VERSION ""

NS_ :

BS_:

BU_: AVM_SD CGW IVI eHBox

BO_ 32 ACU_A102: 8 CGW
  SG_ AirbagCrashOrder_v3 : 5|6@0+ (1,0) [0|0] "" IVI

BO_ 116 ECM_A110: 8 CGW
  SG_ PowerTrainSetPoint : 11|10@0+ (0.125,0) [0|125] "%" IVI
  SG_ RawSensor : 17|10@0+ (0.125,0) [0|125] "%" IVI
  SG_ StopAutoPhase : 47|3@0+ (1,0) [0|0] "" IVI

BO_ 117 ECM_A112: 8 CGW
  SG_ ECM_EstimatedPWTWheelTorque : 11|15@0+ (2,-20000) [-20000|20000] "Nm" IVI
  SG_ PowerTrainStatus : 25|2@0+ (1,0) [0|0] "" IVI
  SG_ EngineRPM : 39|16@0+ (0.125,0) [0|8191.75] "rpm" IVI
  SG_ MeanEffectiveTorque : 55|12@0+ (0.5,-400) [-400|1647] "Nm" IVI

BO_ 168 STRG_A1: 7 CGW
  SG_ SteeringWheelAngleRaw : 22|15@0+ (0.1,-1080) [-1080|1080] "°" IVI
  SG_ SwaSensorInternalStatus : 39|3@0+ (1,0) [0|0] "" IVI
  SG_ SteeringWheelRotationSpeed : 47|16@0+ (0.1,-3276.7) [-3276.7|3276.7] "°/s" IVI

BO_ 171 VDC_A6: 8 CGW
  SG_ YawRateCorrected : 10|11@0+ (0.1,-100) [-100|100] "°/s" IVI
  SG_ BrakingPressure : 31|8@0+ (0.5,0) [0|126] "bar" IVI
  SG_ SteerRackPinionAngleCorrect : 39|15@0+ (0.1,-1080) [-1080|1080] "°" AVM_SD,IVI
  SG_ YawRateRaw : 55|11@0+ (0.1,-100) [-100|100] "°/s" eHBox

BO_ 180 VDC_A5: 8 CGW
  SG_ LongitudinalAccelCorrected : 23|12@0+ (0.001,-2) [-2|2] "G" IVI
  SG_ LongitudinalAccelRaw : 27|12@0+ (0.001,-2) [-2|2] "G" IVI,eHBox
  SG_ TransversalAccelCorrected : 47|12@0+ (0.001,-2) [-2|2] "G" IVI
  SG_ TransversalAccelRaw : 51|12@0+ (0.001,-2) [-2|2] "G" IVI,eHBox

BO_ 255 VDC_A10: 6 CGW
  SG_ BrakePedalPressedByDriver : 42|2@0+ (1,0) [0|0] "" IVI

BO_ 303 ATCU_A108: 7 CGW
  SG_ GearLeverPosition_v2 : 20|4@0+ (1,0) [0|0] "" AVM_SD,IVI

BO_ 380 STRG_A2: 7 CGW
  SG_ SwaSensorInternalStatus_EPS : 39|3@0+ (1,0) [0|0] "" IVI
  SG_ SteeringWheelRotationSpeed_EPS : 47|16@0+ (0.1,-3276.7) [-3276.7|3276.7] "°/s" IVI

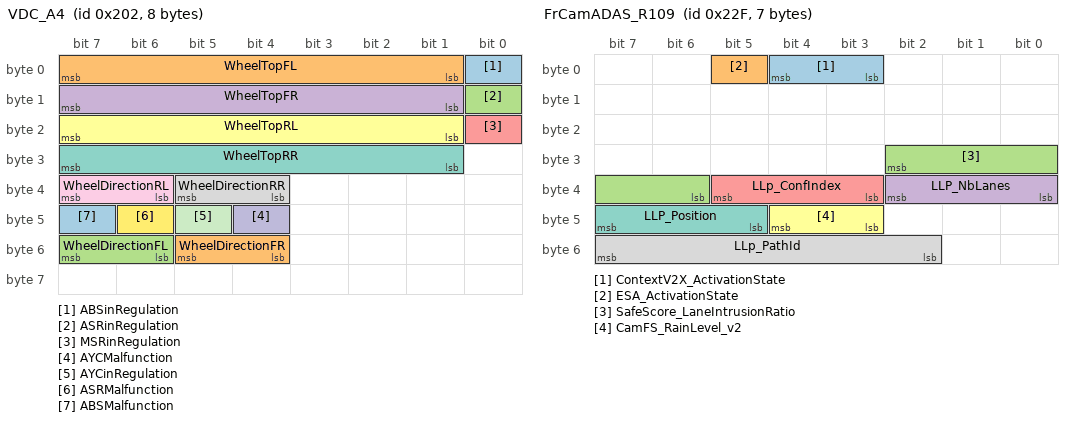
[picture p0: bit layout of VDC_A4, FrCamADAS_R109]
BO_ 514 VDC_A4: 8 CGW
  SG_ ABSinRegulation : 0|1@0+ (1,0) [0|0] "" IVI
  SG_ WheelTopFL : 7|7@0+ (1,0) [0|96] "top" IVI,eHBox
  SG_ ASRinRegulation : 8|1@0+ (1,0) [0|0] "" IVI
  SG_ WheelTopFR : 15|7@0+ (1,0) [0|96] "top" IVI,eHBox
  SG_ MSRinRegulation : 16|1@0+ (1,0) [0|0] "" IVI
  SG_ WheelTopRL : 23|7@0+ (1,0) [0|96] "top" IVI,eHBox
  SG_ WheelTopRR : 31|7@0+ (1,0) [0|96] "top" IVI,eHBox
  SG_ WheelDirectionRR : 37|2@0+ (1,0) [0|0] "" IVI,eHBox
  SG_ WheelDirectionRL : 39|2@0+ (1,0) [0|0] "" IVI,eHBox
  SG_ AYCMalfunction : 44|1@0+ (1,0) [0|0] "" IVI
  SG_ AYCinRegulation : 45|1@0+ (1,0) [0|0] "" IVI
  SG_ ASRMalfunction : 46|1@0+ (1,0) [0|0] "" IVI
  SG_ ABSMalfunction : 47|1@0+ (1,0) [0|0] "" IVI
  SG_ WheelDirectionFR : 53|2@0+ (1,0) [0|0] "" eHBox
  SG_ WheelDirectionFL : 55|2@0+ (1,0) [0|0] "" eHBox

BO_ 534 EPS_A101: 4 CGW
  SG_ EPSWarning : 19|2@0+ (1,0) [0|0] "" IVI

BO_ 545 FWD_A103: 4 CGW
  SG_ ETS_InternalOperationMode : 23|2@0+ (1,0) [0|0] "" IVI

BO_ 549 VDC_A115: 3 CGW
  SG_ StopLampFlashingRequest : 21|1@0+ (1,0) [0|0] "" IVI

BO_ 559 FrCamADAS_R109: 7 CGW
  SG_ ContextV2X_ActivationState : 4|2@0+ (1,0) [0|0] "" IVI
  SG_ ESA_ActivationState : 5|1@0+ (1,0) [0|0] "" IVI
  SG_ SafeScore_LaneIntrusionRatio : 26|5@0+ (0.05,0) [0|1] "-" IVI
  SG_ LLP_NbLanes : 34|3@0+ (1,0) [0|7] "-" IVI
  SG_ LLp_ConfIndex : 37|3@0+ (1,0) [0|7] "-" IVI
  SG_ CamFS_RainLevel_v2 : 44|2@0+ (1,0) [0|0] "" IVI
  SG_ LLP_Position : 47|3@0+ (1,0) [0|7] "-" IVI
  SG_ LLp_PathId : 55|6@0+ (1,0) [0|63] "-" IVI

BO_ 578 FrCamADAS_R113: 2 CGW
  SG_ V2X_EventDetection : 12|5@0+ (1,0) [0|0] "" IVI

BO_ 606 ADASISv2_A101: 8 IVI
  SG_ ADASISv2_ShortRang : 7|64@0+ (1,0) [0|0] "" CGW

BO_ 649 VDC_A3: 8 CGW
  SG_ WheelSpeedRL : 23|16@0+ (0.0416666667,0) [0|2730.583333] "rpm" IVI
  SG_ WheelSpeedRR : 39|16@0+ (0.0416666667,0) [0|2730.583333] "rpm" IVI
  SG_ VehicleSpeedBody : 55|16@0+ (0.01,0) [0|655.34] "km/h" IVI

BO_ 650 VDC_A9: 8 CGW
  SG_ WheelSpeedFR : 7|16@0+ (0.0416666667,0) [0|2730.583333] "rpm" IVI
  SG_ WheelSpeedFL : 23|16@0+ (0.0416666667,0) [0|2730.583333] "rpm" IVI
  SG_ VehicleSpeed : 39|16@0+ (0.01,0) [0|655.34] "km/h" AVM_SD,IVI,eHBox

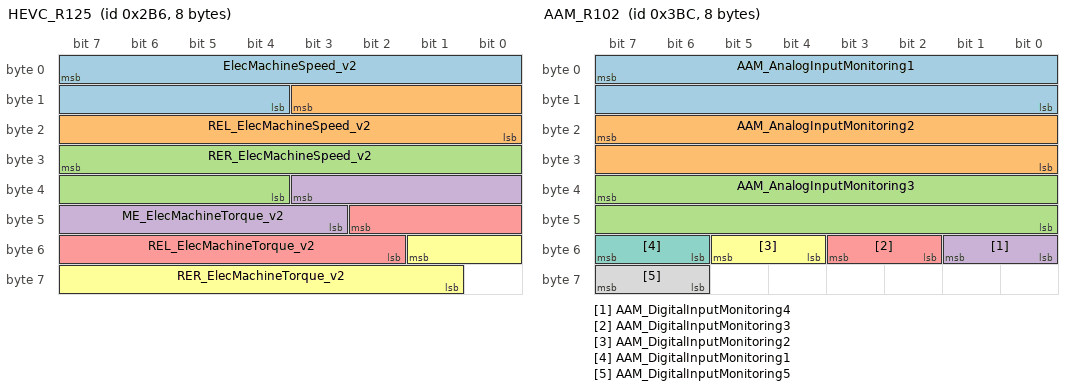
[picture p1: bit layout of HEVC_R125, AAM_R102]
BO_ 694 HEVC_R125: 8 CGW
  SG_ ElecMachineSpeed_v2 : 7|12@0+ (10,-20000) [-20000|20000] "rpm" IVI
  SG_ REL_ElecMachineSpeed_v2 : 11|12@0+ (10,-20000) [-20000|20000] "rpm" IVI
  SG_ RER_ElecMachineSpeed_v2 : 31|12@0+ (10,-20000) [-20000|20000] "rpm" IVI
  SG_ ME_ElecMachineTorque_v2 : 35|9@0+ (2,-300) [-300|500] "Nm" IVI
  SG_ REL_ElecMachineTorque_v2 : 42|9@0+ (2,-300) [-300|500] "Nm" IVI
  SG_ RER_ElecMachineTorque_v2 : 49|9@0+ (2,-300) [-300|500] "Nm" IVI

BO_ 698 ADASISv2_A111: 8 IVI
  SG_ ADASISv2_EHorizon : 7|64@0+ (1,0) [0|0] "" CGW

BO_ 699 VDC_R102: 5 CGW
  SG_ DriverBrakingPressure_MMI : 7|10@0+ (0.03,-3) [-3|27.66] "MPa" IVI
  SG_ LeftDrivenWheelSlip_MMI : 13|5@0+ (5,0) [0|100] "%" IVI
  SG_ RightDrivenWheelSlip_MMI : 23|5@0+ (5,0) [0|100] "%" IVI
  SG_ Rr_LeftDrivenWheelSlip_MMI : 31|5@0+ (5,0) [0|100] "%" IVI
  SG_ Rr_RightDrivenWheelSlip_MMI : 39|5@0+ (5,0) [0|100] "%" IVI

BO_ 703 HEVC_R127: 6 CGW
  SG_ Fr_EstimatedPWTWheelTorque_MMI : 7|15@0+ (2,-20000) [-20000|20000] "Nm" IVI
  SG_ Rr_L_EstimatedPWTWheelTorque_MMI : 23|15@0+ (2,-20000) [-20000|20000] "Nm" IVI
  SG_ Rr_R_EstimatedPWTWheelTorque_MMI : 39|15@0+ (2,-20000) [-20000|20000] "Nm" IVI

BO_ 711 TCU_A105: 8 CGW
  SG_ PnCcertificateDataBlockNumber_v2 : 51|12@0+ (1,0) [0|4095] "" IVI

BO_ 747 EDL_A101: 2 CGW
  SG_ DiffLock_IndicatorSignal : 4|2@0+ (1,0) [0|0] "" IVI

BO_ 791 HVAC_A1: 8 CGW
  SG_ ISS_EcoActivationState : 43|2@0+ (1,0) [0|0] "" IVI
  SG_ AirCondEcoActivationState : 45|2@0+ (1,0) [0|0] "" IVI
  SG_ ClimECOModeStatusDisplay : 52|2@0+ (1,0) [0|0] "" IVI

BO_ 806 USM_R3: 2 CGW
  SG_ FrontHeightBody : 7|8@0+ (1.5,-190.5) [-190.5|190.5] "mm" IVI
  SG_ RearHeightBody : 15|8@0+ (1.5,-190.5) [-190.5|190.5] "mm" IVI

BO_ 823 HVAC_R4: 5 CGW
  SG_ IoniserAutoLaunchState : 7|2@0+ (1,0) [0|0] "" IVI
  SG_ AQMAirFreshenerDisplayRequest : 9|2@0+ (1,0) [0|0] "" IVI
  SG_ ClimForcedRecyDisplay : 17|2@0+ (1,0) [0|0] "" IVI
  SG_ AQMIoniserModeState : 29|3@0+ (1,0) [0|0] "" IVI
  SG_ ClimAutoRecyclingDisplay : 31|2@0+ (1,0) [0|0] "" IVI

BO_ 874 ADASISv2_A107: 8 IVI
  SG_ ADASISv2_LongRang_AD2 : 7|64@0+ (1,0) [0|0] "" CGW

BO_ 877 ADASISv2_A108: 8 IVI
  SG_ ADASISv2_SEGMENT_AD2 : 7|64@0+ (1,0) [0|0] "" CGW

BO_ 880 ADASISv2_A109: 8 IVI
  SG_ ADASISv2_STUB_AD2 : 7|64@0+ (1,0) [0|0] "" CGW

BO_ 893 EPS_A103: 3 CGW
  SG_ LDW_VibrationIntensityState : 2|2@0+ (1,0) [0|0] "" IVI
  SG_ LCA_SteeringStatus2 : 7|2@0+ (1,0) [0|0] "" IVI

BO_ 928 ADASISv2_A102: 8 IVI
  SG_ ADASISv2_LongRang : 7|64@0+ (1,0) [0|0] "" CGW

BO_ 929 ADASISv2_A104: 8 IVI
  SG_ ADASISv2_SEGMENT : 7|64@0+ (1,0) [0|0] "" CGW

BO_ 931 ADASISv2_A105: 8 IVI
  SG_ ADASISv2_STUB : 7|64@0+ (1,0) [0|0] "" CGW

BO_ 934 AVM_A120: 3 CGW
  SG_ APA_StatusDisplay2 : 11|2@0+ (1,0) [0|0] "" IVI

BO_ 938 IVI_N112: 2 IVI
  SG_ SysSelectIntensityReq : 0|5@0+ (5,0) [0|100] "%" CGW
  SG_ SysSelectAmbiLightColorReq : 7|7@0+ (1,0) [0|0] "" CGW

BO_ 944 BCM_A117: 3 CGW
  SG_ HeavyRain_Status : 19|1@0+ (1,0) [0|0] "" IVI

BO_ 955 ECM_R102: 8 CGW
  SG_ RST_Boost_Duration_MMI : 7|7@0+ (1,0) [0|100] "%" IVI
  SG_ RST_Boost_Activation_MMI : 15|2@0+ (1,0) [0|0] "" IVI
  SG_ RST_Boost_Potential_MMI : 39|7@0+ (1,0) [0|100] "%" IVI
  SG_ ERP_AutonomyMessageDisplay : 58|1@0+ (1,0) [0|0] "" IVI

BO_ 956 AAM_R102: 8 CGW
  SG_ AAM_AnalogInputMonitoring1 : 7|16@0+ (1,0) [0|65534] "wu" IVI
  SG_ AAM_AnalogInputMonitoring2 : 23|16@0+ (1,0) [0|65534] "wu" IVI
  SG_ AAM_AnalogInputMonitoring3 : 39|16@0+ (1,0) [0|65534] "wu" IVI
  SG_ AAM_DigitalInputMonitoring4 : 49|2@0+ (1,0) [0|0] "" IVI
  SG_ AAM_DigitalInputMonitoring3 : 51|2@0+ (1,0) [0|0] "" IVI
  SG_ AAM_DigitalInputMonitoring2 : 53|2@0+ (1,0) [0|0] "" IVI
  SG_ AAM_DigitalInputMonitoring1 : 55|2@0+ (1,0) [0|0] "" IVI
  SG_ AAM_DigitalInputMonitoring5 : 63|2@0+ (1,0) [0|0] "" IVI

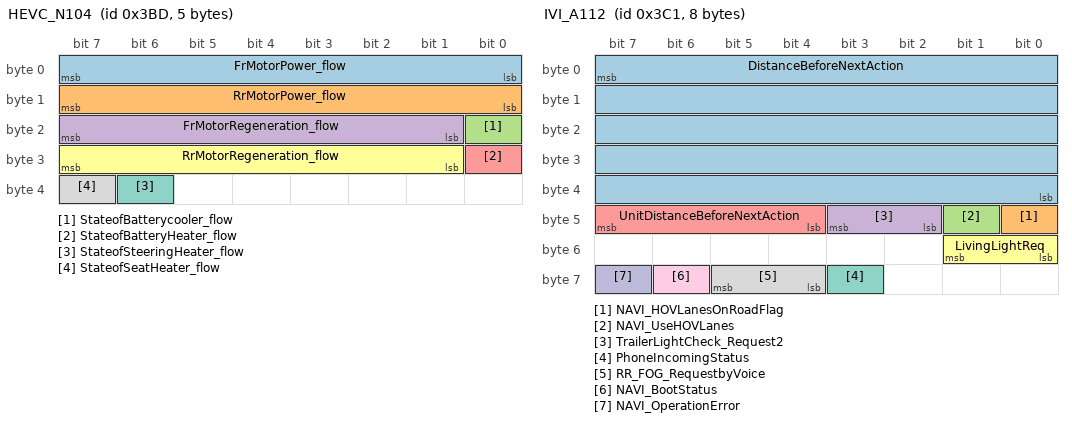
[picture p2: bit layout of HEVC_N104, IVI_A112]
BO_ 957 HEVC_N104: 5 CGW
  SG_ FrMotorPower_flow : 7|8@0+ (1,0) [0|200] "kW" IVI
  SG_ RrMotorPower_flow : 15|8@0+ (1,0) [0|200] "kW" IVI
  SG_ StateofBatterycooler_flow : 16|1@0+ (1,0) [0|0] "" IVI
  SG_ FrMotorRegeneration_flow : 23|7@0+ (1,0) [0|100] "kW" IVI
  SG_ StateofBatteryHeater_flow : 24|1@0+ (1,0) [0|0] "" IVI
  SG_ RrMotorRegeneration_flow : 31|7@0+ (1,0) [0|100] "kW" IVI
  SG_ StateofSteeringHeater_flow : 38|1@0+ (1,0) [0|0] "" IVI
  SG_ StateofSeatHeater_flow : 39|1@0+ (1,0) [0|0] "" IVI

BO_ 961 IVI_A112: 8 IVI
  SG_ DistanceBeforeNextAction : 7|40@0+ (1,0) [0|0] "" CGW
  SG_ NAVI_HOVLanesOnRoadFlag : 40|1@0+ (1,0) [0|0] "" CGW
  SG_ NAVI_UseHOVLanes : 41|1@0+ (1,0) [0|0] "" CGW
  SG_ TrailerLightCheck_Request2 : 43|2@0+ (1,0) [0|0] "" CGW
  SG_ UnitDistanceBeforeNextAction : 47|4@0+ (1,0) [0|0] "" CGW
  SG_ LivingLightReq : 49|2@0+ (1,0) [0|0] "" CGW
  SG_ PhoneIncomingStatus : 59|1@0+ (1,0) [0|0] "" CGW
  SG_ RR_FOG_RequestbyVoice : 61|2@0+ (1,0) [0|0] "" CGW
  SG_ NAVI_BootStatus : 62|1@0+ (1,0) [0|0] "" CGW
  SG_ NAVI_OperationError : 63|1@0+ (1,0) [0|0] "" CGW

BO_ 962 SONAR_A118: 4 CGW
  SG_ APA_StatusDisplay : 11|2@0+ (1,0) [0|0] "" IVI

BO_ 967 IVI_A5: 8 IVI
  SG_ CDisplayAvailability : 1|2@0+ (1,0) [0|0] "" CGW
  SG_ AutoACC2_ON_Request_MM : 3|2@0+ (1,0) [0|0] "" CGW
  SG_ Audio_WorkingAuthorize : 5|2@0+ (1,0) [0|0] "" CGW
  SG_ IVI_RefusetoSleep : 7|2@0+ (1,0) [0|0] "" CGW
  SG_ SonarSystemPauseRequest2 : 8|1@0+ (1,0) [0|0] "" CGW
  SG_ IVI_InitializationState : 9|1@0+ (1,0) [0|0] "" CGW
  SG_ MMCustomerAction : 12|3@0+ (1,0) [0|6] "" CGW
  SG_ UserFeedbackAvailability : 13|1@0+ (1,0) [0|0] "" CGW
  SG_ AudioAvailability : 14|1@0+ (1,0) [0|0] "" CGW
  SG_ SwitchRequest_AVM : 16|1@0+ (1,0) [0|0] "" AVM_SD,CGW
  SG_ ChangeViewRequest_AVM : 18|2@0+ (1,0) [0|0] "" CGW
  SG_ VehicleGPSreliability : 31|7@0+ (1,0) [0|127] "" CGW
  SG_ PassengerHeatingRequest : 33|2@0+ (1,0) [0|0] "" CGW
  SG_ TPMS_ResetDriverRequest2 : 44|2@0+ (1,0) [0|0] "" CGW
  SG_ TPW_ResetDriverRequest2 : 47|2@0+ (1,0) [0|0] "" CGW
  SG_ SatelliteGPSNumber : 55|7@0+ (1,0) [0|126] "wu" CGW
  SG_ EcoPedalForceSettingRequest : 58|2@0+ (1,0) [0|0] "" CGW
  SG_ HUD_UpDownRequest2 : 60|2@0+ (1,0) [0|0] "" CGW
  SG_ IVI_ParkAssistVolumeState : 63|3@0+ (1,0) [0|0] "" CGW

BO_ 969 HEVC_M101: 1 CGW
  SG_ TorqueDistributionRatioDisplay : 7|8@0+ (0.5,0) [0|100] "%" IVI

BO_ 970 BLM_A101: 1 CGW
  SG_ VirtualKeyState : 4|1@0+ (1,0) [0|0] "" IVI

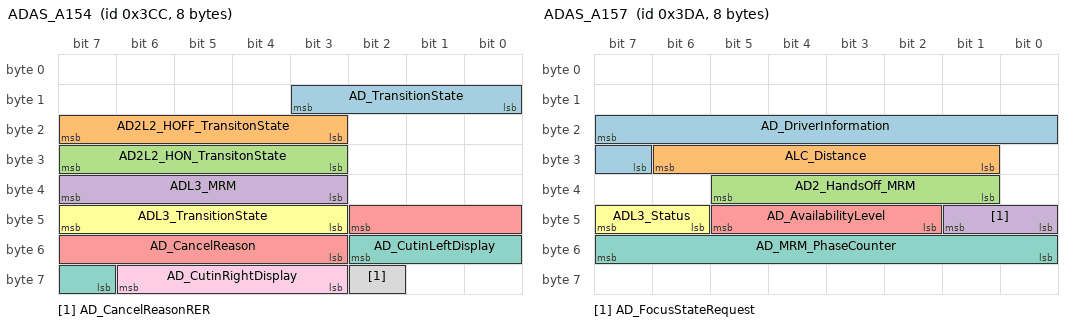
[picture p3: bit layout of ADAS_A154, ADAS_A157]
BO_ 972 ADAS_A154: 8 CGW
  SG_ AD_TransitionState : 11|4@0+ (1,0) [0|0] "" IVI
  SG_ AD2L2_HOFF_TransitonState : 23|5@0+ (1,0) [0|0] "" IVI
  SG_ AD2L2_HON_TransitonState : 31|5@0+ (1,0) [0|0] "" IVI
  SG_ ADL3_MRM : 39|5@0+ (1,0) [0|0] "" IVI
  SG_ AD_CancelReason : 42|8@0+ (1,0) [0|255] "CancelReason" IVI
  SG_ ADL3_TransitionState : 47|5@0+ (1,0) [0|0] "" IVI
  SG_ AD_CutinLeftDisplay : 50|4@0+ (1,0) [0|0] "" IVI
  SG_ AD_CancelReasonRER : 58|1@0+ (1,0) [0|0] "" IVI
  SG_ AD_CutinRightDisplay : 62|4@0+ (1,0) [0|0] "" IVI

BO_ 973 ADASISv2_A110: 8 IVI
  SG_ AD2_VehicleLocator : 7|64@0+ (1,0) [0|0] "" CGW

BO_ 978 IVI_R13: 8 IVI
  SG_ MMI_Req_PWM_Freq_func12 : 7|8@0+ (2,0) [0|510] "Hz" CGW
  SG_ MMI_Req_PWM_Freq_func13 : 15|8@0+ (2,0) [0|510] "Hz" CGW
  SG_ MMI_Req_PWM_Freq_func14 : 23|8@0+ (2,0) [0|510] "Hz" CGW
  SG_ MMI_Req_PWM_Freq_func15 : 31|8@0+ (2,0) [0|510] "Hz" CGW
  SG_ MMI_Req_PWM_Freq_func16 : 39|8@0+ (2,0) [0|510] "Hz" CGW
  SG_ MMI_Req_PWM_Freq_func17 : 47|8@0+ (2,0) [0|510] "Hz" CGW
  SG_ MMI_Req_PWM_DC_func16 : 55|8@0+ (0.5,0) [0|100] "%" CGW
  SG_ MMI_Req_PWM_DC_func17 : 63|8@0+ (0.5,0) [0|100] "%" CGW

BO_ 986 ADAS_A157: 8 CGW
  SG_ AD_DriverInformation : 23|9@0+ (1,0) [0|511] "Instruction" IVI
  SG_ ALC_Distance : 30|6@0+ (100,-100) [0|6000] "m" IVI
  SG_ AD2_HandsOff_MRM : 37|5@0+ (1,0) [0|0] "" IVI
  SG_ AD_FocusStateRequest : 41|2@0+ (1,0) [0|0] "" IVI
  SG_ AD_AvailabilityLevel : 45|4@0+ (1,0) [0|0] "" IVI
  SG_ ADL3_Status : 47|2@0+ (1,0) [0|0] "" IVI
  SG_ AD_MRM_PhaseCounter : 55|8@0+ (0.2,-0.2) [0|50.6] "s" IVI

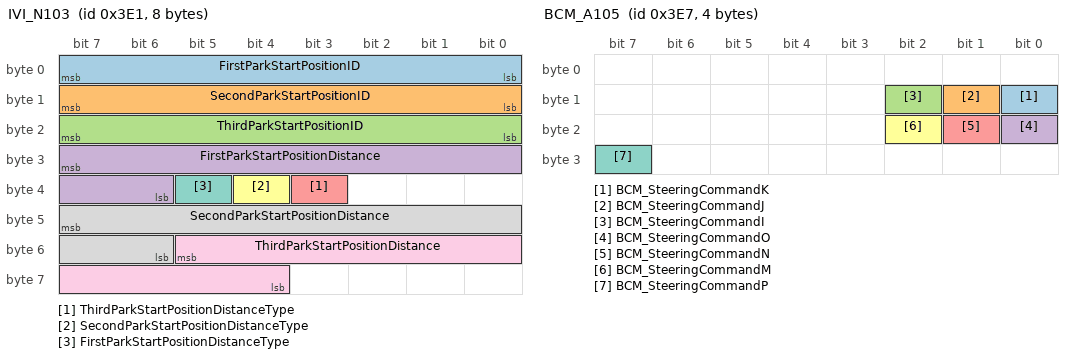
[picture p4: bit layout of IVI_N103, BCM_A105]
BO_ 993 IVI_N103: 8 IVI
  SG_ FirstParkStartPositionID : 7|8@0+ (1,0) [0|255] "-" CGW
  SG_ SecondParkStartPositionID : 15|8@0+ (1,0) [0|255] "-" CGW
  SG_ ThirdParkStartPositionID : 23|8@0+ (1,0) [0|255] "-" CGW
  SG_ FirstParkStartPositionDistance : 31|10@0+ (1,0) [0|1023] "m" CGW
  SG_ ThirdParkStartPositionDistanceType : 35|1@0+ (1,0) [0|0] "-" CGW
  SG_ SecondParkStartPositionDistanceType : 36|1@0+ (1,0) [0|0] "-" CGW
  SG_ FirstParkStartPositionDistanceType : 37|1@0+ (1,0) [0|0] "-" CGW
  SG_ SecondParkStartPositionDistance : 47|10@0+ (1,0) [0|1023] "m" CGW
  SG_ ThirdParkStartPositionDistance : 53|10@0+ (1,0) [0|1023] "m" CGW

BO_ 994 FWS_A102: 1 CGW
  SG_ a4WS_AnglePosition_v2 : 7|7@0+ (0.1,-5) [-5|5] "deg" IVI

BO_ 996 DSMU_A101: 3 CGW
  SG_ DriverSeatStatus : 9|2@0+ (1,0) [0|0] "" IVI
  SG_ DriverMassageProgramState_v3 : 20|4@0+ (1,0) [0|0] "" IVI

BO_ 999 BCM_A105: 4 CGW
  SG_ BCM_SteeringCommandK : 8|1@0+ (1,0) [0|0] "" IVI
  SG_ BCM_SteeringCommandJ : 9|1@0+ (1,0) [0|0] "" IVI
  SG_ BCM_SteeringCommandI : 10|1@0+ (1,0) [0|0] "" IVI
  SG_ BCM_SteeringCommandO : 16|1@0+ (1,0) [0|0] "" IVI
  SG_ BCM_SteeringCommandN : 17|1@0+ (1,0) [0|0] "" IVI
  SG_ BCM_SteeringCommandM : 18|1@0+ (1,0) [0|0] "" IVI
  SG_ BCM_SteeringCommandP : 31|1@0+ (1,0) [0|0] "" IVI

BO_ 1000 HFM_A101: 7 CGW
  SG_ APPRUN_ActivationState : 12|1@0+ (1,0) [0|0] "" IVI
  SG_ WAL_ActivationState : 13|1@0+ (1,0) [0|0] "" IVI
  SG_ IKeyAccessActivationState : 18|1@0+ (1,0) [0|0] "" IVI

BO_ 1001 PSCU_A102: 1 CGW
  SG_ PassengerMassageProgramState_v3 : 3|4@0+ (1,0) [0|0] "" IVI

BO_ 1003 ADAS_A139: 8 CGW
  SG_ AD_SteeringWheelTakeOverAlert : 27|3@0+ (1,0) [0|0] "" IVI
  SG_ AD_StatusDisplay : 31|4@0+ (1,0) [0|0] "" IVI
  SG_ ALC_HandsRequest : 33|2@0+ (1,0) [0|0] "" IVI
  SG_ ADL3_Warning : 55|8@0+ (1,0) [0|255] "Warning" IVI
  SG_ ALC_StatusDisplay : 58|3@0+ (1,0) [0|0] "" IVI

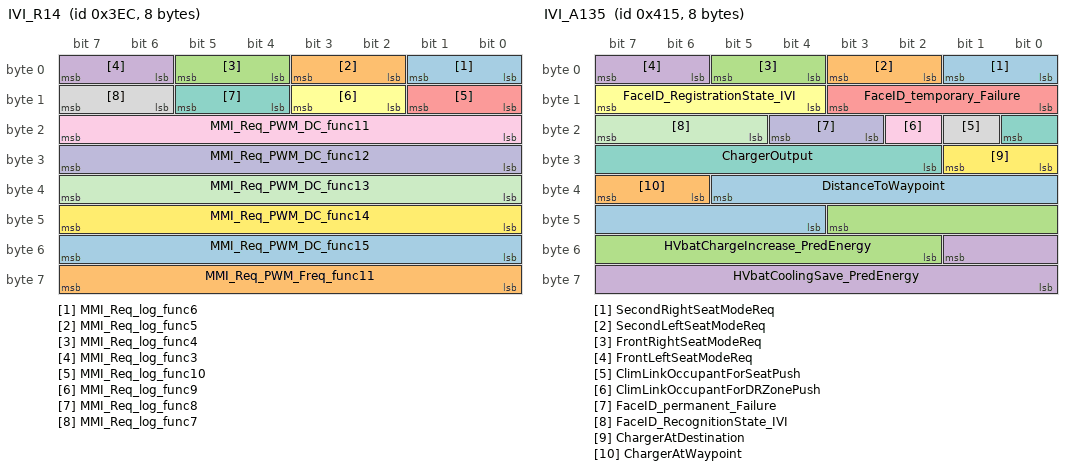
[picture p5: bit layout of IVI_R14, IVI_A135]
BO_ 1004 IVI_R14: 8 IVI
  SG_ MMI_Req_log_func6 : 1|2@0+ (1,0) [0|0] "" CGW
  SG_ MMI_Req_log_func5 : 3|2@0+ (1,0) [0|0] "" CGW
  SG_ MMI_Req_log_func4 : 5|2@0+ (1,0) [0|0] "" CGW
  SG_ MMI_Req_log_func3 : 7|2@0+ (1,0) [0|0] "" CGW
  SG_ MMI_Req_log_func10 : 9|2@0+ (1,0) [0|0] "" CGW
  SG_ MMI_Req_log_func9 : 11|2@0+ (1,0) [0|0] "" CGW
  SG_ MMI_Req_log_func8 : 13|2@0+ (1,0) [0|0] "" CGW
  SG_ MMI_Req_log_func7 : 15|2@0+ (1,0) [0|0] "" CGW
  SG_ MMI_Req_PWM_DC_func11 : 23|8@0+ (0.5,0) [0|100] "%" CGW
  SG_ MMI_Req_PWM_DC_func12 : 31|8@0+ (0.5,0) [0|100] "%" CGW
  SG_ MMI_Req_PWM_DC_func13 : 39|8@0+ (0.5,0) [0|100] "%" CGW
  SG_ MMI_Req_PWM_DC_func14 : 47|8@0+ (0.5,0) [0|100] "%" CGW
  SG_ MMI_Req_PWM_DC_func15 : 55|8@0+ (0.5,0) [0|100] "%" CGW
  SG_ MMI_Req_PWM_Freq_func11 : 63|8@0+ (2,0) [0|510] "Hz" CGW

BO_ 1008 IVI_R15: 8 IVI
  SG_ MMI_Req_log_func2 : 5|2@0+ (1,0) [0|0] "" CGW
  SG_ MMI_Req_log_func1 : 7|2@0+ (1,0) [0|0] "" CGW

BO_ 1012 TCU_A101: 7 CGW
  SG_ TCU_MuteRadioOrder : 5|1@0+ (1,0) [0|0] "" IVI
  SG_ IVC_FOTAbusyFlag : 15|1@0+ (1,0) [0|0] "" IVI
  SG_ IVC_FOTA_Status_v2 : 36|5@0+ (1,0) [0|0] "" IVI
  SG_ IVC_FOTA_Progress_v2 : 47|7@0+ (1,0) [0|100] "%" IVI
  SG_ ECALL_StateDisplay_V4 : 55|4@0+ (1,0) [0|0] "" IVI

BO_ 1017 UTA_R1: 2 CGW
  SG_ UTA_VigilanceLevelDisplay : 5|4@0+ (1,0) [0|0] "" IVI
  SG_ UTA_VigilanceAlertDisplay_v2 : 15|2@0+ (1,0) [0|0] "" IVI

BO_ 1028 VSP_A101: 1 CGW
  SG_ VSPSoundActivationState : 4|1@0+ (1,0) [0|0] "" IVI
  SG_ VSPsoundChoiceActivationState : 7|3@0+ (1,0) [0|0] "" IVI

BO_ 1045 IVI_A135: 8 IVI
  SG_ SecondRightSeatModeReq : 1|2@0+ (1,0) [0|0] "" CGW
  SG_ SecondLeftSeatModeReq : 3|2@0+ (1,0) [0|0] "" CGW
  SG_ FrontRightSeatModeReq : 5|2@0+ (1,0) [0|0] "" CGW
  SG_ FrontLeftSeatModeReq : 7|2@0+ (1,0) [0|0] "" CGW
  SG_ FaceID_temporary_Failure : 11|4@0+ (1,0) [0|0] "" CGW
  SG_ FaceID_RegistrationState_IVI : 15|4@0+ (1,0) [0|0] "" CGW
  SG_ ChargerOutput : 16|7@0+ (10,0) [0|1000] "kW" CGW
  SG_ ClimLinkOccupantForSeatPush : 17|1@0+ (1,0) [0|1] "-" CGW
  SG_ ClimLinkOccupantForDRZonePush : 18|1@0+ (1,0) [0|1] "-" CGW
  SG_ FaceID_permanent_Failure : 20|2@0+ (1,0) [0|0] "" CGW
  SG_ FaceID_RecognitionState_IVI : 23|3@0+ (1,0) [0|0] "" CGW
  SG_ ChargerAtDestination : 25|2@0+ (1,0) [0|0] "" CGW
  SG_ DistanceToWaypoint : 37|10@0+ (0.1,0) [0|100] "km" CGW
  SG_ ChargerAtWaypoint : 39|2@0+ (1,0) [0|0] "" CGW
  SG_ HVbatChargeIncrease_PredEnergy : 43|10@0+ (1,-500) [-500|500] "kW" CGW
  SG_ HVbatCoolingSave_PredEnergy : 49|10@0+ (1,-500) [-500|500] "kW" CGW

BO_ 1047 AVM_A119: 3 CGW
  SG_ AVM_WarningDisplayRequest : 7|3@0+ (1,0) [0|0] "" IVI
  SG_ HFP_ExtendedInstrContentDisplay2 : 23|5@0+ (1,0) [0|0] "" IVI

BO_ 1049 AAM_R101: 2 CGW
  SG_ MuteRadioOrderByAAM : 0|1@0+ (1,0) [0|0] "" IVI
  SG_ AAM_DigitalInputMonitoring7 : 10|2@0+ (1,0) [0|0] "" IVI
  SG_ AAM_DigitalInputMonitoring6 : 12|2@0+ (1,0) [0|0] "" IVI

BO_ 1058 FRCAMERA_A111: 5 CGW
  SG_ OSPSpeedUnit : 19|2@0+ (1,0) [0|0] "" IVI
  SG_ TSR_ConfidenceLevel : 39|3@0+ (20,0) [0|100] "%" IVI

BO_ 1064 HEVC_A104: 7 CGW
  SG_ EcoNavFuelSaving : 0|10@0+ (0.01,0) [0|10] "L" IVI
  SG_ HVbatteryTemperature : 7|7@0+ (1,-40) [-40|80] "°C" IVI
  SG_ VehicleAutonomyZEV : 22|10@0+ (1,0) [0|1022] "km" IVI

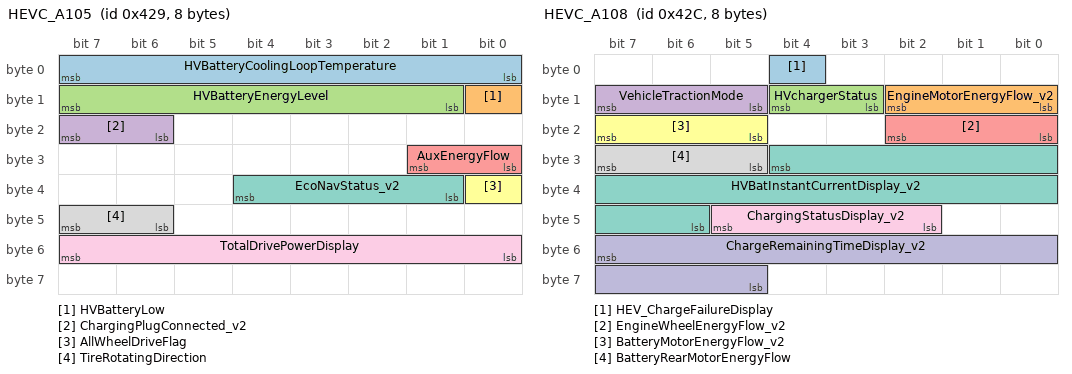
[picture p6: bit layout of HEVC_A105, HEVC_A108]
BO_ 1065 HEVC_A105: 8 CGW
  SG_ HVBatteryCoolingLoopTemperature : 7|8@0+ (1,-50) [-50|130] "°C" IVI
  SG_ HVBatteryLow : 8|1@0+ (1,0) [0|0] "" IVI
  SG_ HVBatteryEnergyLevel : 15|7@0+ (1,0) [0|100] "%" IVI
  SG_ ChargingPlugConnected_v2 : 23|2@0+ (1,0) [0|0] "" IVI
  SG_ AuxEnergyFlow : 25|2@0+ (1,0) [0|0] "" IVI
  SG_ AllWheelDriveFlag : 32|1@0+ (1,0) [0|0] "" IVI
  SG_ EcoNavStatus_v2 : 36|4@0+ (1,0) [0|0] "" IVI
  SG_ TireRotatingDirection : 47|2@0+ (1,0) [0|0] "" IVI
  SG_ TotalDrivePowerDisplay : 55|8@0+ (1,-100) [-100|120] "%" IVI

BO_ 1066 HEVC_A106: 8 CGW
  SG_ HVbatteryEmpty : 26|1@0+ (1,0) [0|0] "" IVI
  SG_ ElecMachineSpeed_EDR : 35|12@0+ (10,-20000) [-20000|20000] "rpm" IVI
  SG_ HVbatteryChargeType_v2 : 50|3@0+ (1,0) [0|0] "" IVI
  SG_ RegenBrakingLevelDisplay : 53|3@0+ (1,0) [0|0] "" IVI

BO_ 1068 HEVC_A108: 8 CGW
  SG_ HEV_ChargeFailureDisplay : 4|1@0+ (1,0) [0|0] "" IVI
  SG_ EngineMotorEnergyFlow_v2 : 10|3@0+ (1,0) [0|0] "" IVI
  SG_ HVchargerStatus : 12|2@0+ (1,0) [0|0] "" IVI
  SG_ VehicleTractionMode : 15|3@0+ (1,0) [0|0] "" IVI
  SG_ EngineWheelEnergyFlow_v2 : 18|3@0+ (1,0) [0|0] "" IVI
  SG_ BatteryMotorEnergyFlow_v2 : 23|3@0+ (1,0) [0|0] "" IVI
  SG_ HVBatInstantCurrentDisplay_v2 : 28|15@0+ (0.125,-1200) [-1200|1200] "A" IVI
  SG_ BatteryRearMotorEnergyFlow : 31|3@0+ (1,0) [0|0] "" IVI
  SG_ ChargingStatusDisplay_v2 : 45|4@0+ (1,0) [0|0] "" IVI
  SG_ ChargeRemainingTimeDisplay_v2 : 55|11@0+ (1,0) [0|2046] "min" IVI

BO_ 1070 HEVC_R101: 7 CGW
  SG_ UserSOC : 7|8@0+ (0.392157,0) [0|100] "%" IVI

BO_ 1071 HEVC_R103: 3 CGW
  SG_ HVBatteryEnergyCap_Reachability : 7|11@0+ (0.05,0) [0|100] "kWh" IVI
  SG_ AvailableEnergy_HEVC : 12|11@0+ (0.05,0) [0|100] "kWh" IVI

BO_ 1076 HFM_A104: 8 CGW
  SG_ SwitchOffSESDisturbers : 50|1@0+ (1,0) [0|0] "" IVI

BO_ 1081 VDC_A114: 7 CGW
  SG_ SlopeEstimation : 7|8@0+ (0.2,-15) [-15|15] "°" IVI
  SG_ DistanceTotalizer : 15|28@0+ (0.01,0) [0|2600000] "km" AVM_SD,IVI,eHBox
  SG_ TCS_DeactivationState : 32|1@0+ (1,0) [0|0] "" IVI

BO_ 1083 DVR_N3: 2 CGW
  SG_ DVR_FOTA_Status : 5|5@0+ (1,0) [0|0] "" IVI
  SG_ DVR_FOTA_Progress : 15|7@0+ (1,0) [0|100] "%" IVI

BO_ 1086 HVAC_A2: 8 CGW
  SG_ InputPower_AC_INV : 15|7@0+ (50,0) [0|5100] "W" IVI
  SG_ ePTCpower : 23|6@0+ (250,0) [0|10000] "W" IVI

BO_ 1099 ATCU_A109: 8 CGW
  SG_ ATCVT_RangeIndicationExtended : 44|6@0+ (1,0) [0|0] "" IVI
  SG_ ATCVTFail : 48|1@0+ (1,0) [0|0] "" AVM_SD

BO_ 1100 ATCU_A110: 6 CGW
  SG_ RST_LaunchControlReady : 11|2@0+ (1,0) [0|0] "" IVI
  SG_ TransmRangeEngaged_Current : 24|4@0+ (1,0) [0|0] "" IVI

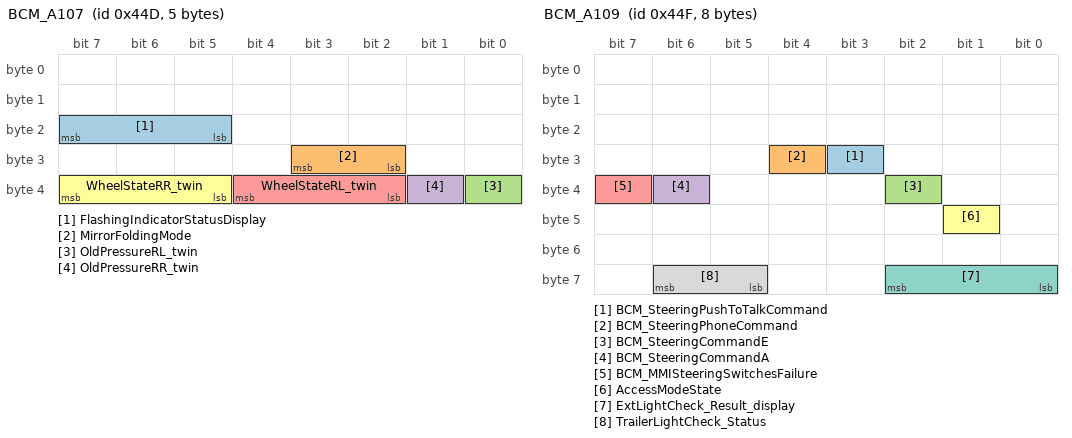
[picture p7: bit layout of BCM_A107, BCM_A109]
BO_ 1101 BCM_A107: 5 CGW
  SG_ FlashingIndicatorStatusDisplay : 23|3@0+ (1,0) [0|0] "" IVI
  SG_ MirrorFoldingMode : 27|2@0+ (1,0) [0|0] "" IVI
  SG_ OldPressureRL_twin : 32|1@0+ (1,0) [0|0] "" IVI
  SG_ OldPressureRR_twin : 33|1@0+ (1,0) [0|0] "" IVI
  SG_ WheelStateRL_twin : 36|3@0+ (1,0) [0|0] "" IVI
  SG_ WheelStateRR_twin : 39|3@0+ (1,0) [0|0] "" IVI

BO_ 1102 BCM_A108: 6 CGW
  SG_ AutoLockActivationState : 1|2@0+ (1,0) [0|0] "" IVI
  SG_ AutoLightSensitivityStatus : 3|2@0+ (1,0) [0|0] "" IVI
  SG_ AutoFrontWiperActivationStatus : 5|2@0+ (1,0) [0|0] "" IVI
  SG_ AHL_ActivationState : 7|2@0+ (1,0) [0|0] "" IVI
  SG_ RearWiperStatus : 9|2@0+ (1,0) [0|0] "" IVI
  SG_ AutoUnLockActivationState : 13|2@0+ (1,0) [0|0] "" IVI
  SG_ AmbientLightingPatternState : 14|1@0+ (1,0) [0|0] "" IVI
  SG_ AutoFMHactivationState : 15|1@0+ (1,0) [0|0] "" IVI
  SG_ AutoInternalLightingState : 16|1@0+ (1,0) [0|0] "" IVI
  SG_ AutoFMHdurationState : 19|3@0+ (1,0) [0|0] "" IVI
  SG_ ADB_ActivationState : 20|1@0+ (1,0) [0|0] "" IVI
  SG_ AutoReLockActivationState : 21|1@0+ (1,0) [0|0] "" IVI
  SG_ FrontRearWiperDropStatus : 22|1@0+ (1,0) [0|0] "" IVI
  SG_ WGSactivationState : 23|1@0+ (1,0) [0|0] "" IVI
  SG_ OtherLampActivateStatus : 24|1@0+ (1,0) [0|0] "" IVI
  SG_ LowBeamDisplay : 30|1@0+ (1,0) [0|0] "" IVI
  SG_ HighBeamDisplay : 31|1@0+ (1,0) [0|0] "" IVI
  SG_ AmbientLightingArea5Status : 35|1@0+ (1,0) [0|0] "" IVI
  SG_ AmbientLightingArea4Status : 36|1@0+ (1,0) [0|0] "" IVI
  SG_ RR_FOG_StatusbyVoice : 39|3@0+ (1,0) [0|0] "" IVI

BO_ 1103 BCM_A109: 8 CGW
  SG_ BCM_SteeringPushToTalkCommand : 27|1@0+ (1,0) [0|0] "" IVI
  SG_ BCM_SteeringPhoneCommand : 28|1@0+ (1,0) [0|0] "" IVI
  SG_ BCM_SteeringCommandE : 34|1@0+ (1,0) [0|0] "" IVI
  SG_ BCM_SteeringCommandA : 38|1@0+ (1,0) [0|0] "" IVI
  SG_ BCM_MMISteeringSwitchesFailure : 39|1@0+ (1,0) [0|0] "" IVI
  SG_ AccessModeState : 41|1@0+ (1,0) [0|0] "" IVI
  SG_ ExtLightCheck_Result_display : 58|3@0+ (1,0) [0|0] "" IVI
  SG_ TrailerLightCheck_Status : 62|2@0+ (1,0) [0|0] "" IVI

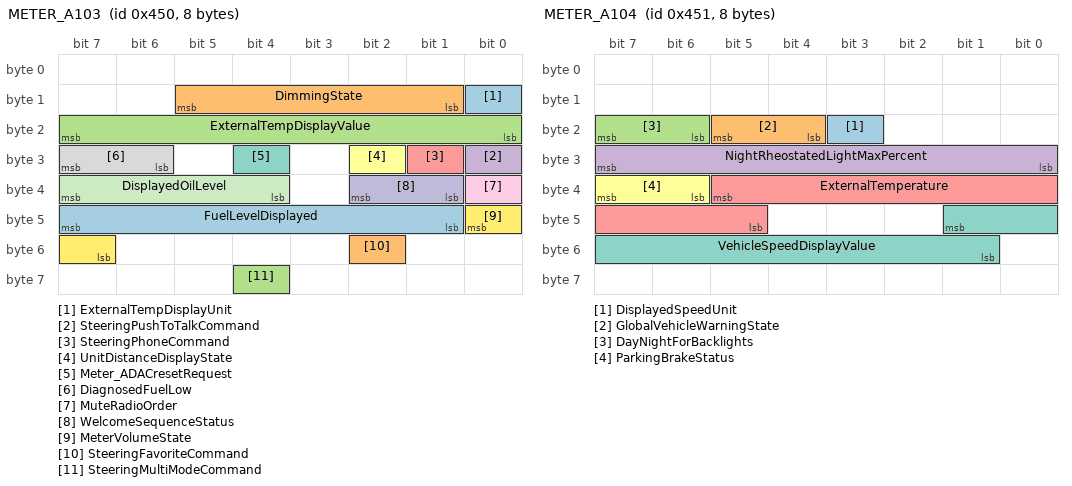
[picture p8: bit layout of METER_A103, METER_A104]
BO_ 1104 METER_A103: 8 CGW
  SG_ ExternalTempDisplayUnit : 8|1@0+ (1,0) [0|0] "" IVI
  SG_ DimmingState : 13|5@0+ (1,0) [0|0] "" IVI
  SG_ ExternalTempDisplayValue : 23|8@0+ (1,-40) [-40|140] "" IVI
  SG_ SteeringPushToTalkCommand : 24|1@0+ (1,0) [0|0] "" IVI
  SG_ SteeringPhoneCommand : 25|1@0+ (1,0) [0|0] "" IVI
  SG_ UnitDistanceDisplayState : 26|1@0+ (1,0) [0|0] "" IVI
  SG_ Meter_ADACresetRequest : 28|1@0+ (1,0) [0|0] "" IVI
  SG_ DiagnosedFuelLow : 31|2@0+ (1,0) [0|0] "" IVI
  SG_ MuteRadioOrder : 32|1@0+ (1,0) [0|0] "" IVI
  SG_ WelcomeSequenceStatus : 34|2@0+ (1,0) [0|0] "" IVI
  SG_ DisplayedOilLevel : 39|4@0+ (1,0) [0|0] "" IVI
  SG_ MeterVolumeState : 40|2@0+ (1,0) [0|0] "" IVI
  SG_ FuelLevelDisplayed : 47|7@0+ (1,0) [0|80] "L" IVI
  SG_ SteeringFavoriteCommand : 50|1@0+ (1,0) [0|0] "" IVI
  SG_ SteeringMultiModeCommand : 60|1@0+ (1,0) [0|0] "" IVI

BO_ 1105 METER_A104: 8 CGW
  SG_ DisplayedSpeedUnit : 19|1@0+ (1,0) [0|0] "" IVI
  SG_ GlobalVehicleWarningState : 21|2@0+ (1,0) [0|0] "" IVI
  SG_ DayNightForBacklights : 23|2@0+ (1,0) [0|0] "" IVI
  SG_ NightRheostatedLightMaxPercent : 31|8@0+ (0.4,0) [0|100] "%" IVI
  SG_ ExternalTemperature : 37|9@0+ (0.25,-50) [-50|70] "°C" IVI
  SG_ ParkingBrakeStatus : 39|2@0+ (1,0) [0|0] "" IVI
  SG_ VehicleSpeedDisplayValue : 41|9@0+ (1,0) [0|510] "" IVI

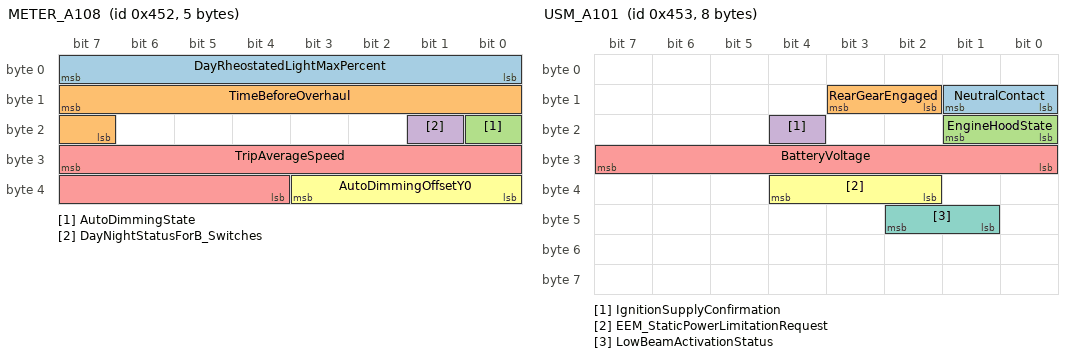
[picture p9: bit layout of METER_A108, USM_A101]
BO_ 1106 METER_A108: 5 CGW
  SG_ DayRheostatedLightMaxPercent : 7|8@0+ (0.4,0) [0|100] "%" IVI
  SG_ TimeBeforeOverhaul : 15|9@0+ (1,0) [0|511] "day" IVI
  SG_ AutoDimmingState : 16|1@0+ (1,0) [0|0] "" IVI
  SG_ DayNightStatusForB_Switches : 17|1@0+ (1,0) [0|0] "" IVI
  SG_ TripAverageSpeed : 31|12@0+ (0.1,0) [0|409.5] "" IVI
  SG_ AutoDimmingOffsetY0 : 35|4@0+ (1,0) [0|0] "" IVI

BO_ 1107 USM_A101: 8 CGW
  SG_ NeutralContact : 9|2@0+ (1,0) [0|0] "" AVM_SD,IVI
  SG_ RearGearEngaged : 11|2@0+ (1,0) [0|0] "" AVM_SD,IVI
  SG_ EngineHoodState : 17|2@0+ (1,0) [0|0] "" IVI
  SG_ IgnitionSupplyConfirmation : 20|1@0+ (1,0) [0|0] "" eHBox
  SG_ BatteryVoltage : 31|8@0+ (0.06,6) [6|18] "V" IVI,eHBox
  SG_ EEM_StaticPowerLimitationRequest : 36|3@0+ (1,0) [0|0] "" IVI
  SG_ LowBeamActivationStatus : 42|2@0+ (1,0) [0|0] "" IVI

BO_ 1108 USM_A103: 8 CGW
  SG_ HandDrivingActivationState : 0|1@0+ (1,0) [0|0] "" IVI
  SG_ LowBatteryVoltageDisplay : 15|2@0+ (1,0) [0|0] "" IVI
  SG_ AFS_ActivationState : 16|1@0+ (1,0) [0|0] "" IVI

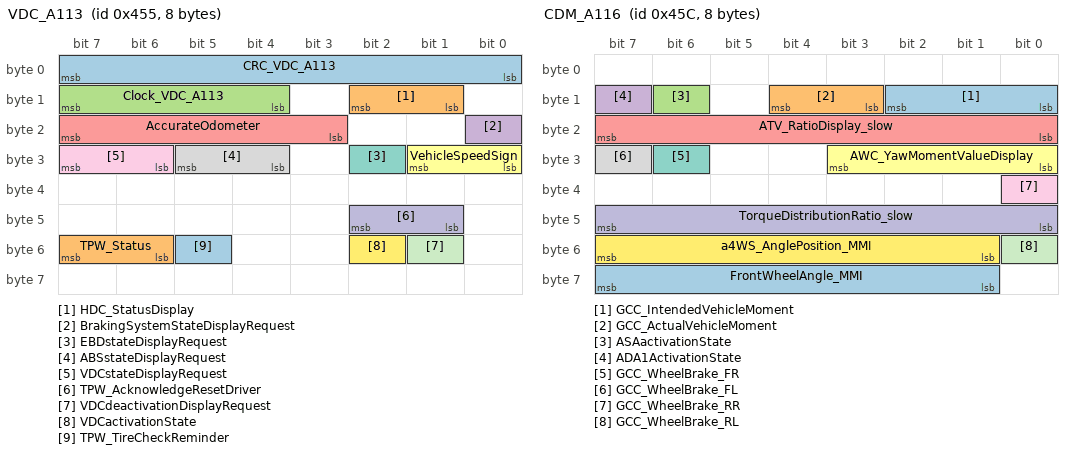
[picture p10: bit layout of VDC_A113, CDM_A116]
BO_ 1109 VDC_A113: 8 CGW
  SG_ CRC_VDC_A113 : 7|8@0+ (1,0) [0|255] "" IVI
  SG_ HDC_StatusDisplay : 10|2@0+ (1,0) [0|0] "" IVI
  SG_ Clock_VDC_A113 : 15|4@0+ (1,0) [0|15] "" IVI
  SG_ BrakingSystemStateDisplayRequest : 16|1@0+ (1,0) [0|0] "" IVI
  SG_ AccurateOdometer : 23|5@0+ (4,0) [0|120] "cm" IVI
  SG_ VehicleSpeedSign : 25|2@0+ (1,0) [0|0] "" IVI
  SG_ EBDstateDisplayRequest : 26|1@0+ (1,0) [0|0] "" IVI
  SG_ ABSstateDisplayRequest : 29|2@0+ (1,0) [0|0] "" IVI
  SG_ VDCstateDisplayRequest : 31|2@0+ (1,0) [0|0] "" IVI
  SG_ TPW_AcknowledgeResetDriver : 42|2@0+ (1,0) [0|0] "" IVI
  SG_ VDCdeactivationDisplayRequest : 49|1@0+ (1,0) [0|0] "" IVI
  SG_ VDCactivationState : 50|1@0+ (1,0) [0|0] "" IVI
  SG_ TPW_TireCheckReminder : 53|1@0+ (1,0) [0|0] "" IVI
  SG_ TPW_Status : 55|2@0+ (1,0) [0|0] "" IVI

BO_ 1116 CDM_A116: 8 CGW
  SG_ GCC_IntendedVehicleMoment : 10|3@0+ (1,0) [0|0] "" IVI
  SG_ GCC_ActualVehicleMoment : 12|2@0+ (1,0) [0|0] "" IVI
  SG_ ASAactivationState : 14|1@0+ (1,0) [0|0] "" IVI
  SG_ ADA1ActivationState : 15|1@0+ (1,0) [0|0] "" IVI
  SG_ ATV_RatioDisplay_slow : 23|8@0+ (0.5,0) [0|100] "%" IVI
  SG_ AWC_YawMomentValueDisplay : 27|4@0+ (1,-7) [-7|7] "" IVI
  SG_ GCC_WheelBrake_FR : 30|1@0+ (1,0) [0|0] "" IVI
  SG_ GCC_WheelBrake_FL : 31|1@0+ (1,0) [0|0] "" IVI
  SG_ GCC_WheelBrake_RR : 32|1@0+ (1,0) [0|0] "" IVI
  SG_ TorqueDistributionRatio_slow : 47|8@0+ (0.5,0) [0|100] "%" IVI
  SG_ GCC_WheelBrake_RL : 48|1@0+ (1,0) [0|0] "" IVI
  SG_ a4WS_AnglePosition_MMI : 55|7@0+ (0.1,-5) [-5|5] "deg" IVI
  SG_ FrontWheelAngle_MMI : 63|7@0+ (1,-50) [-50|50] "°" IVI

BO_ 1119 ECM_A108: 4 CGW
  SG_ EngineCoolantTemp : 23|8@0+ (1,-40) [-40|214] "°C" IVI

BO_ 1120 ECM_R101: 8 CGW
  SG_ AdvisorEconometer : 7|7@0+ (1,0) [0|127] "%" IVI
  SG_ AccelerationIndicator : 39|7@0+ (1,0) [0|127] "%" IVI
  SG_ FluentDrivingIndicator : 47|7@0+ (1,0) [0|127] "%" IVI
  SG_ GSI_Respect : 55|7@0+ (1,0) [0|127] "%" IVI

BO_ 1121 AirSUSP_N101: 8 CGW
  SG_ AirSusp_IndicatorRequest : 60|4@0+ (1,0) [0|0] "" IVI

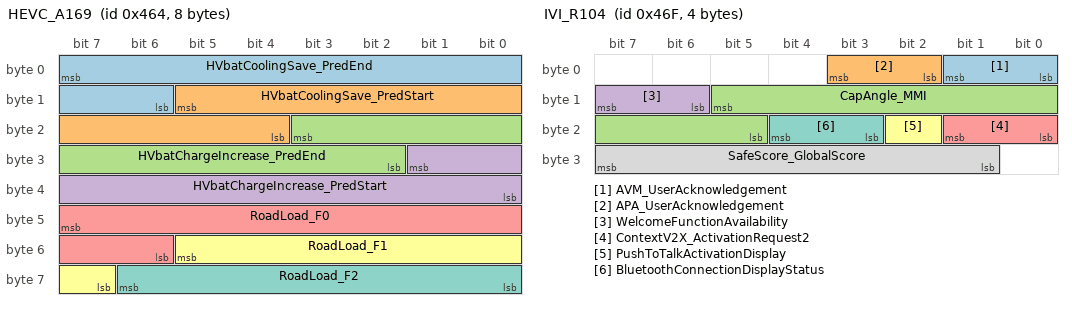
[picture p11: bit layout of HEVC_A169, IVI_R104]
BO_ 1124 HEVC_A169: 8 CGW
  SG_ HVbatCoolingSave_PredEnd : 7|10@0+ (0.1,0) [0|100] "km" IVI
  SG_ HVbatCoolingSave_PredStart : 13|10@0+ (0.1,0) [0|100] "km" IVI
  SG_ HVbatChargeIncrease_PredEnd : 19|10@0+ (0.1,0) [0|100] "km" IVI
  SG_ HVbatChargeIncrease_PredStart : 25|10@0+ (0.1,0) [0|100] "km" IVI
  SG_ RoadLoad_F0 : 47|10@0+ (1,0) [0|1000] "N" IVI
  SG_ RoadLoad_F1 : 53|7@0+ (0.01,0) [0|1] "N/(km/h)" IVI
  SG_ RoadLoad_F2 : 62|7@0+ (0.001,0) [0|0.1] "N/(km/h)^2" IVI

BO_ 1135 IVI_R104: 4 IVI
  SG_ AVM_UserAcknowledgement : 1|2@0+ (1,0) [0|0] "" CGW
  SG_ APA_UserAcknowledgement : 3|2@0+ (1,0) [0|0] "" CGW
  SG_ CapAngle_MMI : 13|9@0+ (1,0) [0|360] "°" CGW
  SG_ WelcomeFunctionAvailability : 15|2@0+ (1,0) [0|0] "" CGW
  SG_ ContextV2X_ActivationRequest2 : 17|2@0+ (1,0) [0|0] "" CGW
  SG_ PushToTalkActivationDisplay : 18|1@0+ (1,0) [0|0] "" CGW
  SG_ BluetoothConnectionDisplayStatus : 20|2@0+ (1,0) [0|0] "" CGW
  SG_ SafeScore_GlobalScore : 31|7@0+ (1,0) [0|100] "-" CGW

BO_ 1136 ECM_A107: 8 CGW
  SG_ EngineControlFailureLevel2 : 11|1@0+ (1,0) [0|0] "" IVI
  SG_ EngineControlFailureLevel1 : 32|1@0+ (1,0) [0|0] "" IVI

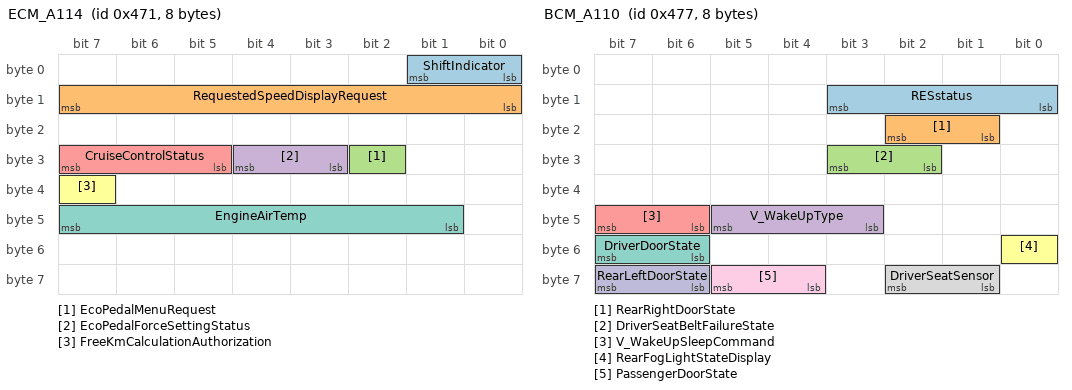
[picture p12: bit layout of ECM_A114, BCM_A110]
BO_ 1137 ECM_A114: 8 CGW
  SG_ ShiftIndicator : 1|2@0+ (1,0) [0|0] "" IVI
  SG_ RequestedSpeedDisplayRequest : 15|8@0+ (1,0) [0|253] "" IVI
  SG_ EcoPedalMenuRequest : 26|1@0+ (1,0) [0|0] "" IVI
  SG_ EcoPedalForceSettingStatus : 28|2@0+ (1,0) [0|0] "" IVI
  SG_ CruiseControlStatus : 31|3@0+ (1,0) [0|0] "" IVI
  SG_ FreeKmCalculationAuthorization : 39|1@0+ (1,0) [0|0] "" IVI
  SG_ EngineAirTemp : 47|7@0+ (1,-40) [-40|86] "°C" IVI

BO_ 1138 ECM_A116: 8 CGW
  SG_ SailingActivationIdleStatus : 8|1@0+ (1,0) [0|0] "" IVI
  SG_ PredictiveShiftActivationState : 10|2@0+ (1,0) [0|0] "" IVI
  SG_ SailingStopActivationState : 11|1@0+ (1,0) [0|0] "" IVI
  SG_ CruiseEcoActivationState : 27|2@0+ (1,0) [0|0] "" IVI
  SG_ CCSL_CurrentRegulationSpeed : 50|8@0+ (1,0) [0|200] "Cluster speed unit" IVI

BO_ 1140 ADAS_A116: 8 CGW
  SG_ LKA_AlertStatus : 9|2@0+ (1,0) [0|0] "" IVI
  SG_ LKA_ActivationState : 20|2@0+ (1,0) [0|0] "" IVI
  SG_ LKA_SWheelTakeOverAlert_v3 : 23|3@0+ (1,0) [0|0] "" IVI

BO_ 1143 BCM_A110: 8 CGW
  SG_ RESstatus : 11|4@0+ (1,0) [0|0] "" IVI
  SG_ RearRightDoorState : 18|2@0+ (1,0) [0|0] "" IVI
  SG_ DriverSeatBeltFailureState : 27|2@0+ (1,0) [0|0] "" IVI
  SG_ V_WakeUpType : 45|3@0+ (1,0) [0|0] "" IVI
  SG_ V_WakeUpSleepCommand : 47|2@0+ (1,0) [0|0] "" IVI
  SG_ RearFogLightStateDisplay : 48|1@0+ (1,0) [0|0] "" IVI
  SG_ DriverDoorState : 55|2@0+ (1,0) [0|0] "" IVI
  SG_ DriverSeatSensor : 58|2@0+ (1,0) [0|0] "" IVI
  SG_ PassengerDoorState : 61|2@0+ (1,0) [0|0] "" IVI
  SG_ RearLeftDoorState : 63|2@0+ (1,0) [0|0] "" IVI

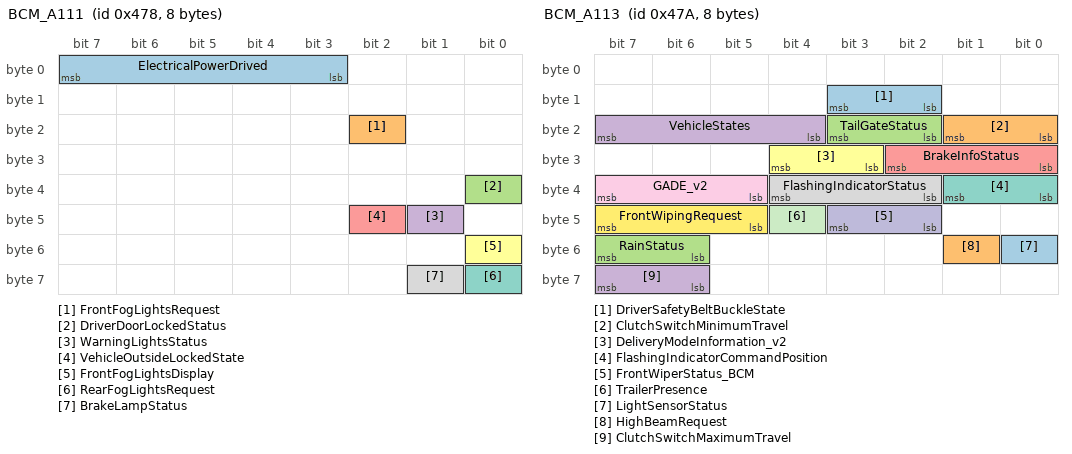
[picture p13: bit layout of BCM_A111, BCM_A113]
BO_ 1144 BCM_A111: 8 CGW
  SG_ ElectricalPowerDrived : 7|5@0+ (100,0) [0|3000] "W" IVI
  SG_ FrontFogLightsRequest : 18|1@0+ (1,0) [0|0] "" IVI
  SG_ DriverDoorLockedStatus : 32|1@0+ (1,0) [0|0] "" IVI
  SG_ WarningLightsStatus : 41|1@0+ (1,0) [0|0] "" IVI
  SG_ VehicleOutsideLockedState : 42|1@0+ (1,0) [0|0] "" IVI
  SG_ FrontFogLightsDisplay : 48|1@0+ (1,0) [0|0] "" IVI
  SG_ RearFogLightsRequest : 56|1@0+ (1,0) [0|0] "" IVI
  SG_ BrakeLampStatus : 57|1@0+ (1,0) [0|0] "" IVI

BO_ 1145 BCM_A112: 8 CGW
  SG_ SingleDoorOpeningActivationState : 0|1@0+ (1,0) [0|0] "" IVI
  SG_ BCM_PresoakRequest : 2|2@0+ (1,0) [0|0] "" IVI
  SG_ LeftSolarLevelInfo : 7|5@0+ (50,0) [0|1500] "W" IVI
  SG_ RightSolarLevelInfo : 15|5@0+ (50,0) [0|1500] "W" IVI
  SG_ DriverModeUpSwitchState : 17|1@0+ (1,0) [0|0] "" IVI
  SG_ SRU_Position : 23|4@0+ (1,0) [0|0] "" IVI
  SG_ WindowPosition_FR : 36|3@0+ (1,0) [0|0] "" IVI
  SG_ WindowPosition_FL : 39|3@0+ (1,0) [0|0] "" IVI
  SG_ ProbableCustomerFeedBackNeed : 41|1@0+ (1,0) [0|0] "" IVI
  SG_ WindowPosition_RR : 44|3@0+ (1,0) [0|0] "" IVI
  SG_ WindowPosition_RL : 47|3@0+ (1,0) [0|0] "" IVI
  SG_ DayNightSynthesis : 49|2@0+ (1,0) [0|0] "" IVI
  SG_ BackDoorLockedStatus : 50|1@0+ (1,0) [0|0] "" IVI
  SG_ AutoFoldingActivationState : 53|2@0+ (1,0) [0|0] "" IVI
  SG_ AutoACC2Status_MM : 55|2@0+ (1,0) [0|0] "" IVI
  SG_ RearRightDoorLockedStatus : 57|1@0+ (1,0) [0|0] "" IVI
  SG_ RearLeftDoorLockedStatus : 58|1@0+ (1,0) [0|0] "" IVI
  SG_ PassengerDoorLockedStatus : 59|1@0+ (1,0) [0|0] "" IVI
  SG_ MexSwitchState : 60|1@0+ (1,0) [0|0] "" IVI

BO_ 1146 BCM_A113: 8 CGW
  SG_ DriverSafetyBeltBuckleState : 11|2@0+ (1,0) [0|0] "" IVI
  SG_ ClutchSwitchMinimumTravel : 17|2@0+ (1,0) [0|0] "" IVI
  SG_ TailGateStatus : 19|2@0+ (1,0) [0|0] "" AVM_SD,IVI
  SG_ VehicleStates : 23|4@0+ (1,0) [0|0] "" AVM_SD,IVI,eHBox
  SG_ BrakeInfoStatus : 26|3@0+ (1,0) [0|0] "" IVI
  SG_ DeliveryModeInformation_v2 : 28|2@0+ (1,0) [0|0] "" AVM_SD,IVI,eHBox
  SG_ FlashingIndicatorCommandPosition : 33|2@0+ (1,0) [0|0] "" IVI
  SG_ FlashingIndicatorStatus : 36|3@0+ (1,0) [0|0] "" IVI
  SG_ GADE_v2 : 39|3@0+ (1,0) [0|0] "" AVM_SD,IVI,eHBox
  SG_ FrontWiperStatus_BCM : 43|2@0+ (1,0) [0|0] "" IVI
  SG_ TrailerPresence : 44|1@0+ (1,0) [0|0] "" IVI
  SG_ FrontWipingRequest : 47|3@0+ (1,0) [0|0] "" IVI
  SG_ LightSensorStatus : 48|1@0+ (1,0) [0|0] "" IVI
  SG_ HighBeamRequest : 49|1@0+ (1,0) [0|0] "" IVI
  SG_ RainStatus : 55|2@0+ (1,0) [0|0] "" IVI
  SG_ ClutchSwitchMaximumTravel : 63|2@0+ (1,0) [0|0] "" IVI

BO_ 1147 ECM_A105: 8 CGW
  SG_ EngineOilTempDisplay : 15|8@0+ (1,-50) [-50|204] "°C" IVI
  SG_ OilPressureWarning_ECM : 17|1@0+ (1,0) [0|0] "" IVI
  SG_ WarningWaterTemp : 18|1@0+ (1,0) [0|0] "" IVI
  SG_ FuelConsumption : 31|8@0+ (80,0) [0|20400] "mm3" IVI

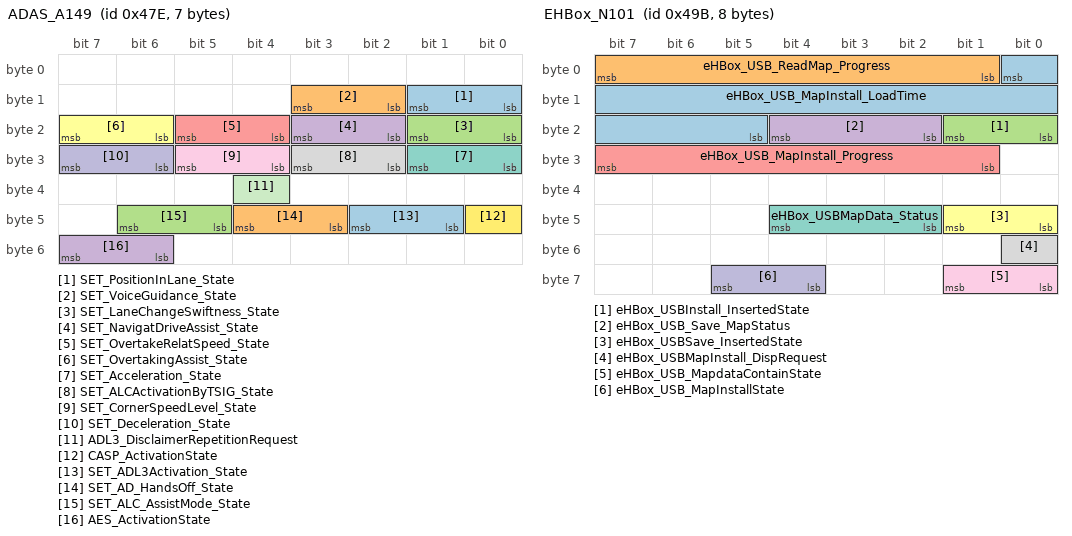
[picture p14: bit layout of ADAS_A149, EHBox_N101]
BO_ 1150 ADAS_A149: 7 CGW
  SG_ SET_PositionInLane_State : 9|2@0+ (1,0) [0|0] "" IVI
  SG_ SET_VoiceGuidance_State : 11|2@0+ (1,0) [0|0] "" IVI
  SG_ SET_LaneChangeSwiftness_State : 17|2@0+ (1,0) [0|0] "" IVI
  SG_ SET_NavigatDriveAssist_State : 19|2@0+ (1,0) [0|0] "" IVI
  SG_ SET_OvertakeRelatSpeed_State : 21|2@0+ (1,0) [0|0] "" IVI
  SG_ SET_OvertakingAssist_State : 23|2@0+ (1,0) [0|0] "" IVI
  SG_ SET_Acceleration_State : 25|2@0+ (1,0) [0|0] "" IVI
  SG_ SET_ALCActivationByTSIG_State : 27|2@0+ (1,0) [0|0] "" IVI
  SG_ SET_CornerSpeedLevel_State : 29|2@0+ (1,0) [0|0] "" IVI
  SG_ SET_Deceleration_State : 31|2@0+ (1,0) [0|0] "" IVI
  SG_ ADL3_DisclaimerRepetitionRequest : 36|1@0+ (1,0) [0|0] "" IVI
  SG_ CASP_ActivationState : 40|1@0+ (1,0) [0|0] "" IVI
  SG_ SET_ADL3Activation_State : 42|2@0+ (1,0) [0|0] "" IVI
  SG_ SET_AD_HandsOff_State : 44|2@0+ (1,0) [0|0] "" IVI
  SG_ SET_ALC_AssistMode_State : 46|2@0+ (1,0) [0|0] "" IVI
  SG_ AES_ActivationState : 55|2@0+ (1,0) [0|0] "" IVI

BO_ 1172 IVI_R17: 2 IVI
  SG_ EcoNavRechargeDuringTrip : 2|3@0+ (1,0) [0|0] "" CGW
  SG_ SC_SmartchargingActivationStatus : 13|2@0+ (1,0) [0|0] "" CGW
  SG_ SC_PresoakActivationStatus : 15|2@0+ (1,0) [0|0] "" CGW

BO_ 1174 FrCamADAS_R111: 8 CGW
  SG_ SafeScore_CIPV_Distance : 15|13@0+ (0.05,-20) [-20|200] "m" IVI
  SG_ SafeScore_CIPV_RelativeSpeed : 18|13@0+ (0.05,-128) [-128|127.95] "m/s" IVI
  SG_ SafeScore_LeftLineCrossDistance : 55|7@0+ (0.05,-1) [-1|4] "m" IVI
  SG_ SafeScore_RightLineCrossDistance : 63|7@0+ (0.05,-1) [-1|4] "m" IVI

BO_ 1179 EHBox_N101: 8 eHBox
  SG_ eHBox_USB_MapInstall_LoadTime : 0|12@0+ (1,0) [0|0] "" CGW
  SG_ eHBox_USB_ReadMap_Progress : 7|7@0+ (1,0) [0|100] "%" CGW
  SG_ eHBox_USBInstall_InsertedState : 17|2@0+ (1,0) [0|0] "" CGW
  SG_ eHBox_USB_Save_MapStatus : 20|3@0+ (1,0) [0|0] "" CGW
  SG_ eHBox_USB_MapInstall_Progress : 31|7@0+ (1,0) [0|100] "%" CGW
  SG_ eHBox_USBSave_InsertedState : 41|2@0+ (1,0) [0|0] "" CGW
  SG_ eHBox_USBMapData_Status : 44|3@0+ (1,0) [0|0] "" CGW
  SG_ eHBox_USBMapInstall_DispRequest : 48|1@0+ (1,0) [0|0] "" CGW
  SG_ eHBox_USB_MapdataContainState : 57|2@0+ (1,0) [0|0] "" CGW
  SG_ eHBox_USB_MapInstallState : 61|2@0+ (1,0) [0|0] "" CGW

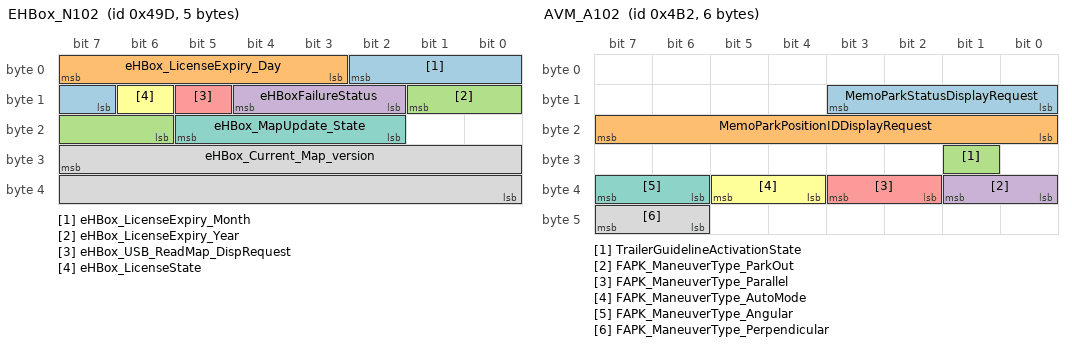
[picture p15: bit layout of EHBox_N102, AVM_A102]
BO_ 1181 EHBox_N102: 5 eHBox
  SG_ eHBox_LicenseExpiry_Month : 2|4@0+ (1,0) [0|12] "Month" CGW
  SG_ eHBox_LicenseExpiry_Day : 7|5@0+ (1,0) [0|31] "Day" CGW
  SG_ eHBox_LicenseExpiry_Year : 9|4@0+ (1,2036) [2036|2050] "Year" CGW
  SG_ eHBoxFailureStatus : 12|3@0+ (1,0) [0|0] "" CGW
  SG_ eHBox_USB_ReadMap_DispRequest : 13|1@0+ (1,0) [0|0] "" CGW
  SG_ eHBox_LicenseState : 14|1@0+ (1,0) [0|0] "" CGW
  SG_ eHBox_MapUpdate_State : 21|4@0+ (1,0) [0|0] "" CGW
  SG_ eHBox_Current_Map_version : 31|16@0+ (1,0) [0|0] "" CGW

BO_ 1182 HEVC_N108: 2 CGW
  SG_ AvailableEnergy_HEVC_v2 : 3|11@0+ (0.1,0) [0|200] "kWh" IVI
  SG_ BatterytoOtherAccessories_flow : 4|1@0+ (1,0) [0|0] "" IVI
  SG_ BatterytoCabin_flow : 5|1@0+ (1,0) [0|0] "" IVI
  SG_ StateofBatteryTemperature_flow : 7|2@0+ (1,0) [0|0] "" IVI

BO_ 1183 VDC_R103: 5 CGW
  SG_ EstimatedVehicleMassValidity : 17|2@0+ (1,0) [0|0] "" IVI
  SG_ EstimatedVehicleMass : 31|9@0+ (25,0) [0|10000] "kg" IVI

BO_ 1189 BCM_N101: 8 CGW
  SG_ UserIdentification_IKeyLink_v2 : 39|4@0+ (1,0) [0|0] "" IVI

BO_ 1196 IVI_R110: 8 IVI
  SG_ FDC_CONFIG : 7|64@0+ (1,0) [0|0] "" CGW

BO_ 1202 AVM_A102: 6 CGW
  SG_ MemoParkStatusDisplayRequest : 11|4@0+ (1,0) [0|0] "" IVI
  SG_ MemoParkPositionIDDisplayRequest : 23|8@0+ (1,0) [0|250] "" IVI
  SG_ TrailerGuidelineActivationState : 25|1@0+ (1,0) [0|0] "" IVI
  SG_ FAPK_ManeuverType_ParkOut : 33|2@0+ (1,0) [0|0] "" IVI
  SG_ FAPK_ManeuverType_Parallel : 35|2@0+ (1,0) [0|0] "" IVI
  SG_ FAPK_ManeuverType_AutoMode : 37|2@0+ (1,0) [0|0] "" IVI
  SG_ FAPK_ManeuverType_Angular : 39|2@0+ (1,0) [0|0] "" IVI
  SG_ FAPK_ManeuverType_Perpendicular : 47|2@0+ (1,0) [0|0] "" IVI

BO_ 1203 FRCAMERA_A110: 5 CGW
  SG_ OSPSpeedLimit : 15|8@0+ (1,5) [5|200] "Kmh/Mph" IVI

BO_ 1204 HVAC_A103: 8 CGW
  SG_ AC_FlapIntakePosition : 46|7@0+ (1,0) [0|100] "%" IVI

BO_ 1210 HEVC_A160: 5 CGW
  SG_ Combo_EVchargeHLCRequest_v2 : 29|5@0+ (1,0) [0|0] "" IVI
  SG_ HVbatHeaterWh : 39|7@0+ (100,0) [0|12600] "Wh" IVI

BO_ 1227 BCM_A124: 2 CGW
  SG_ AmbiLightADLINKTypeStatus : 0|2@0+ (1,0) [0|0] "" IVI
  SG_ AmbiLightADColorStatus : 7|7@0+ (1,0) [0|0] "" IVI
  SG_ ESSU_StateDisplay : 14|4@0+ (1,0) [0|0] "" IVI

BO_ 1232 HEVC_N103: 7 CGW
  SG_ HVbatHeaterWatt_Max : 40|7@0+ (100,0) [0|12600] "W" IVI
  SG_ ManualBatteryWarmingSWRestart : 44|1@0+ (1,0) [0|0] "" IVI
  SG_ HVbatQCPreheatingOffState : 45|1@0+ (1,0) [0|0] "" IVI

BO_ 1233 BCM_A103: 8 CGW
  SG_ FrontWasherPumpActivationReq : 25|1@0+ (1,0) [0|0] "" IVI

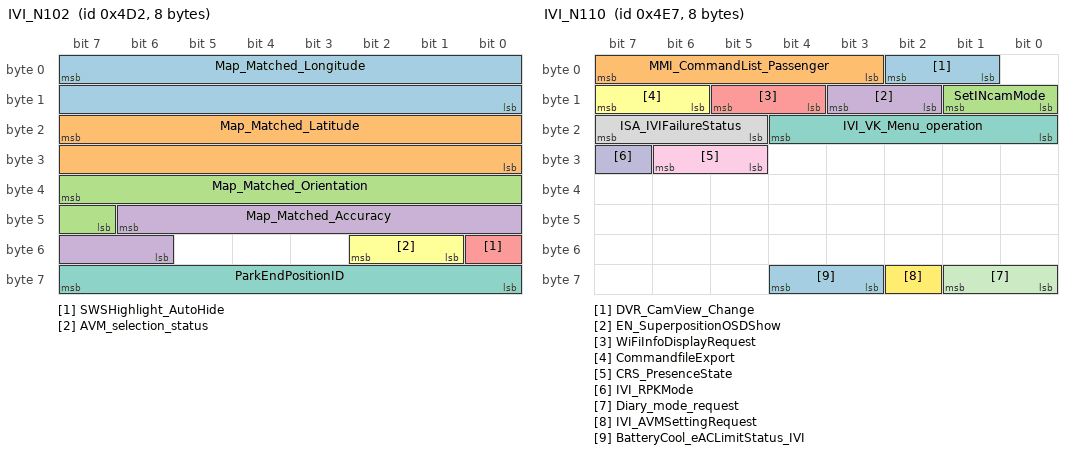
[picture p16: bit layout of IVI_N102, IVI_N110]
BO_ 1234 IVI_N102: 8 IVI
  SG_ Map_Matched_Longitude : 7|16@0+ (0.00010,-0.2) [-0.2|0.2] "min" CGW
  SG_ Map_Matched_Latitude : 23|16@0+ (0.00010,-0.2) [-0.2|0.2] "min" CGW
  SG_ Map_Matched_Orientation : 39|9@0+ (1,-180) [-180|179] "°" CGW
  SG_ Map_Matched_Accuracy : 46|9@0+ (0.1,0) [0|50] "m" CGW
  SG_ SWSHighlight_AutoHide : 48|1@0+ (1,0) [0|0] "" CGW
  SG_ AVM_selection_status : 50|2@0+ (1,0) [0|0] "" CGW
  SG_ ParkEndPositionID : 63|8@0+ (1,0) [0|250] "" CGW

BO_ 1247 DVR_N103: 7 CGW
  SG_ GeneralRecordingStatus_v2 : 1|2@0+ (1,0) [0|0] "" IVI
  SG_ WiFiStatus_v2 : 3|2@0+ (1,0) [0|0] "" IVI
  SG_ UpdateStatus_Command_Response : 5|2@0+ (1,0) [0|0] "" IVI
  SG_ RecordVideoQuality_HSL : 7|2@0+ (1,0) [0|0] "" IVI
  SG_ ComandResp_fileExport : 10|2@0+ (1,0) [0|0] "" IVI
  SG_ DVR_CommandRespList_Passenger : 15|5@0+ (1,0) [0|0] "" IVI
  SG_ INcamWrongModeWarning : 17|2@0+ (1,0) [0|0] "" IVI
  SG_ INcamModeStatus : 20|3@0+ (1,0) [0|0] "" IVI
  SG_ DVR_EthernetStatus : 23|3@0+ (1,0) [0|0] "" IVI
  SG_ SuperpositionOSDShow : 25|2@0+ (1,0) [0|0] "" IVI
  SG_ RRCameraStatus : 28|3@0+ (1,0) [0|0] "" IVI
  SG_ INCameraStatus : 31|3@0+ (1,0) [0|0] "" IVI
  SG_ UsageCounterOfDVRRemote : 34|3@0+ (1,0) [0|0] "" IVI
  SG_ eMMCStatus : 36|2@0+ (1,0) [0|0] "" IVI
  SG_ FRCameraStatus : 39|3@0+ (1,0) [0|0] "" IVI
  SG_ FilesExportingStatus : 40|1@0+ (1,0) [0|0] "" IVI
  SG_ UpgradeProgress : 47|7@0+ (1,0) [0|0] "" IVI
  SG_ Diary_mode_status : 55|2@0+ (1,0) [0|0] "" IVI

BO_ 1251 RSCU3R_A101: 2 CGW
  SG_ Rear3RightSeatFoldUnfoldState : 5|2@0+ (1,0) [0|0] "" IVI
  SG_ Rear3LeftSeatFoldUnfoldState : 7|2@0+ (1,0) [0|0] "" IVI
  SG_ Rear3RightSeatMovingState : 13|2@0+ (1,0) [0|0] "" IVI
  SG_ Rear3LeftSeatMovingState : 15|2@0+ (1,0) [0|0] "" IVI

BO_ 1252 ECM_A14: 8 CGW
  SG_ NominalFuelConsumption : 55|8@0+ (80,0) [0|20400] "mm3" IVI

BO_ 1255 IVI_N110: 8 IVI
  SG_ DVR_CamView_Change : 2|2@0+ (1,0) [0|0] "" CGW
  SG_ MMI_CommandList_Passenger : 7|5@0+ (1,0) [0|0] "" CGW
  SG_ SetINcamMode : 9|2@0+ (1,0) [0|0] "" CGW
  SG_ EN_SuperpositionOSDShow : 11|2@0+ (1,0) [0|0] "" CGW
  SG_ WiFiInfoDisplayRequest : 13|2@0+ (1,0) [0|0] "" CGW
  SG_ CommandfileExport : 15|2@0+ (1,0) [0|0] "" CGW
  SG_ IVI_VK_Menu_operation : 20|5@0+ (1,0) [0|0] "" CGW
  SG_ ISA_IVIFailureStatus : 23|3@0+ (1,0) [0|0] "" CGW
  SG_ CRS_PresenceState : 30|2@0+ (1,0) [0|0] "" CGW
  SG_ IVI_RPKMode : 31|1@0+ (1,0) [0|0] "" CGW
  SG_ Diary_mode_request : 57|2@0+ (1,0) [0|0] "" CGW
  SG_ IVI_AVMSettingRequest : 58|1@0+ (1,0) [0|0] "" CGW
  SG_ BatteryCool_eACLimitStatus_IVI : 60|2@0+ (1,0) [0|0] "" CGW

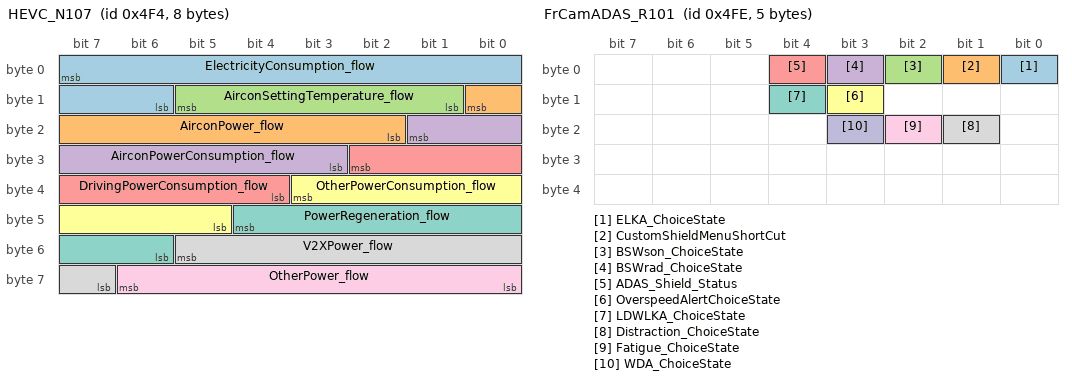
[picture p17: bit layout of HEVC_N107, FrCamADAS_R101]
BO_ 1268 HEVC_N107: 8 CGW
  SG_ ElectricityConsumption_flow : 7|10@0+ (0.1,0) [0|100] "Km/kwh" IVI
  SG_ AirconPower_flow : 8|7@0+ (0.1,0) [0|10] "kW" IVI
  SG_ AirconSettingTemperature_flow : 13|5@0+ (0.5,18) [18|33] "°C" IVI
  SG_ AirconPowerConsumption_flow : 17|7@0+ (1,0) [0|100] "kWh" IVI
  SG_ DrivingPowerConsumption_flow : 26|7@0+ (1,0) [0|100] "kWh" IVI
  SG_ OtherPowerConsumption_flow : 35|7@0+ (1,0) [0|100] "kWh" IVI
  SG_ PowerRegeneration_flow : 44|7@0+ (1,0) [0|100] "kWh" IVI
  SG_ V2XPower_flow : 53|7@0+ (0.1,0) [0|10] "kW" IVI
  SG_ OtherPower_flow : 62|7@0+ (0.1,0) [0|10] "kW" IVI

BO_ 1276 ADAS_A6: 8 CGW
  SG_ BCI_ActivationState : 32|1@0+ (1,0) [0|0] "" IVI
  SG_ ACC_Status_Slow : 45|4@0+ (1,0) [0|0] "" IVI

BO_ 1277 HEVC_R126: 8 CGW
  SG_ CAV_Position_FeedBack_EVA : 10|3@0+ (1,0) [0|0] "" IVI
  SG_ HVBatteryTemperature_MMI : 47|7@0+ (1,0) [0|100] "%" IVI
  SG_ PWTTemperature_MMI : 55|7@0+ (1,0) [0|100] "%" IVI

BO_ 1278 FrCamADAS_R101: 5 CGW
  SG_ ELKA_ChoiceState : 0|1@0+ (1,0) [0|0] "" IVI
  SG_ CustomShieldMenuShortCut : 1|1@0+ (1,0) [0|0] "" IVI
  SG_ BSWson_ChoiceState : 2|1@0+ (1,0) [0|0] "" IVI
  SG_ BSWrad_ChoiceState : 3|1@0+ (1,0) [0|0] "" IVI
  SG_ ADAS_Shield_Status : 4|1@0+ (1,0) [0|0] "" IVI
  SG_ OverspeedAlertChoiceState : 11|1@0+ (1,0) [0|0] "" IVI
  SG_ LDWLKA_ChoiceState : 12|1@0+ (1,0) [0|0] "" IVI
  SG_ Distraction_ChoiceState : 17|1@0+ (1,0) [0|0] "" IVI
  SG_ Fatigue_ChoiceState : 18|1@0+ (1,0) [0|0] "" IVI
  SG_ WDA_ChoiceState : 19|1@0+ (1,0) [0|0] "" IVI

BO_ 1279 IVI_A132: 8 IVI
  SG_ DriverTiltMovingReq : 1|2@0+ (1,0) [0|0] "" CGW
  SG_ DriverLifterMovingReq : 3|2@0+ (1,0) [0|0] "" CGW
  SG_ DriverReclinerMovingReq : 5|2@0+ (1,0) [0|0] "" CGW
  SG_ DriverSlideMovingReq : 7|2@0+ (1,0) [0|0] "" CGW
  SG_ PsSlideMovingReq : 9|2@0+ (1,0) [0|0] "" CGW
  SG_ DriverBacksidebolsterMovingReq : 11|2@0+ (1,0) [0|0] "" CGW
  SG_ DriverLumbarMovingReq_Z_Axis : 13|2@0+ (1,0) [0|0] "" CGW
  SG_ DriverLumbarMovingReq_X_Axis : 15|2@0+ (1,0) [0|0] "" CGW
  SG_ PsLumbarMovingReq_X_Axis : 17|2@0+ (1,0) [0|0] "" CGW
  SG_ PsTiltMovingReq : 19|2@0+ (1,0) [0|0] "" CGW
  SG_ PsLifterMovingReq : 21|2@0+ (1,0) [0|0] "" CGW
  SG_ PsReclinerMovingReq : 23|2@0+ (1,0) [0|0] "" CGW
  SG_ Rear2RightSeatFoldUnfoldReq : 25|2@0+ (1,0) [0|0] "" CGW
  SG_ Rear2LeftSeatFoldUnfoldReq : 27|2@0+ (1,0) [0|0] "" CGW
  SG_ PsBacksidebolsterMovingReq : 29|2@0+ (1,0) [0|0] "" CGW
  SG_ PsLumbarMovingReq_Z_Axis : 31|2@0+ (1,0) [0|0] "" CGW
  SG_ Rear2RightSeatWalkinReq : 33|2@0+ (1,0) [0|0] "" CGW
  SG_ Rear2LeftSeatWalkinReq : 35|2@0+ (1,0) [0|0] "" CGW
  SG_ Rear3RightSeatFoldUnfoldReq : 37|2@0+ (1,0) [0|0] "" CGW
  SG_ Rear3LeftSeatFoldUnfoldReq : 39|2@0+ (1,0) [0|0] "" CGW
  SG_ PoweratQCstation : 42|9@0+ (1,0) [0|500] "KW" CGW
  SG_ ThirdRowLeftSeatAutoRequest : 44|2@0+ (1,0) [0|0] "" CGW
  SG_ ThirdRowRightSeatAutoRequest : 46|2@0+ (1,0) [0|0] "" CGW
  SG_ ClimIRSensorOn_Push : 47|1@0+ (1,0) [0|1] "-" CGW
  SG_ SOCPredictedAtQCStation : 63|7@0+ (1,0) [0|100] "%" CGW

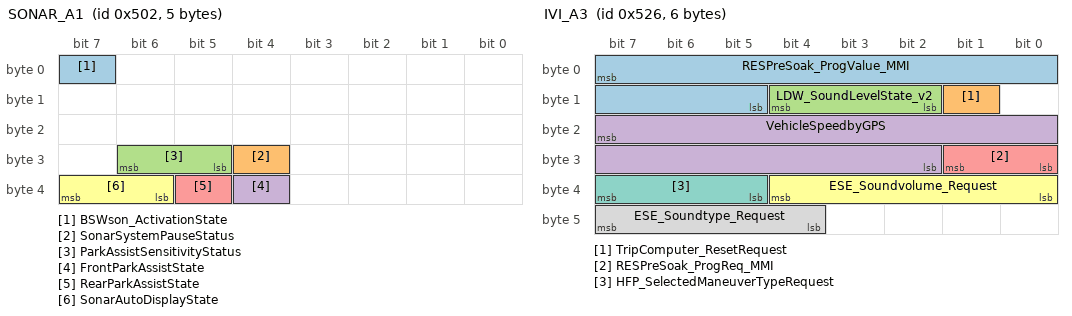
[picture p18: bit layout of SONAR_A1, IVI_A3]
BO_ 1282 SONAR_A1: 5 CGW
  SG_ BSWson_ActivationState : 7|1@0+ (1,0) [0|0] "" IVI
  SG_ SonarSystemPauseStatus : 28|1@0+ (1,0) [0|0] "" IVI
  SG_ ParkAssistSensitivityStatus : 30|2@0+ (1,0) [0|0] "" IVI
  SG_ FrontParkAssistState : 36|1@0+ (1,0) [0|0] "" IVI
  SG_ RearParkAssistState : 37|1@0+ (1,0) [0|0] "" IVI
  SG_ SonarAutoDisplayState : 39|2@0+ (1,0) [0|0] "" IVI

BO_ 1284 HEVC_A168: 1 CGW
  SG_ HVbatQCPreheatingState : 1|2@0+ (1,0) [0|0] "" IVI
  SG_ HVBatChargeIncreaseCancel : 2|1@0+ (1,0) [0|0] "" IVI
  SG_ HVBatCoolingSaveCancel : 3|1@0+ (1,0) [0|0] "" IVI
  SG_ HVBatChargeIncreaseState : 5|2@0+ (1,0) [0|0] "" IVI
  SG_ HVBatCoolingSaveState : 7|2@0+ (1,0) [0|0] "" IVI

BO_ 1292 IVI_R106: 2 IVI
  SG_ MultimediaSWupdateDisplay : 3|3@0+ (1,0) [0|0] "" CGW
  SG_ SportUsageRequest2 : 9|2@0+ (1,0) [0|0] "" CGW
  SG_ ScreenDriverSaveModeRequest : 11|2@0+ (1,0) [0|0] "" CGW
  SG_ SafeScore_AdviceMessage : 15|4@0+ (1,0) [0|0] "" CGW

BO_ 1294 BLM_A102: 1 CGW
  SG_ VirtualKeyMenuState : 7|2@0+ (1,0) [0|0] "" IVI

BO_ 1295 IVI_A124: 8 IVI
  SG_ DriverMassageProgramReq_v2 : 4|4@0+ (1,0) [0|0] "" CGW
  SG_ SET_ALCP2P_AlertLevel_Request2 : 7|3@0+ (1,0) [0|0] "" CGW
  SG_ OtherLampActivateRequest : 11|2@0+ (1,0) [0|0] "" CGW
  SG_ PassengerMassageProgramReq_v2 : 15|4@0+ (1,0) [0|0] "" CGW
  SG_ EmblemLightIntensityRequest : 21|5@0+ (5,0) [0|100] "%" CGW
  SG_ AmbientADLinkRequest : 23|2@0+ (1,0) [0|0] "" CGW
  SG_ HVbatteryCoolingActivationReq2 : 25|2@0+ (1,0) [0|0] "" CGW
  SG_ SET_AD_HandsOff_Request2 : 27|2@0+ (1,0) [0|0] "" CGW
  SG_ SET_ALC_AssistMode_Request2 : 29|2@0+ (1,0) [0|0] "" CGW
  SG_ AmbientLightingArea5Req : 31|2@0+ (1,0) [0|0] "" CGW
  SG_ SET_ADL3Activation_Request2 : 39|2@0+ (1,0) [0|0] "" CGW
  SG_ RearRightMassageActivationReq : 41|2@0+ (1,0) [0|0] "" CGW
  SG_ RearRightAutoReturnReq : 43|2@0+ (1,0) [0|0] "" CGW
  SG_ RearLeftMassageActivationReq : 45|2@0+ (1,0) [0|0] "" CGW
  SG_ RearLeftAutoReturnReq : 47|2@0+ (1,0) [0|0] "" CGW
  SG_ FrWiper_ServPos_Request : 53|2@0+ (1,0) [0|0] "" CGW
  SG_ AES_ActivationRequest2 : 55|2@0+ (1,0) [0|0] "" CGW
  SG_ VR_RrWipingRequest : 58|3@0+ (1,0) [0|0] "" CGW
  SG_ VR_FrWipingRequest : 61|3@0+ (1,0) [0|0] "" CGW
  SG_ RrWiper_ServPos_Request : 63|2@0+ (1,0) [0|0] "" CGW

BO_ 1296 TCU_A103: 8 CGW
  SG_ TCU_DVR_Photo_Request : 1|1@0+ (1,0) [0|0] "" IVI
  SG_ IVI_SafeMode : 3|1@0+ (1,0) [0|0] "" IVI
  SG_ IVI_SafeModePersistentON : 4|1@0+ (1,0) [0|0] "" IVI
  SG_ IVI_SafeModeRebootReason : 7|3@0+ (1,0) [0|0] "" IVI
  SG_ Heavy_crash_activate : 40|1@0+ (1,0) [0|0] "" IVI

BO_ 1298 AVMSD_R101: 2 AVM_SD
  SG_ AVM_ClosingAuthorization_2 : 2|1@0+ (1,0) [0|0] "" IVI
  SG_ AVM_LayoutDisplayRequest_2 : 7|5@0+ (1,0) [0|0] "" IVI
  SG_ AVM_LayoutVideoStatus_2 : 12|5@0+ (1,0) [0|0] "" IVI
  SG_ AVM_WarningDisplayRequest_2 : 15|3@0+ (1,0) [0|0] "" IVI

BO_ 1299 SONAR_A3: 5 CGW
  SG_ FKP_ObstacleZone_RF : 1|2@0+ (1,0) [0|0] "" AVM_SD,IVI
  SG_ FKP_ObstacleZone_LRC : 3|2@0+ (1,0) [0|0] "" AVM_SD,IVI
  SG_ FKP_ObstacleZone_LFC : 5|2@0+ (1,0) [0|0] "" AVM_SD,IVI
  SG_ FKP_ObstacleZone_LF : 7|2@0+ (1,0) [0|0] "" AVM_SD,IVI
  SG_ FKP_ObstacleZone_RRC : 9|2@0+ (1,0) [0|0] "" AVM_SD,IVI
  SG_ FKP_ObstacleZone_RR : 11|2@0+ (1,0) [0|0] "" AVM_SD,IVI
  SG_ FKP_ObstacleZone_RL : 13|2@0+ (1,0) [0|0] "" AVM_SD,IVI
  SG_ FKP_ObstacleZone_RFC : 15|2@0+ (1,0) [0|0] "" AVM_SD,IVI
  SG_ FKP_FrontMiddleL_Scan : 16|1@0+ (1,0) [0|0] "" IVI
  SG_ FKP_FrontMiddleR_Hatch : 17|1@0+ (1,0) [0|0] "" IVI
  SG_ FKP_FrontMiddleL_Hatch : 18|1@0+ (1,0) [0|0] "" IVI
  SG_ FKP_FrontFrontR_Scan : 19|1@0+ (1,0) [0|0] "" IVI
  SG_ FKP_FrontFrontR_Hatch : 20|1@0+ (1,0) [0|0] "" IVI
  SG_ FKP_FrontFrontL_Scan : 21|1@0+ (1,0) [0|0] "" IVI
  SG_ FKP_ImageDisplayRequest : 22|1@0+ (1,0) [0|0] "" AVM_SD,IVI
  SG_ FKP_FrontMiddleR_Scan : 23|1@0+ (1,0) [0|0] "" IVI
  SG_ FKP_RearRearR_Scan : 24|1@0+ (1,0) [0|0] "" IVI
  SG_ FKP_RearRearR_Hatch : 25|1@0+ (1,0) [0|0] "" IVI
  SG_ FKP_RearRearL_Scan : 26|1@0+ (1,0) [0|0] "" IVI
  SG_ FKP_RearRearL_Hatch : 27|1@0+ (1,0) [0|0] "" IVI
  SG_ FKP_RearMiddleR_Scan : 28|1@0+ (1,0) [0|0] "" IVI
  SG_ FKP_RearMiddleR_Hatch : 29|1@0+ (1,0) [0|0] "" IVI
  SG_ FKP_RearMiddleL_Scan : 30|1@0+ (1,0) [0|0] "" IVI
  SG_ FKP_RearMiddleL_Hatch : 31|1@0+ (1,0) [0|0] "" IVI
  SG_ FKP_FrontFrontL_Hatch : 32|1@0+ (1,0) [0|0] "" IVI
  SG_ UPA_RearRight_Hatch : 33|1@0+ (1,0) [0|0] "" IVI
  SG_ UPA_RearMiddle_Hatch : 34|1@0+ (1,0) [0|0] "" IVI
  SG_ UPA_RearLeft_Hatch : 35|1@0+ (1,0) [0|0] "" IVI
  SG_ UPA_FrontRight_Hatch : 36|1@0+ (1,0) [0|0] "" IVI
  SG_ UPA_FrontMiddle_Hatch : 37|1@0+ (1,0) [0|0] "" IVI
  SG_ UPA_FrontLeft_Hatch : 38|1@0+ (1,0) [0|0] "" IVI
  SG_ FKP_ActivationStatus : 39|1@0+ (1,0) [0|0] "" IVI

BO_ 1303 FRCAMERA_A2: 8 CGW
  SG_ OverSpeedWarningSound : 0|1@0+ (1,0) [0|0] "" IVI
  SG_ RainSymbolDisplayRequest : 14|1@0+ (1,0) [0|0] "" IVI
  SG_ TSR_OSP_SpeedSignalZone1 : 23|8@0+ (1,0) [0|200] "wu" IVI
  SG_ TSR_OSP_ActivationStatus : 42|2@0+ (1,0) [0|0] "" IVI
  SG_ OSPOverSpeedDisplayRequest : 47|1@0+ (1,0) [0|0] "" IVI

BO_ 1310 MM_NAV_CARTO_R1: 8 IVI
  SG_ CartoData : 4|61@0+ (1,0) [0|0] "" CGW
  SG_ OSPDataType : 7|3@0+ (1,0) [0|0] "" CGW

BO_ 1313 SRFR2_R101: 2 CGW
  SG_ MOIS_ActivationState : 0|1@0+ (1,0) [0|0] "" IVI
  SG_ MOIS_MuteActivationState : 15|1@0+ (1,0) [0|0] "" IVI

BO_ 1315 BCM_A8: 3 CGW
  SG_ AbsoluteTimeSince1rstIgnition : 7|24@0+ (1,0) [0|1.677E7] "min" IVI

BO_ 1318 IVI_A3: 6 IVI
  SG_ RESPreSoak_ProgValue_MMI : 7|11@0+ (1,0) [0|1440] "min" CGW
  SG_ TripComputer_ResetRequest : 9|1@0+ (1,0) [0|0] "" CGW
  SG_ LDW_SoundLevelState_v2 : 12|3@0+ (1,0) [0|0] "" CGW
  SG_ VehicleSpeedbyGPS : 23|14@0+ (0.03,0) [0|255] "km/h" CGW
  SG_ RESPreSoak_ProgReq_MMI : 25|2@0+ (1,0) [0|0] "" CGW
  SG_ ESE_Soundvolume_Request : 36|5@0+ (1,0) [0|0] "" CGW
  SG_ HFP_SelectedManeuverTypeRequest : 39|3@0+ (1,0) [0|0] "" CGW
  SG_ ESE_Soundtype_Request : 47|4@0+ (1,0) [0|0] "" CGW

BO_ 1319 ADAS_N101: 7 CGW
  SG_ ADL2_CurveWarningState : 23|8@0+ (1,0) [0|255] "wu" IVI
  SG_ ADL2L3_P2PFeatureState : 31|8@0+ (1,0) [0|255] "wu" IVI
  SG_ ADTutorial_GuideDisplay : 37|2@0+ (1,0) [0|0] "" IVI

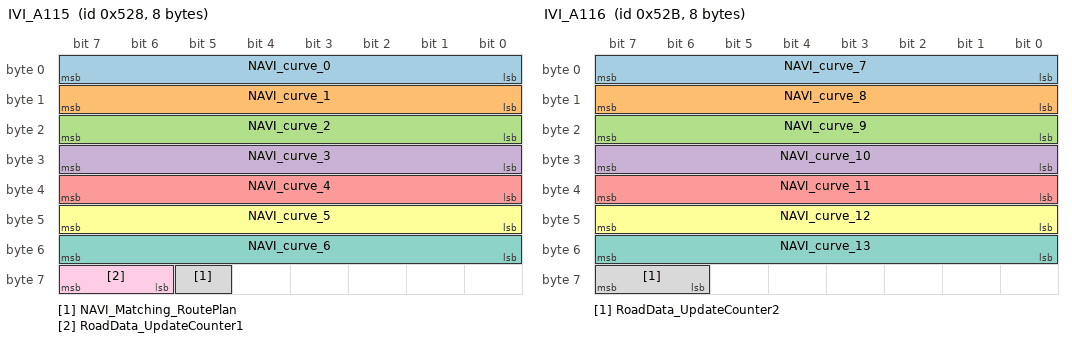
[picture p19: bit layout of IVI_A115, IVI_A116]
BO_ 1320 IVI_A115: 8 IVI
  SG_ NAVI_curve_0 : 7|8@0+ (1,0) [0|255] "" CGW
  SG_ NAVI_curve_1 : 15|8@0+ (1,0) [0|255] "" CGW
  SG_ NAVI_curve_2 : 23|8@0+ (1,0) [0|255] "" CGW
  SG_ NAVI_curve_3 : 31|8@0+ (1,0) [0|255] "" CGW
  SG_ NAVI_curve_4 : 39|8@0+ (1,0) [0|255] "" CGW
  SG_ NAVI_curve_5 : 47|8@0+ (1,0) [0|255] "" CGW
  SG_ NAVI_curve_6 : 55|8@0+ (1,0) [0|255] "" CGW
  SG_ NAVI_Matching_RoutePlan : 61|1@0+ (1,0) [0|0] "" CGW
  SG_ RoadData_UpdateCounter1 : 63|2@0+ (1,0) [0|3] "" CGW

BO_ 1321 IVI_N19: 8 IVI
  SG_ SetParkingMonitor : 1|2@0+ (1,0) [0|0] "" CGW
  SG_ SetRecordQuality : 3|2@0+ (1,0) [0|0] "" CGW
  SG_ MuteRecordSet : 5|2@0+ (1,0) [0|0] "" CGW
  SG_ RecordTimeSet : 7|2@0+ (1,0) [0|0] "" CGW
  SG_ SetCollideSensitivity : 13|2@0+ (1,0) [0|0] "" CGW
  SG_ SetCollideCheck : 15|2@0+ (1,0) [0|0] "" CGW
  SG_ FilePlayNum : 19|4@0+ (1,0) [0|0] "" CGW
  SG_ EN_SuperpositionOthersShow : 21|2@0+ (1,0) [0|0] "" CGW
  SG_ EN_SuperpositionSpeedShow : 23|2@0+ (1,0) [0|0] "" CGW
  SG_ GPSClockStatus : 24|1@0+ (1,0) [0|0] "" CGW
  SG_ GatherPhoto : 26|2@0+ (1,0) [0|0] "" CGW
  SG_ MMI_CommandList : 31|5@0+ (1,0) [0|0] "" CGW
  SG_ DataLength : 39|5@0+ (1,0) [0|17] "" CGW
  SG_ DataIndex : 45|4@0+ (1,0) [0|9] "" CGW
  SG_ TransportContent : 47|2@0+ (1,0) [0|0] "" CGW
  SG_ ConnectionData1 : 55|8@0+ (1,0) [0|254] "" CGW
  SG_ ConnectionData2 : 63|8@0+ (1,0) [0|254] "" CGW

BO_ 1323 IVI_A116: 8 IVI
  SG_ NAVI_curve_7 : 7|8@0+ (1,0) [0|255] "" CGW
  SG_ NAVI_curve_8 : 15|8@0+ (1,0) [0|255] "" CGW
  SG_ NAVI_curve_9 : 23|8@0+ (1,0) [0|255] "" CGW
  SG_ NAVI_curve_10 : 31|8@0+ (1,0) [0|255] "" CGW
  SG_ NAVI_curve_11 : 39|8@0+ (1,0) [0|255] "" CGW
  SG_ NAVI_curve_12 : 47|8@0+ (1,0) [0|255] "" CGW
  SG_ NAVI_curve_13 : 55|8@0+ (1,0) [0|255] "" CGW
  SG_ RoadData_UpdateCounter2 : 63|2@0+ (1,0) [0|3] "" CGW

BO_ 1324 IVI_A117: 8 IVI
  SG_ NAVI_curve_14 : 7|8@0+ (1,0) [0|255] "" CGW
  SG_ NAVI_curve_15 : 15|8@0+ (1,0) [0|255] "" CGW
  SG_ NAVI_curve_16 : 23|8@0+ (1,0) [0|255] "" CGW
  SG_ NAVI_curve_17 : 31|8@0+ (1,0) [0|255] "" CGW
  SG_ NAVI_curve_18 : 39|8@0+ (1,0) [0|255] "" CGW
  SG_ NAVI_curve_19 : 47|8@0+ (1,0) [0|255] "" CGW
  SG_ NAVI_curve_20 : 55|8@0+ (1,0) [0|255] "" CGW
  SG_ RoadData_UpdateCounter3 : 63|2@0+ (1,0) [0|3] "" CGW

BO_ 1325 IVI_A118: 8 IVI
  SG_ NAVI_DistanceToBranch : 7|8@0+ (10,-500) [-500|1000] "m" CGW
  SG_ NAVI_BranchMultipleInfo : 8|1@0+ (1,0) [0|0] "" CGW
  SG_ NAVI_BranchDirection : 10|2@0+ (1,0) [0|0] "" CGW
  SG_ NAVI_CurveDirection : 15|5@0+ (1,0) [0|19] "-" CGW
  SG_ NaviGPS_PositioningStatus : 16|1@0+ (1,0) [0|0] "" CGW
  SG_ NAVI_Matching_Status : 17|1@0+ (1,0) [0|0] "" CGW
  SG_ NAVI_MatchingReset : 18|1@0+ (1,0) [0|0] "" CGW
  SG_ NAVI_DistanceToLinkFailure : 23|5@0+ (25,0) [0|500] "m" CGW
  SG_ NAVI_LinkFailure : 24|1@0+ (1,0) [0|0] "" CGW
  SG_ NAVI_TurningStatus : 25|1@0+ (1,0) [0|0] "" CGW
  SG_ NAVI_CurvatureError : 26|1@0+ (1,0) [0|0] "" CGW
  SG_ NAVI_LinkFailurePoint : 31|5@0+ (1,0) [0|30] "-" CGW
  SG_ NAVI_PrivacyModeStatus : 33|2@0+ (1,0) [0|0] "" CGW
  SG_ NAVI_DistanceToIntersection : 39|6@0+ (10,0) [0|630] "m" CGW
  SG_ InGuidingRoute : 40|1@0+ (1,0) [0|0] "" CGW
  SG_ Current_Roadtype : 43|3@0+ (1,0) [0|0] "" CGW
  SG_ NAVI_DirectionDifference : 47|4@0+ (2.5,0) [0|35] "deg" CGW
  SG_ RoadData_UpdateCounter4 : 49|2@0+ (1,0) [0|3] "" CGW
  SG_ DistanceToTollgate : 55|6@0+ (10,0) [0|630] "m" CGW
  SG_ RouteGuiding_flag : 60|1@0+ (1,0) [0|0] "" CGW
  SG_ Current_Linktype : 63|3@0+ (1,0) [0|0] "" CGW

BO_ 1326 ACU_A103: 1 CGW
  SG_ SecondRowCtrRightSafetyBeltState : 4|2@0+ (1,0) [0|0] "" IVI

BO_ 1328 HEVC_A167: 8 CGW
  SG_ VehicleWeight_EnergyPred : 55|8@0+ (20,0) [0|5000] "kg" IVI

VAL_ 32 AirbagCrashOrder_v3 0 "Crash not detected" 15 "Medium crash" 31 "Violent crash" 47 "Rear crash";
VAL_ 116 StopAutoPhase 0 "NotInAutoPhase" 1 "StartAuto" 2 "StopAuto" 3 "Not Used" 4 "StopAutoOngoing" 5 "StartByInjectionOnly" 6 "ReflexStart" 7 "Unavailable";
VAL_ 117 PowerTrainStatus 0 "Powertrain Stopped" 1 "Reserved" 2 "Powertrain Running" 3 "Powertrain Starting";
VAL_ 168 SwaSensorInternalStatus 0 "not calibrated, not indexed" 1 "not calibrated, indexed" 2 "fault" 3 "reserved" 4 "calibrated, not initialised" 5 "calibrated, initialised" 6 "reserved" 7 "reserved";
VAL_ 255 BrakePedalPressedByDriver 0 "Not used" 1 "Brake Pedal Not Pressed" 2 "Brake Pedal Pressed" 3 "Unavailable";
VAL_ 303 GearLeverPosition_v2 0 "Parking - P" 1 "Reverse - R" 2 "Neutral - N" 3 "Drive - D" 4 "Manual mode - M" 5 "L" 6 "Ds" 7 "Confirmed lever position (no switch signal)" 8 "B (Brake)" 9 "Not used" 10 "Not used" 11 "Not used" 12 "Not used" 13 "Not used" 14 "Not used" 15 "Not available (init or lever switched failure)";
VAL_ 380 SwaSensorInternalStatus_EPS 0 "not calibrated, not indexed" 1 "not calibrated, indexed" 2 "fault" 3 "reserved" 4 "calibrated, not initialised" 5 "calibrated, initialised" 6 "reserved" 7 "reserved";
VAL_ 514 ABSinRegulation 0 "no ABS regulation" 1 "ABS in regulation";
VAL_ 514 WheelTopFL 96 "Max Nissan Value for 96 pulses" 108 "Max Nissan Value for 108 pulses";
VAL_ 514 ASRinRegulation 0 "no ASR regulation" 1 "ASR in regulation";
VAL_ 514 WheelTopFR 96 "Max Nissan Value for 96 pulses" 108 "Max Nissan Value for 108 pulses";
VAL_ 514 MSRinRegulation 0 "no MSR regulation" 1 "MSR in regulation";
VAL_ 514 WheelTopRL 96 "Max Nissan Value for 96 pulses" 108 "Max Nissan Value for 108 pulses";
VAL_ 514 WheelTopRR 96 "Max Nissan Value for 96 pulses" 108 "Max Nissan Value for 108 pulses";
VAL_ 514 WheelDirectionRR 0 "No movement detected yet" 1 "Wheel Front Direction" 2 "Wheel Rear Direction" 3 "Unavailable";
VAL_ 514 WheelDirectionRL 0 "No movement detected yet" 1 "Wheel Front Direction" 2 "Wheel Rear Direction" 3 "Unavailable";
VAL_ 514 AYCMalfunction 0 "no AYC malfunction" 1 "AYC malfunction";
VAL_ 514 AYCinRegulation 0 "no AYC regulation" 1 "AYC in regulation";
VAL_ 514 ASRMalfunction 0 "No ASR malfunction" 1 "ASR malfunction";
VAL_ 514 ABSMalfunction 0 "no ABS malfunction" 1 "ABS malfunction";
VAL_ 514 WheelDirectionFR 0 "No movement detected yet" 1 "Wheel Front Direction" 2 "Wheel Rear Direction" 3 "Unavailable";
VAL_ 514 WheelDirectionFL 0 "No movement detected yet" 1 "Wheel Front Direction" 2 "Wheel Rear Direction" 3 "Unavailable";
VAL_ 534 EPSWarning 0 "No EPS warning" 1 "EPS failure level 1" 2 "EPS failure level 2" 3 "EPS meter lamp check";
VAL_ 545 ETS_InternalOperationMode 0 "automatic selection mode" 1 "fixed 4WD mode" 2 "fixed 2WD mode" 3 "4 Lo Mode";
VAL_ 549 StopLampFlashingRequest 0 "Stop lamps flashing no requested" 1 "Stop lamps flashing requested";
VAL_ 559 ContextV2X_ActivationState 0 "Unavailable" 1 "AutoMode ON" 2 "AutoMode OFF" 3 "Not used";
VAL_ 559 ESA_ActivationState 0 "Activated" 1 "Deactivated";
VAL_ 559 CamFS_RainLevel_v2 0 "0" 1 "25 or 50" 2 "75" 3 "99";
VAL_ 578 V2X_EventDetection 0 "no detection (default value)" 1 "detection DEOQ avec IQ=0" 2 "not used" 3 "detection DEOQ avec IQ=2" 4 "detection TJ avec IQ=0" 5 "detection DEOQ avec IQ=0 et TJ avec IQ=0" 6 "not used" 7 "detection DEOQ avec IQ=2 et TJ avec IQ=0" 8 "not used" 9 "not used" 10 "not used" 11 "not used" 12 "detection TJ avec IQ=1" 13 "detection DEOQ avec IQ=0 et TJ avec IQ=1" 14 "not used" 15 "detection DEOQ avec IQ=2 et TJ avec IQ=1" 16 "not used" 17 "not used" 18 "not used" 19 "not used" 20 "detection TJ avec IQ=3" 21 "detection DEOQ avec IQ=0 et TJ avec IQ=3" 22 "not used" 23 "detection DEOQ avec IQ=2 et TJ avec IQ=3" 24 "not used" 25 "not used" 26 "not used" 27 "not used" 28 "not used" 29 "not used" 30 "not used" 31 "unavailable";
VAL_ 606 ADASISv2_ShortRang 0 "Table Value30479";
VAL_ 698 ADASISv2_EHorizon 0 "Table Value159557";
VAL_ 747 DiffLock_IndicatorSignal 0 "No Display" 1 "Lock ON" 2 "Transition" 3 "Failure";
VAL_ 791 ISS_EcoActivationState 0 "Unavailable" 1 "ECO activated" 2 "ECO deactivated" 3 "Not used";
VAL_ 791 AirCondEcoActivationState 0 "Unavailable" 1 "ECO activated" 2 "ECO deactivated" 3 "Not used";
VAL_ 791 ClimECOModeStatusDisplay 0 "No display" 1 "Activated" 2 "Not Activated" 3 "Unavailable";
VAL_ 823 IoniserAutoLaunchState 0 "Unavailable" 1 "Auto launch activated" 2 "Auto launch not activated" 3 "Not used";
VAL_ 823 AQMAirFreshenerDisplayRequest 0 "No display (Air Freshener OFF)" 1 "Air Freshener ON display" 2 "Air Freshener refused display" 3 "Air Freshener delayed display";
VAL_ 823 ClimForcedRecyDisplay 0 "No display" 1 "Recycling On" 2 "Recycling OFF" 3 "Not Used";
VAL_ 823 AQMIoniserModeState 0 "Unavailable" 1 "Off" 2 "Clean" 3 "Relax" 4 "Refused" 5 "Not used" 6 "Not used" 7 "Not used";
VAL_ 823 ClimAutoRecyclingDisplay 0 "Unavailable value" 1 "Automatic Recycling not in progress" 2 "Automatic Recycling in progress" 3 "Not Used";
VAL_ 874 ADASISv2_LongRang_AD2 0 "Table Value346937";
VAL_ 877 ADASISv2_SEGMENT_AD2 0 "Table Value346938";
VAL_ 880 ADASISv2_STUB_AD2 0 "Table Value346939";
VAL_ 893 LDW_VibrationIntensityState 0 "Unavailable" 1 "Low Intensity" 2 "Middle Intensity" 3 "High Intensity";
VAL_ 893 LCA_SteeringStatus2 0 "Not Ready" 1 "Ready" 2 "Temporary error" 3 "Error";
VAL_ 928 ADASISv2_LongRang 0 "Table Value30443";
VAL_ 929 ADASISv2_SEGMENT 0 "Table Value30478";
VAL_ 931 ADASISv2_STUB 0 "Table Value30480";
VAL_ 934 APA_StatusDisplay2 0 "Automatic maneuver OFF" 1 "Automatic maneuver Standby" 2 "Automatic maneuver ON" 3 "Not Used";
VAL_ 938 SysSelectAmbiLightColorReq 0 "No Request" 1 "Color 1" 2 "Color 2" 3 "Color 3" 4 "Color 4" 5 "Color 5" 6 "Color 6" 7 "Color 7" 8 "Color 8" 9 "Color 9" 10 "Color 10" 11 "Color 11" 12 "Color 12" 13 "Color 13" 14 "Color 14" 15 "Color 15" 16 "Color 16" 17 "Color 17" 18 "Color 18" 19 "Color 19" 20 "Color 20" 21 "Color 21" 22 "Color 22" 23 "Color 23" 24 "Color 24" 25 "Color 25" 26 "Color 26" 27 "Color 27" 28 "Color 28" 29 "Color 29" 30 "Color 30" 31 "Color 31" 32 "Color 32" 33 "Color 33" 34 "Color 34" 35 "Color 35" 36 "Color 36" 37 "Color 37" 38 "Color 38" 39 "Color 39" 40 "Color 40" 41 "Color 41" 42 "Color 42" 43 "Color 43" 44 "Color 44" 45 "Color 45" 46 "Color 46" 47 "Color 47" 48 "Color 48" 49 "Color 49" 50 "Color 50" 51 "Color 51" 52 "Color 52" 53 "Color 53" 54 "Color 54" 55 "Color 55" 56 "Color 56" 57 "Color 57" 58 "Color 58" 59 "Color 59" 60 "Color 60" 61 "Color 61" 62 "Color 62" 63 "Color 63" 64 "Color 64" 65 "Color 65" 66 "Color 66" 67 "Color 67" 68 "Color 68" 69 "Color 69" 70 "Color 70" 71 "Color 71" 72 "Color 72" 73 "Color 73" 74 "Color 74" 75 "Color 75" 76 "Color 76" 77 "Color 77" 78 "Color 78" 79 "Color 79" 80 "Color 80" 81 "Color 81" 82 "Color 82" 83 "Color 83" 84 "Color 84" 85 "Color 85" 86 "Color 86" 87 "Color 87" 88 "Color 88" 89 "Color 89" 90 "Color 90" 91 "Color 91" 92 "Color 92" 93 "Color 93" 94 "Color 94" 95 "Color 95" 96 "Color 96" 97 "Color 97" 98 "Color 98" 99 "Color 99" 100 "Color 100" 101 "Color 101" 102 "Color 102" 103 "Color 103" 104 "Color 104" 105 "Color 105" 106 "Color 106" 107 "Color 107" 108 "Color 108" 109 "Color 109" 110 "Color 110" 111 "Color 111" 112 "Color 112" 113 "Color 113" 114 "Color 114" 115 "Color 115" 116 "Color 116" 117 "Color 117" 118 "Color 118" 119 "Color 119" 120 "Color 120" 121 "Color 121" 122 "Color 122" 123 "Color 123" 124 "Color 124" 125 "Color 125" 126 "Color 126" 127 "Not used";
VAL_ 944 HeavyRain_Status 0 "no heavy rain" 1 "heavy rain";
VAL_ 955 RST_Boost_Activation_MMI 0 "No Display" 1 "Boost Deactivated" 2 "Boost Activated" 3 "Boost Unavailable";
VAL_ 955 ERP_AutonomyMessageDisplay 0 "Message updated autonomy  is NOT Displayed: 0b0" 1 "Message updated autonomy is Displayed: 0b1";
VAL_ 956 AAM_DigitalInputMonitoring4 0 "Not used" 1 "ON" 2 "OFF" 3 "Unavailable";
VAL_ 956 AAM_DigitalInputMonitoring3 0 "Not used" 1 "ON" 2 "OFF" 3 "Unavailable";
VAL_ 956 AAM_DigitalInputMonitoring2 0 "Not used" 1 "ON" 2 "OFF" 3 "Unavailable";
VAL_ 956 AAM_DigitalInputMonitoring1 0 "Not used" 1 "ON" 2 "OFF" 3 "Unavailable";
VAL_ 956 AAM_DigitalInputMonitoring5 0 "Not used" 1 "ON" 2 "OFF" 3 "Unavailable";
VAL_ 957 StateofBatterycooler_flow 0 "Off" 1 "On";
VAL_ 957 StateofBatteryHeater_flow 0 "Off" 1 "On";
VAL_ 957 StateofSteeringHeater_flow 0 "Off" 1 "On";
VAL_ 957 StateofSeatHeater_flow 0 "Off" 1 "On";
VAL_ 961 DistanceBeforeNextAction 0 "Table Value26873";
VAL_ 961 NAVI_HOVLanesOnRoadFlag 0 "Not on the HOV lane" 1 "Current on the HOV lane";
VAL_ 961 NAVI_UseHOVLanes 0 "OFF" 1 "ON";
VAL_ 961 TrailerLightCheck_Request2 0 "No request" 1 "Trailler Light Check OFF request" 2 "Trailler Light Check ON request" 3 "Reset request";
VAL_ 961 UnitDistanceBeforeNextAction 0 "meter" 1 "kilometer" 2 "yard" 3 "mile" 4 "feet" 5 "not used" 6 "not used" 7 "not used" 8 "not used" 9 "not used" 10 "not used" 11 "not used" 12 "not used" 13 "not used" 14 "not used" 15 "not used";
VAL_ 961 LivingLightReq 0 "No Request" 1 "AmbientLighting Living requested" 2 "AmbientLighting Living not requested" 3 "Reset Request";
VAL_ 961 PhoneIncomingStatus 0 "Not Phone incoming call" 1 "Phone incoming call";
VAL_ 961 RR_FOG_RequestbyVoice 0 "No request" 1 "Deactivated" 2 "Activated" 3 "Not used";
VAL_ 961 NAVI_BootStatus 0 "Not boot" 1 "boot";
VAL_ 961 NAVI_OperationError 0 "No Error" 1 "Error";
VAL_ 962 APA_StatusDisplay 0 "Automatic maneuver OFF" 1 "Automatic maneuver Standby" 2 "Automatic maneuver ON" 3 "Not Used";
VAL_ 967 CDisplayAvailability 0 "Unavailable" 1 "Display Available" 2 "Display Not Available" 3 "Not Used";
VAL_ 967 AutoACC2_ON_Request_MM 0 "No request" 1 "Preparation_Request" 2 "Multimedia_ON_Request" 3 "Not used";
VAL_ 967 Audio_WorkingAuthorize 0 "Not authorized" 1 "reserved" 2 "reserved" 3 "Authorized ";
VAL_ 967 IVI_RefusetoSleep 0 "reserved" 1 "IVI refuse to sleep" 2 "IVI ready to sleep" 3 "reserved";
VAL_ 967 SonarSystemPauseRequest2 0 "No request" 1 "System Pause requested";
VAL_ 967 IVI_InitializationState 0 "Initialization completed" 1 "Initialization in progress";
VAL_ 967 UserFeedbackAvailability 0 "user feedback available" 1 "user feedback unavailable";
VAL_ 967 AudioAvailability 0 "audio available" 1 "audio unavailable";
VAL_ 967 SwitchRequest_AVM 0 "Switch released" 1 "Switch pushed";
VAL_ 967 ChangeViewRequest_AVM 0 "No request" 1 "Bird view" 2 "Side view" 3 "Off";
VAL_ 967 PassengerHeatingRequest 0 "No Request" 1 "Heating 1 request" 2 "Heating 2 request" 3 "Off request";
VAL_ 967 TPMS_ResetDriverRequest2 0 "Unvailable Value" 1 "TPMS Reset driver NOT requested " 2 "TPMS Reset driver requested " 3 "Not Used";
VAL_ 967 TPW_ResetDriverRequest2 0 "Unavailable" 1 "TPW Reset driver NOT requested" 2 "TPW Reset driver requested" 3 "Not used";
VAL_ 967 EcoPedalForceSettingRequest 0 "No request" 1 "ECO Pedal Force setting OFF SW ON" 2 "ECO Pedal Force setting status Soft SW ON" 3 "ECO Pedal Force setting status Standard SW ON";
VAL_ 967 HUD_UpDownRequest2 0 "No request" 1 "Up command requested" 2 "Down command requested" 3 "Reset request";
VAL_ 967 IVI_ParkAssistVolumeState 0 "Level 0 (off)" 1 "Level 1" 2 "Level 2" 3 "Level 3" 4 "Level 4" 5 "Level 5" 6 "Not used" 7 "Not used";
VAL_ 970 VirtualKeyState 0 "VK Suspended" 1 "VK Resumed";
VAL_ 972 AD_TransitionState 0 "No display" 1 "AD1 to AD2L2 HandsON" 2 "AD2L2 HandsON to AD1" 3 "AD2L2 HandsON to AD2L2 HandsOFF" 4 "AD2L2 HandsON to AD1L3" 5 "AD2L2 HandsOFF to AD2L2 HandsON" 6 "AD2L2 HandsOFF to AD1" 7 "AD2L2 HandsOFF to AD1L3" 8 "AD1L3 to AD2L2 HandsOFF" 9 "AD1L3 to AD2L2 HandsON" 10 "AD1L3 to AD1" 11 "Not used" 12 "Not used" 13 "Not used" 14 "Not used" 15 "Not used";
VAL_ 972 AD2L2_HOFF_TransitonState 0 "No display" 1 "User activation : OFF to AD2L2_HOFF ON NotOperational" 2 "System activation : ON NotOperational to Operational" 3 "User deactivation : ON NotOperational to OFF" 4 "User deactivation : ON Operational to OFF" 5 "System deactivation lvl1 ON NotOperational to OFF" 6 "System deactivation lvl2 ON NotOperational to OFF" 7 "System deactivation lvl1 ON Operational to ON NotOperational" 8 "System deactivation lvl2 ON Operational to ON NotOperational" 9 "System deactivation lvl1 ON Operational to OFF" 10 "System deactivation lvl2 ON Operational to OFF" 11 "Not used" 12 "Not used" 13 "Not used" 14 "Not used" 15 "Not used" 16 "Not used" 17 "Not used" 18 "Not used" 19 "Not used" 20 "Not used" 21 "Not used" 22 "Not used" 23 "Not used" 24 "Not used" 25 "Not used" 26 "Not used" 27 "Not used" 28 "Not used" 29 "Not used" 30 "Not used" 31 "Not used";
VAL_ 972 AD2L2_HON_TransitonState 0 "No display" 1 "User activation OFF to AD2L2_HON ON NotOperational" 2 "System activation : ON NotOperational to ON Operational" 3 "User deactivation : NotOperational to OFF" 4 "User deactivation : ON Operational to OFF" 5 "System deactivation lvl1: ON NotOperational to OFF" 6 "System deactivation lvl2 : ON NotOperational to OFF" 7 "System deactivation lvl1 : ON Operational to ON NotOperational" 8 "System deactivation lvl2 ON Operational to ON NotOperational" 9 "System deactivation lvl1 ON Operational to OFF" 10 "System deactivation lvl2 ON Operational to OFF" 11 "Not used" 12 "Not used" 13 "Not used" 14 "Not used" 15 "Not used" 16 "Not used" 17 "Not used" 18 "Not used" 19 "Not used" 20 "Not used" 21 "Not used" 22 "Not used" 23 "Not used" 24 "Not used" 25 "Not used" 26 "Not used" 27 "Not used" 28 "Not used" 29 "Not used" 30 "Not used" 31 "Not used";
VAL_ 972 ADL3_MRM 0 "No display" 1 "Alert Eyes on road level1" 2 "Alert Eyes on road level2" 3 "Alert Eyes on road level3" 4 "Alert Eyes on road level4" 5 "Alert Eyes on road level5" 6 "Alert Eyes on road level6" 7 "Alert Eyes on road level7" 8 "Alert Eyes on road level8" 9 "Alert Eyes on road level9" 10 "Alert Eyes on road level10" 11 "Alert Eyes on road level11" 12 "Alert Eyes on road level12" 13 "Alert Eyes on road level13" 14 "Alert Eyes on road level14" 15 "Alert Eyes on road level15" 16 "Alert Eyes not on road level1" 17 "Alert Eyes not on road level2" 18 "Alert Eyes not on road level3" 19 "Alert Eyes not on road level4" 20 "Alert Eyes not on road level5" 21 "Alert Eyes not on road level6" 22 "Alert Eyes not on road level7" 23 "Alert Eyes not on road level8" 24 "Alert Eyes not on road level9" 25 "Alert Eyes not on road level10" 26 "Alert Eyes not on road level11" 27 "Alert Eyes not on road level12" 28 "Alert Eyes not on road level13" 29 "Alert Eyes not on road level14" 30 "Alert Eyes not on road level15" 31 "Alert Eyes not on road level16";
VAL_ 972 ADL3_TransitionState 0 "No display" 1 "User activation : OFF to NotOperational Available wo Longi" 2 "User deactivation : NotOperational Available to OFF" 3 "NotOperational Available wo Longi to NotOperational Available w Longi" 4 "NotOperational Available w Longi to NotOperational Available wo Longi" 5 "NotOperational Available w Longi to OFF" 6 "NotOperational Available w Longi to ON Ready" 7 "ON Ready to NotOperational Available w Longi" 8 "ON Ready to NotOperational Available wo Longi" 9 "ON Ready to OFF" 10 "ON Ready to ON Operational" 11 "ON Operational to ON Ready level1" 12 "ON Operational to ON Ready level2" 13 "ON Operational to NotOperational Available w Longi level1" 14 "ON Operational to NotOperational Available w Longi level2" 15 "ON Operational to NotOperational Available wo Longi level1" 16 "ON Operational to NotOperational Available wo Longi level2" 17 "ON Operational to OFF level1" 18 "ON Operational to OFF level2" 19 "Not used" 20 "Not used" 21 "Not used" 22 "Not used" 23 "Not used" 24 "Not used" 25 "Not used" 26 "Not used" 27 "Not used" 28 "Not used" 29 "Not used" 30 "Not used" 31 "Not used";
VAL_ 972 AD_CutinLeftDisplay 0 "No display" 1 "Motorbike Alert without risk" 2 "Motorbike Alert with risk" 3 "Truck Alert without risk" 4 "Truck Alert with risk" 5 "Car Alert without risk" 6 "Car Alert with risk" 7 "Unknown Alert without risk" 8 "Unknown Alert with risk" 9 "Not used" 10 "Not used" 11 "Not used" 12 "Not used" 13 "Not used" 14 "Not used" 15 "Not used";
VAL_ 972 AD_CancelReasonRER 0 "No request" 1 "Reemission request";
VAL_ 972 AD_CutinRightDisplay 0 "No display" 1 "Motorbike Alert without risk" 2 "Motorbike Alert with risk" 3 "Truck Alert without risk" 4 "Truck Alert with risk" 5 "Car Alert without risk" 6 "Car Alert with risk" 7 "Unknown Alert without risk" 8 "Unknown Alert with risk" 9 "Not used" 10 "Not used" 11 "Not used" 12 "Not used" 13 "Not used" 14 "Not used" 15 "Not used";
VAL_ 973 AD2_VehicleLocator 0 "Table Value346936";
VAL_ 986 ALC_Distance 0 "No Display";
VAL_ 986 AD2_HandsOff_MRM 0 "No display" 1 "Alert Eyes on road level1" 2 "Alert Eyes on road level2" 3 "Alert Eyes on road level3" 4 "Alert Eyes on road level4" 5 "Alert Eyes on road level5" 6 "Alert Eyes on road level6" 7 "Alert Eyes on road level7" 8 "Alert Eyes on road level8" 9 "Alert Eyes on road level9" 10 "Alert Eyes on road level10" 11 "Alert Eyes on road level11" 12 "Alert Eyes on road level12" 13 "Alert Eyes on road level13" 14 "Alert Eyes on road level14" 15 "Alert Eyes on road level15" 16 "Alert Eyes not on road level1" 17 "Alert Eyes not on road level2" 18 "Alert Eyes not on road level3" 19 "Alert Eyes not on road level4" 20 "Alert Eyes not on road level5" 21 "Alert Eyes not on road level6" 22 "Alert Eyes not on road level7" 23 "Alert Eyes not on road level8" 24 "Alert Eyes not on road level9" 25 "Alert Eyes not on road level10" 26 "Alert Eyes not on road level11" 27 "Alert Eyes not on road level12" 28 "Alert Eyes not on road level13" 29 "Alert Eyes not on road level14" 30 "Alert Eyes not on road level15" 31 "Alert Eyes not on road level16";
VAL_ 986 AD_FocusStateRequest 0 "No Request" 1 "Focus level1" 2 "Focus level2" 3 "Focus level3";
VAL_ 986 AD_AvailabilityLevel 0 "No display" 1 "AD Availability Level1 (dn)" 2 "AD Availability Level2 (up/dn)" 3 "AD Availability Level3" 4 "AD Availability Level4" 5 "AD Availability Level5" 6 "AD Availability Level6 (up/dn)" 7 "AD Availability Level7 (up/dn)" 8 "AD Availability Level8 (dn)" 9 "AD Availability Level9 (dn)" 10 "AD Availability Level10 (up/dn)" 11 "AD Availability Level11 (up)" 12 "Not used" 13 "Not used" 14 "Not used" 15 "Not used";
VAL_ 986 ADL3_Status 0 "No display" 1 "L3 Activated" 2 "L3 Deactivated" 3 "Not Used";
VAL_ 986 AD_MRM_PhaseCounter 0 "No display";
VAL_ 993 FirstParkStartPositionID 0 "Unavailable";
VAL_ 993 SecondParkStartPositionID 0 "Unavailable";
VAL_ 993 ThirdParkStartPositionID 0 "Unavailable";
VAL_ 993 ThirdParkStartPositionDistanceType 0 "Real link distance" 1 "Straight line distance";
VAL_ 993 SecondParkStartPositionDistanceType 0 "Real link distance" 1 "Straight line distance";
VAL_ 993 FirstParkStartPositionDistanceType 0 "Real link distance" 1 "Straight line distance";
VAL_ 996 DriverSeatStatus 0 "Operational" 1 "In Failure Mode" 2 "Reserved" 3 "Unavailable";
VAL_ 996 DriverMassageProgramState_v3 0 "Massage is not running" 1 "Program massage 1 is runnning" 2 "Program massage 2 is runnning" 3 "Program massage 3 is runnning" 4 "Program massage 4 is runnning" 5 "Program massage 5 is runnning" 6 "Program massage 6 is runnning" 7 "Program massage 7 is runnning" 8 "Program massage 8 is runnning" 9 "Program massage 9 is runnning" 10 "Program massage 10 is runnning" 11 "Program massage 11 is runnning" 12 "Program massage 12 is runnning" 13 "Program massage 13 is runnning" 14 "Program massage 14 is runnning" 15 "Not used";
VAL_ 999 BCM_SteeringCommandK 0 "button released" 1 "button pressed";
VAL_ 999 BCM_SteeringCommandJ 0 "button released" 1 "button pressed";
VAL_ 999 BCM_SteeringCommandI 0 "button released" 1 "button pressed";
VAL_ 999 BCM_SteeringCommandO 0 "button released" 1 "button pressed";
VAL_ 999 BCM_SteeringCommandN 0 "button released" 1 "button pressed";
VAL_ 999 BCM_SteeringCommandM 0 "button released" 1 "button pressed";
VAL_ 999 BCM_SteeringCommandP 0 "button released" 1 "button pressed";
VAL_ 1000 APPRUN_ActivationState 0 "Approach Unlock is deactivated (initial value)" 1 "Approach Unlock is activated";
VAL_ 1000 WAL_ActivationState 0 "Walk Away Locking is deactivated (initial value)" 1 "Walk Away Locking is activated";
VAL_ 1000 IKeyAccessActivationState 0 "iKey Access is Desactivated" 1 "iKey Access is Activated";
VAL_ 1001 PassengerMassageProgramState_v3 0 "Massage is not running" 1 "Program massage 1 is runnning" 2 "Program massage 2 is runnning" 3 "Program massage 3 is runnning" 4 "Program massage 4 is runnning" 5 "Program massage 5 is runnning" 6 "Program massage 6 is runnning" 7 "Program massage 7 is runnning" 8 "Program massage 8 is runnning" 9 "Program massage 9 is runnning" 10 "Program massage 10 is runnning" 11 "Program massage 11 is runnning" 12 "Program massage 12 is runnning" 13 "Program massage 13 is runnning" 14 "Program massage 14 is runnning" 15 "Not used";
VAL_ 1003 AD_SteeringWheelTakeOverAlert 0 "No Alert" 1 "Alert level1" 2 "Alert level2" 3 "Alert level3" 4 "Alert level4" 5 "Alert level5" 6 "Alert level6" 7 "Alert level7";
VAL_ 1003 AD_StatusDisplay 0 "No display" 1 "AD2L2 HON NotOperational" 2 "AD2L2 HON Operational" 3 "AD2L2 HOFF NotOperational" 4 "AD2L2 HOFF Operational" 5 "AD1L3 NotOperational Available wo Longi" 6 "AD1L3 NotOperational Available w Longi" 7 "AD1L3 Ready" 8 "AD1L3 Operational" 9 "AD_TemporaryFailure" 10 "AD_PermanentFailure" 11 "Not used" 12 "Not used" 13 "Not used" 14 "Not used" 15 "Not used";
VAL_ 1003 ALC_HandsRequest 0 "Hands NotRequested" 1 "Hands Requested without risk" 2 "Hands Requested with risk" 3 "Not used";
VAL_ 1003 ALC_StatusDisplay 0 "No display" 1 "Not Operational" 2 "Operational waiting HandsON" 3 "Operational waiting HandsOFF" 4 "Operational Active HandsON" 5 "Operational Active HandsOFF" 6 "Operational Standby" 7 "Not used";
VAL_ 1004 MMI_Req_log_func6 0 "Not used" 1 "ON" 2 "OFF" 3 "Unavailable";
VAL_ 1004 MMI_Req_log_func5 0 "Not used" 1 "ON" 2 "OFF" 3 "Unavailable";
VAL_ 1004 MMI_Req_log_func4 0 "Not used" 1 "ON" 2 "OFF" 3 "Unavailable";
VAL_ 1004 MMI_Req_log_func3 0 "Not used" 1 "ON" 2 "OFF" 3 "Unavailable";
VAL_ 1004 MMI_Req_log_func10 0 "Not used" 1 "ON" 2 "OFF" 3 "Unavailable";
VAL_ 1004 MMI_Req_log_func9 0 "Not used" 1 "ON" 2 "OFF" 3 "Unavailable";
VAL_ 1004 MMI_Req_log_func8 0 "Not used" 1 "ON" 2 "OFF" 3 "Unavailable";
VAL_ 1004 MMI_Req_log_func7 0 "Not used" 1 "ON" 2 "OFF" 3 "Unavailable";
VAL_ 1008 MMI_Req_log_func2 0 "Not used" 1 "ON" 2 "OFF" 3 "Unavailable";
VAL_ 1008 MMI_Req_log_func1 0 "Not used" 1 "ON" 2 "OFF" 3 "Unavailable";
VAL_ 1012 TCU_MuteRadioOrder 0 "No mute radio order" 1 "Mute radio order";
VAL_ 1012 IVC_FOTAbusyFlag 0 "IVC FOTA Busy" 1 "IVC FOTA Ready";
VAL_ 1012 IVC_FOTA_Status_v2 0 "idle" 1 "Inventory read in progress" 2 "Inventory read complete" 3 "Distribution in progress" 4 "Integrity check in progress" 5 "Distribution complete" 6 "Installation in progress" 7 "Installation complete" 8 "Vehicle Condition check in progress" 9 "Ready for activation" 10 "Activation in progress" 11 "Activation complete" 12 "Cancel in progress" 13 "Cancel complete" 14 "Rollback in progress" 15 "Rollback complete" 16 "Reboot in progress" 17 "Setting in progress" 18 "Setting completed" 19 "Inventory upload in progress" 20 "Inventory upload completed" 21 "Not used" 22 "Not used" 23 "Not used" 24 "Not used" 25 "Not used" 26 "Not used" 27 "Not used" 28 "Not used" 29 "Not used" 30 "Not used" 31 "invalid";
VAL_ 1012 ECALL_StateDisplay_V4 0 "No message" 1 "Not used" 2 "Not used" 3 "Manual Ecall - push to cancel" 4 "Manual Ecall launch" 5 "Ecall auto launch" 6 "Manual Ecall failure" 7 "Ecall launch cancelled" 8 "Ecall on going" 9 "Voice communication on going - MSD not sent" 10 "Voice communication on going - MSD sent" 11 "Voice call failure" 12 "End of voice communication" 13 "Incoming call" 14 "Not used" 15 "Ecall malfunction";
VAL_ 1017 UTA_VigilanceLevelDisplay 0 "UTA not operational" 1 "Vigilance Level 1" 2 "Vigilance Level 2" 3 "Vigilance Level 3" 4 "Vigilance Level 4" 5 "Vigilance Level 5" 6 "Vigilance Level 6" 7 "Vigilance Level 7" 8 "Vigilance Level 8" 9 "Not used" 10 "Not used" 11 "Not used" 12 "Not used" 13 "Not used" 14 "Not used" 15 "Unavailable";
VAL_ 1017 UTA_VigilanceAlertDisplay_v2 0 "NO Vigilance Alert Display" 1 "Vigilance Alert Display" 2 "Reemission Request" 3 "Not used";
VAL_ 1028 VSPSoundActivationState 0 "Not Activated" 1 "Activated";
VAL_ 1028 VSPsoundChoiceActivationState 0 "VSP Choice 1" 1 "VSP Choice 2" 2 "VSP Choice 3" 3 "VSP Choice 4" 4 "VSP Choice 5" 5 "Not used" 6 "Not used" 7 "Not used";
VAL_ 1045 SecondRightSeatModeReq 0 "No request" 1 "Seat Heater" 2 "Seat Ventilation" 3 "Not used";
VAL_ 1045 SecondLeftSeatModeReq 0 "No request" 1 "Seat Heater" 2 "Seat Ventilation" 3 "Not used";
VAL_ 1045 FrontRightSeatModeReq 0 "No request" 1 "Seat Heater" 2 "Seat Ventilation" 3 "Not used";
VAL_ 1045 FrontLeftSeatModeReq 0 "No request" 1 "Seat Heater" 2 "Seat Ventilation" 3 "Not used";
VAL_ 1045 FaceID_temporary_Failure 0 "No display" 1 "Camera temporary OBSTRUCTION" 2 "Camera temporary DIRTY" 3 "Camera temporary FACE MASKED/Nose masked" 4 "Camera temporary EYES MASKED" 5 "Camera temporary MASKED BY STEERING WHEEL" 6 "Camera temporary Part of face" 7 "Camera temporary Too large face angle" 8 "Camera temporary Eye closed" 9 "Camera temporary Not alive" 10 "Camera temporary Poor light condition" 11 "Camera temporary Bad face" 12 "Camera temporary No face detected" 13 "Camera temporary Too large/small face" 14 "Not used" 15 "Unavailable value";
VAL_ 1045 FaceID_RegistrationState_IVI 0 "Initial Value" 1 "Start" 2 "Registering" 3 "Complete" 4 "Stop (Cancel)" 5 "Time Out" 6 "Error" 7 "Non P gear" 8 "Already Registered" 9 "Not used" 10 "Not used" 11 "Not used" 12 "Not used" 13 "Not used" 14 "Not used" 15 "Not used";
VAL_ 1045 FaceID_permanent_Failure 0 "No failure (default)" 1 "failure" 2 "Reserved" 3 "Unavailable value";
VAL_ 1045 FaceID_RecognitionState_IVI 0 "Initial Value" 1 "Start/Recognizing" 2 "Complete" 3 "Stop (Cancel)" 4 "Time Out" 5 "Error" 6 "Non P gear" 7 "Not used";
VAL_ 1045 ChargerAtDestination 0 "Destination is not a charging station" 1 "Destination is a charging station" 2 "Not Used" 3 "Unavailable";
VAL_ 1045 ChargerAtWaypoint 0 "Waypoint is not a charging station" 1 "Waypoint is a charging station" 2 "Not Used" 3 "Unavailable";
VAL_ 1047 AVM_WarningDisplayRequest 0 "No message" 1 "Message 1" 2 "Message 2" 3 "Message 3" 4 "Message 4" 5 "Message 5" 6 "Message 6" 7 "Message 7";
VAL_ 1047 HFP_ExtendedInstrContentDisplay2 0 "instruction 1" 1 "instruction 2" 2 "instruction 3" 3 "instruction 4" 4 "instruction 5" 5 "instruction 6" 6 "instruction 7" 7 "instruction 8" 8 "instruction 9" 9 "instruction 10" 10 "instruction 11" 11 "instruction 12" 12 "instruction 13" 13 "instruction 14" 14 "instruction 15" 15 "instruction 16" 16 "instruction 17" 17 "instruction 18" 18 "instruction 19" 19 "instruction 20" 20 "instruction 21" 21 "instruction 22" 22 "instruction 23" 23 "instruction 24" 24 "instruction 25" 25 "instruction 26" 26 "instruction 27" 27 "instruction 28" 28 "instruction 29" 29 "instruction 30" 30 "instruction 31" 31 "unavailable";
VAL_ 1049 MuteRadioOrderByAAM 0 "No mute requested" 1 "Mute requested";
VAL_ 1049 AAM_DigitalInputMonitoring7 0 "Not used" 1 "ON" 2 "OFF" 3 "Unavailable";
VAL_ 1049 AAM_DigitalInputMonitoring6 0 "Not used" 1 "ON" 2 "OFF" 3 "Unavailable";
VAL_ 1058 OSPSpeedUnit 0 "km/h" 1 "mph" 2 "not used" 3 "unavailable";
VAL_ 1065 HVBatteryLow 0 "No HV Battery Low Display Requested" 1 "HV Battery Low Display Requested";
VAL_ 1065 ChargingPlugConnected_v2 0 "No display request (Charging Plug is NOT Connected)" 1 "Charging Plug is Connected" 2 "PWT Start impossible - Plug Connected" 3 "Unavailable value";
VAL_ 1065 AuxEnergyFlow 0 "No power" 1 "Battery to accessory - Low power" 2 "Battery  to accessory - High power" 3 "Not used";
VAL_ 1065 AllWheelDriveFlag 0 "2WD" 1 "AWD";
VAL_ 1065 EcoNavStatus_v2 0 "Function not activated" 1 "Awaiting data transmission" 2 "On computing" 3 "On regulation" 4 "On updating" 5 "Failed to compute" 6 "Solution with ask to recharge on driving" 7 "Solution with ask to recharge at station" 8 "No ZEV Zone Function" 9 "Not Used" 10 "Not Used" 11 "Not Used" 12 "Not Used" 13 "Not Used" 14 "Not Used" 15 "Not Used";
VAL_ 1065 TireRotatingDirection 0 "Stop" 1 "Forward direction" 2 "Back direction" 3 "Unavailable value";
VAL_ 1066 HVbatteryEmpty 0 "No alert" 1 "Alert";
VAL_ 1066 HVbatteryChargeType_v2 0 "No charge" 1 "Normal charge" 2 "Accelerated charge" 3 "Fast charge" 4 "Quick charge" 5 "Ultra fast" 6 "V2H" 7 "V2G";
VAL_ 1066 RegenBrakingLevelDisplay 0 "Regenerative braking level 0" 1 "Regenerative braking level 1" 2 "Regenerative braking level 2" 3 "Regenerative braking level 3" 4 "Regenerative braking level 4" 5 "Regenerative braking level 5" 6 "Not Used" 7 "No display";
VAL_ 1068 HEV_ChargeFailureDisplay 0 "No Alert" 1 "Alert";
VAL_ 1068 EngineMotorEnergyFlow_v2 0 "No Power" 1 "Engine to Motor - Low Power" 2 "Engine to Motor - Mid Power" 3 "Engine to Motor - High Power" 4 "Motor to Engine - Low Power" 5 "Motor to Engine - Mid Power" 6 "Motor to Engine - High Power" 7 "Not used";
VAL_ 1068 HVchargerStatus 0 "No HV charge" 1 "HV battery charge" 2 "HV consumers charge" 3 "Not used";
VAL_ 1068 VehicleTractionMode 0 "Vehicle not in traction mode" 1 "Vehicle in charge" 2 "Vehicle in full electric mode" 3 "Vehicle in hybrid serial mode" 4 "Vehicle in thermic mode" 5 "Vehicle in hybrid parallel mode" 6 "Not Used" 7 "Unavailable value";
VAL_ 1068 EngineWheelEnergyFlow_v2 0 "No Power" 1 "Engine to Wheel- Low Power" 2 "Engine to Wheel - Mid Power" 3 "Engine to Wheel - High Power" 4 "Wheel to Engine - Low Power" 5 "Wheel to Engine - Mid Power" 6 "Wheel to Engine - High Power" 7 "Not used";
VAL_ 1068 BatteryMotorEnergyFlow_v2 0 "No Power" 1 "Battery to Motor - Low Power" 2 "Battery to Motor - Mid Power" 3 "Battery to Motor - High Power" 4 "Motor to Battery - Low Power" 5 "Motor to Battery - Mid Power" 6 "Motor to Battery - High Power" 7 "Not used";
VAL_ 1068 BatteryRearMotorEnergyFlow 0 "No Power" 1 "Battery to Rear Motor - Low Power" 2 "Battery to Rear Motor - Mid Power" 3 "Battery to Rear Motor - High Power" 4 "Rear Motor to Battery - Low Power" 5 "Rear Motor to Battery - Mid Power" 6 "Rear Motor to Battery - High Power" 7 "Unavailable";
VAL_ 1068 ChargingStatusDisplay_v2 0 "No charge" 1 "Waiting a planned charge" 2 "Ended charge" 3 "Charge in progress" 4 "Charge failure" 5 "Waiting for current charge" 6 "Energy Flap opened: welcome MMI" 7 "Stopped charge(SOC is not full)" 8 "Charging is continue with full SOC" 9 "V2G" 10 "V2L Outside" 11 "V2G in discharge" 12 "V2G in charge" 13 "Not used" 14 "Not used" 15 "Not used";
VAL_ 1076 SwitchOffSESDisturbers 0 "No request" 1 "Disturbers switch off requested";
VAL_ 1081 TCS_DeactivationState 0 "TCS not deactivated" 1 "TCS deactivated";
VAL_ 1083 DVR_FOTA_Status 0 "idle" 1 "Inventory read in progress" 2 "Inventory read complete" 3 "Distribution in progress" 4 "Integrity check in progress" 5 "Distribution complete" 6 "Installation in progress" 7 "Installation complete" 8 "Vehicle Condition check in progress" 9 "Ready for activation" 10 "Activation in progress" 11 "Activation complete" 12 "Cancel in progress" 13 "Cancel complete" 14 "Rollback in progress" 15 "Rollback complete" 16 "Reboot in progress" 17 "Setting in progress" 18 "Setting completed" 19 "Inventory upload in progress" 20 "Inventory upload completed" 21 "Not used" 22 "Not used" 23 "Not used" 24 "Not used" 25 "Not used" 26 "Not used" 27 "Not used" 28 "Not used" 29 "Not used" 30 "Not used" 31 "invalid";
VAL_ 1099 ATCVT_RangeIndicationExtended 0 "OFF" 1 "P range" 2 "R range" 3 "N range" 4 "D range" 5 "S range" 6 "L range" 7 "B range" 8 "1st range" 9 "2nd range" 10 "3rd range" 11 "4th range" 12 "5th range" 13 "6th range" 14 "7th range" 15 "8th range" 16 "9th range" 17 "10th range" 18 "Not used" 19 "Not used" 20 "M1st" 21 "M2nd" 22 "M3rd" 23 "M4th" 24 "M5th" 25 "M6th" 26 "M7th" 27 "M8th" 28 "M9th" 29 "M10th" 30 "Not used" 31 "Not used" 32 "Auto 1st" 33 "Auto 2nd" 34 "Auto 3rd" 35 "Auto 4th" 36 "Auto 5th" 37 "Auto 6th" 38 "Auto 7th" 39 "Auto 8th" 40 "Auto 9th" 41 "Auto 10th" 42 "Not used" 43 "Not used" 44 "Not used" 45 "Not used" 46 "Not used" 47 "Not used" 48 "Not used" 49 "Not used" 50 "Not used" 51 "Not used" 52 "Not used" 53 "Not used" 54 "Not used" 55 "Not used" 56 "Not used" 57 "Not used" 58 "Not used" 59 "Not used" 60 "Not used" 61 "Not used" 62 "Not used" 63 "Not used";
VAL_ 1099 ATCVTFail 0 "Not fail" 1 "Fail";
VAL_ 1100 RST_LaunchControlReady 0 "Launch Control Not Available" 1 "Launch Control Not Active" 2 "Launch Control Active" 3 "Launch Control Take-Off";
VAL_ 1100 TransmRangeEngaged_Current 0 "declutched at rest" 1 "1st range" 2 "2nd range" 3 "3rd range" 4 "4th range" 5 "5th range" 6 "6th range" 7 "7th range" 8 "8th range" 9 "reverse" 10 "neutral or parking" 11 "CVT in continuous mode" 12 "9th range" 13 "10th range" 14 "Not used" 15 "AT in limphome";
VAL_ 1101 FlashingIndicatorStatusDisplay 0 "left and right flashing indicators OFF" 1 "left flashing indicator ON and right flashing indicator OFF" 2 "left flashing indicator OFF and right flashing indicator ON" 3 "left flashing indicator ON and right flashing indicator ON" 4 "Not used" 5 "Not used" 6 "Not used" 7 "Unavailable";
VAL_ 1101 MirrorFoldingMode 0 "Unavailable" 1 "Automatic/Open Mode" 2 "Folding Forced Mode" 3 "Not Used";
VAL_ 1101 OldPressureRL_twin 0 "Pressure up to date" 1 "Pressure not up to date";
VAL_ 1101 OldPressureRR_twin 0 "Pressure up to date" 1 "Pressure not up to date";
VAL_ 1101 WheelStateRL_twin 0 "Pressure ok and no failure" 1 "Failure" 2 "Underinflation" 3 "Underinflation and failure" 4 "Puncture" 5 "Puncture and failure" 6 "Puncture and underinflation" 7 "Puncture and underinflation and failure";
VAL_ 1101 WheelStateRR_twin 0 "Pressure ok and no failure" 1 "Failure" 2 "Underinflation" 3 "Underinflation and failure" 4 "Puncture" 5 "Puncture and failure" 6 "Puncture and underinflation" 7 "Puncture and underinflation and failure";
VAL_ 1102 AutoLockActivationState 0 "Auto Lock is not activated" 1 "Auto Lock with Speed is activated" 2 "Auto Lock with Park-out is activated" 3 "Not used";
VAL_ 1102 AutoLightSensitivityStatus 0 "Configuration 1 activated" 1 "Configuration 2 activated" 2 "Configuration 3 activated" 3 "Configuration 4 activated";
VAL_ 1102 AutoFrontWiperActivationStatus 0 "Auto Front wiper de-activation requested" 1 "Auto Front wiper activation requested" 2 "Not used" 3 "Not used";
VAL_ 1102 AHL_ActivationState 0 "Not used" 1 "AHL activated" 2 "AHL NOT activated" 3 "Unavailable";
VAL_ 1102 RearWiperStatus 0 "Unavailable" 1 "Rear wiper activation requested" 2 "Rear wiper de-activation requested" 3 "Not used";
VAL_ 1102 AutoUnLockActivationState 0 "Auto UnLock is not activated" 1 "Auto UnLock with IGN OFF is activated" 2 "Auto UnLock with Park is activated" 3 "Not used";
VAL_ 1102 AmbientLightingPatternState 0 "Activated" 1 "Deactivated";
VAL_ 1102 AutoFMHactivationState 0 "Activated" 1 "Deactivated";
VAL_ 1102 AutoInternalLightingState 0 "Deactivation" 1 "Activation";
VAL_ 1102 AutoFMHdurationState 0 "30 sec" 1 "45 sec" 2 "60 sec" 3 "90 sec" 4 "120 sec" 5 "150 sec" 6 "180 sec" 7 "Not used";
VAL_ 1102 ADB_ActivationState 0 "Activated" 1 "Deactivated";
VAL_ 1102 AutoReLockActivationState 0 "Auto ReLock OFF" 1 "Auto ReLock ON";
VAL_ 1102 FrontRearWiperDropStatus 0 "Wiper Drop Deactivated" 1 "Wiper Drop Activated";
VAL_ 1102 WGSactivationState 0 "Activated" 1 "Deactivated";
VAL_ 1102 OtherLampActivateStatus 0 "Deactivated" 1 "Activated";
VAL_ 1102 LowBeamDisplay 0 "low beam display not requested" 1 "low beam display requested";
VAL_ 1102 HighBeamDisplay 0 "High beam display not requested" 1 "High beam display requested";
VAL_ 1102 AmbientLightingArea5Status 0 "AmbientLighting Area 5 Deactivated" 1 "AmbientLighting Area 5 Activated";
VAL_ 1102 AmbientLightingArea4Status 0 "AmbientLighting Area 4 Activated" 1 "AmbientLighting Area 4 Deactivated";
VAL_ 1102 RR_FOG_StatusbyVoice 0 "No Request" 1 "Deactivated" 2 "Activated" 3 "Already deactivated" 4 "Already activated" 5 "To change AUTO position" 6 "To change HL on" 7 "No function";
VAL_ 1103 BCM_SteeringPushToTalkCommand 0 "button released" 1 "button pressed";
VAL_ 1103 BCM_SteeringPhoneCommand 0 "button released" 1 "button pressed";
VAL_ 1103 BCM_SteeringCommandE 0 "button released" 1 "button pressed";
VAL_ 1103 BCM_SteeringCommandA 0 "button released" 1 "button pressed";
VAL_ 1103 BCM_MMISteeringSwitchesFailure 0 "No MMI steering switches failure" 1 "MMI steering switches failure";
VAL_ 1103 AccessModeState 0 "Standard mode" 1 "Secure mode";
VAL_ 1103 ExtLightCheck_Result_display 0 "No display" 1 "Canceled" 2 "Aborted" 3 "Completed" 4 "Reserved" 5 "Reserved" 6 "Reserved" 7 "Reserved";
VAL_ 1103 TrailerLightCheck_Status 0 "Operation not allowed" 1 "Operation allowed" 2 "Runing" 3 "Unavailable";
VAL_ 1104 ExternalTempDisplayUnit 0 "display mode in °C" 1 "display mode in °F";
VAL_ 1104 DimmingState 0 "Not used" 1 "Step 1" 2 "Step 2" 3 "Step 3" 4 "Step 4" 5 "Step 5" 6 "Step 6" 7 "Step 7" 8 "Step 8" 9 "Step 9" 10 "Step 10" 11 "Step 11" 12 "Step 12" 13 "Step 13" 14 "Step 14" 15 "Step 15" 16 "Step 16" 17 "Step 17" 18 "Step 18" 19 "Step 19" 20 "Step 20" 21 "Step 21" 22 "Not used" 23 "Not used" 24 "Not used" 25 "Not used" 26 "Not used" 27 "Not used" 28 "Not used" 29 "Not used" 30 "Not used" 31 "Not used";
VAL_ 1104 SteeringPushToTalkCommand 0 "Button released" 1 "Button pressed";
VAL_ 1104 SteeringPhoneCommand 0 "Button released" 1 "Button pressed";
VAL_ 1104 UnitDistanceDisplayState 0 "displayed unit in km" 1 "displayed unit in mph";
VAL_ 1104 Meter_ADACresetRequest 0 "Reset  METER not requested" 1 "Reset  METER requested";
VAL_ 1104 DiagnosedFuelLow 0 "Unavailable" 1 "Not empty" 2 "Empty" 3 "Not used";
VAL_ 1104 MuteRadioOrder 0 "No mute radio order" 1 "Mute radio order";
VAL_ 1104 WelcomeSequenceStatus 0 "Unavailable" 1 "Sequence not Started" 2 "Sequence in progress" 3 "Sequence Done";
VAL_ 1104 DisplayedOilLevel 0 "warning" 1 "1 bargraph element displayed" 2 "2 bargraph element displayed" 3 "3 bargraph element displayed" 4 "4 bargraph element displayed" 5 "5 bargraph element displayed" 6 "6 bargraph element displayed" 7 "7 bargraph element displayed" 8 "8 bargraph element displayed" 9 "Not used" 10 "Not used" 11 "Not used" 12 "Not used" 13 "Not used" 14 "Not used" 15 "not available";
VAL_ 1104 MeterVolumeState 0 "Unavailable" 1 "Volume 1" 2 "Volume 2" 3 "Volume 3";
VAL_ 1104 FuelLevelDisplayed 0 "petrol tank reserve";
VAL_ 1104 SteeringFavoriteCommand 0 "Favorite button released" 1 "Favorite button pushed";
VAL_ 1104 SteeringMultiModeCommand 0 "Multi mode button released" 1 "Multi mode button pushed";
VAL_ 1105 DisplayedSpeedUnit 0 "Speed Unit in kmph" 1 "Speed Unit in mph";
VAL_ 1105 GlobalVehicleWarningState 0 "No global  vehicle  Fault" 1 "SERV is ON (alert type R3)" 2 "STOP is ON (alert type D3)" 3 "SERV and STOP are ON (alert type R3& D3)";
VAL_ 1105 DayNightForBacklights 0 "Day" 1 "Twilight" 2 "Night" 3 "Unavailable";
VAL_ 1105 ParkingBrakeStatus 0 "Not used" 1 "Automatic or manual Parking brake not applied" 2 "Automatic or manual Parking brake applied" 3 "Unavailable";
VAL_ 1106 AutoDimmingState 0 "AutoDimming Not activated" 1 "AutoDimming activated";
VAL_ 1106 DayNightStatusForB_Switches 0 "Conditionned backlight" 1 "Permanent backlight";
VAL_ 1106 AutoDimmingOffsetY0 0 "Unavailable" 1 "Step 1" 2 "Step 2" 3 "Step 3" 4 "Step 4" 5 "Step 5" 6 "Step 6" 7 "Step 7" 8 "Step 8" 9 "Step 9" 10 "Step 10" 11 "Step 11" 12 "Step 12" 13 "Step 13" 14 "Step 14" 15 "Step 15";
VAL_ 1107 NeutralContact 0 "not used" 1 "neutral contact not reached" 2 "neutral contact reached" 3 "unavailable";
VAL_ 1107 RearGearEngaged 0 "Not used" 1 "Rear Gear not Engaged" 2 "Rear Gear Engaged" 3 "unavailable";
VAL_ 1107 EngineHoodState 0 "Unvailable value" 1 "Hood opened" 2 "Hood closed" 3 "Not used";
VAL_ 1107 IgnitionSupplyConfirmation 0 "no primary ignition supply" 1 "primary ignition supply on";
VAL_ 1107 EEM_StaticPowerLimitationRequest 0 "No Request" 1 "Life on Board Low SOC power limitation" 2 "Delivery Mode power limitation" 3 "Battery Disconnection power limitation" 4 "Producer failure power limitation" 5 "Not used" 6 "Not used" 7 "Not used";
VAL_ 1107 LowBeamActivationStatus 0 "lowbeam OFF" 1 "lowbeam ON" 2 "Partial Lowbeam Failure" 3 "Total Lowbeam Failure";
VAL_ 1108 HandDrivingActivationState 0 "Right Hand Driving activated" 1 "Left Hand Driving activated";
VAL_ 1108 LowBatteryVoltageDisplay 0 "No display request" 1 "Battery weak" 2 "Battery weak : start engine" 3 "Battery in charge";
VAL_ 1108 AFS_ActivationState 0 "AFS activated" 1 "AFS deactivated";
VAL_ 1109 HDC_StatusDisplay 0 "HDC Not activated" 1 "HDC Activated" 2 "HDC in Control" 3 "HDC Failure";
VAL_ 1109 BrakingSystemStateDisplayRequest 0 "No failure" 1 "Failure";
VAL_ 1109 AccurateOdometer 0 "00h to 1Eh (available till 31km/h)";
VAL_ 1109 VehicleSpeedSign 0 "nul vehicle speed" 1 "Positive vehicle speed (= Forward motion)" 2 "Negative vehicle speed (= reverse motion)" 3 "Unavailable";
VAL_ 1109 EBDstateDisplayRequest 0 "No failure" 1 "Failure";
VAL_ 1109 ABSstateDisplayRequest 0 "No failure" 1 "Failure" 2 "In ext diag session" 3 "To be calibrated";
VAL_ 1109 VDCstateDisplayRequest 0 "No failure and no control" 1 "Failure" 2 "In active control" 3 "Not used";
VAL_ 1109 TPW_AcknowledgeResetDriver 0 "Waiting" 1 "Reset fail" 2 "Reset ack" 3 "TPW not activ";
VAL_ 1109 VDCdeactivationDisplayRequest 0 "No request" 1 "VDC deactivated display request";
VAL_ 1109 VDCactivationState 0 "VDC function activated" 1 "VDC function deactivated";
VAL_ 1109 TPW_TireCheckReminder 0 "No tire check reminder" 1 "Tire check reminder";
VAL_ 1109 TPW_Status 0 "System OK" 1 "Tyre under inflated" 2 "Failure" 3 "TPW not operational";
VAL_ 1116 GCC_IntendedVehicleMoment 0 "No display" 1 "Left external" 2 "Right external" 3 "Left internal" 4 "Right internal" 5 "Not Used" 6 "Not Used" 7 "Not Used";
VAL_ 1116 GCC_ActualVehicleMoment 0 "No display" 1 "Straight run" 2 "Turning left" 3 "Turning right";
VAL_ 1116 ASAactivationState 0 "Activated" 1 "Deactivated";
VAL_ 1116 ADA1ActivationState 0 "Activated" 1 "Deactivated";
VAL_ 1116 GCC_WheelBrake_FR 0 "Deactivated" 1 "Activated";
VAL_ 1116 GCC_WheelBrake_FL 0 "Deactivated" 1 "Activated";
VAL_ 1116 GCC_WheelBrake_RR 0 "Deactivated" 1 "Activated";
VAL_ 1116 GCC_WheelBrake_RL 0 "Deactivated" 1 "Activated";
VAL_ 1121 AirSusp_IndicatorRequest 0 "High:Grayout, Access:Grayout" 1 "High:Grayout, Access:OFF" 2 "High:Grayout, Access:ON" 3 "Reserve" 4 "High:OFF, Access:Grayout" 5 "High:OFF, Access:OFF" 6 "High:OFF, Access:ON" 7 "Reserve" 8 "High:ON, Access:Grayout" 9 "High:ON, Access:OFF" 10 "High:ON, Access:ON" 11 "Reserve" 12 "Reserve" 13 "Reserve" 14 "Reserve" 15 "Unavailable";
VAL_ 1135 AVM_UserAcknowledgement 0 "No user acknowledgement" 1 "User acknowledgement1" 2 "User acknowledgement2" 3 "Not Used";
VAL_ 1135 APA_UserAcknowledgement 0 "No user acknowledgement" 1 "User acknowledgement1" 2 "User acknowledgement2" 3 "Not Used";
VAL_ 1135 WelcomeFunctionAvailability 0 "Not ready" 1 "Sound available" 2 "Video available" 3 "Video and sound available";
VAL_ 1135 ContextV2X_ActivationRequest2 0 "No request" 1 "Automode ON request" 2 "Automode OFF request" 3 "Reset request";
VAL_ 1135 PushToTalkActivationDisplay 0 "No PTT activation" 1 "PTT activation : start to speak request";
VAL_ 1135 BluetoothConnectionDisplayStatus 0 "Not connected" 1 "Connection ongoing" 2 "Connected" 3 "Not Used";
VAL_ 1136 EngineControlFailureLevel2 0 "no Engine Control Failure Level 2 create by stoping the engine" 1 "Engine Control Failure Level 2 create by stoping the engine";
VAL_ 1136 EngineControlFailureLevel1 0 "no Engine Control Failure Level 1" 1 "Engine Control Failure Level 1";
VAL_ 1137 ShiftIndicator 0 "No display request (no freeshift function or not equipped)" 1 "UpShift display resques" 2 "DownShift display request " 3 "No Shift change display Request (by freeshift function";
VAL_ 1137 RequestedSpeedDisplayRequest 254 "CC/SL off or awaiting for a speed selection" 255 "CC/SL failure";
VAL_ 1137 EcoPedalMenuRequest 0 "Menu OFF" 1 "Menu ON  ";
VAL_ 1137 EcoPedalForceSettingStatus 0 "No request" 1 "ECO Pedal Force setting status OFF" 2 "ECO Pedal Force setting status Soft" 3 "ECO Pedal Force setting status Standard";
VAL_ 1137 CruiseControlStatus 0 "Cruise Control (CC) and Speed Limit (SL) OFF" 1 "SL active" 2 "SL on and (awaiting or suspended)" 3 "SL requested and in failure" 4 "CC active" 5 "CC ON and ( awaiting  or suspended)" 6 "CC requested and in failure" 7 "Vehicle not equipped with CC/SL / Not available";
VAL_ 1137 FreeKmCalculationAuthorization 0 "Free Km calculation OFF" 1 "Free Km calculation ON";
VAL_ 1138 SailingActivationIdleStatus 0 "Deactivated" 1 "Activated";
VAL_ 1138 PredictiveShiftActivationState 0 "Unavailable" 1 "Activated" 2 "Deactivated" 3 "Not used";
VAL_ 1138 SailingStopActivationState 0 "Activated" 1 "Deactivated";
VAL_ 1138 CruiseEcoActivationState 0 "Unavailable" 1 "ECO activated" 2 "ECO deactivated" 3 "Not used";
VAL_ 1140 LKA_AlertStatus 0 "No alert" 1 "Right alert" 2 "Left alert" 3 "Not used";
VAL_ 1140 LKA_ActivationState 0 "Unavailable" 1 "Activated" 2 "Deactivated" 3 "Not used";
VAL_ 1140 LKA_SWheelTakeOverAlert_v3 0 "No Alert" 1 "Alert Lvl 1" 2 "Alert Lvl 2" 3 "Alert Lvl 3" 4 "Alert Lvl 4" 5 "Alert Lvl 5" 6 "Not used" 7 "Not used";
VAL_ 1143 RESstatus 0 "Unavailable" 1 "Reserved for safety" 2 "Reserved for safety" 3 "Normal engine start only" 4 "Reserved for safety" 5 "Reserved for safety" 6 "wait for RES / Presoak" 7 "Reserved for safety" 8 "Reserved for safety" 9 "Customer Starting" 10 "Reserved for safety" 11 "Reserved for safety" 12 "Remote Engine Start" 13 "Reserved for safety" 14 "Reserved for safety" 15 "Vehicle without RES";
VAL_ 1143 RearRightDoorState 0 "Unavailable Value" 1 "Rear Right door closed" 2 "Rear Right door open" 3 "Not Used";
VAL_ 1143 DriverSeatBeltFailureState 0 "No Monitoring" 1 "Supposed Driver Seat Belt Failure" 2 "Driver Seat Belt OK" 3 "Not used";
VAL_ 1143 V_WakeUpType 0 "Full Wake-Up Mode" 1 "Selective Wake-Up Mode 1" 2 "Selective Wake-Up Mode 2" 3 "Selective Wake-Up Mode 3" 4 "Selective Wake-Up Mode 4" 5 "Selective Wake-Up Mode 5" 6 "Selective Wake-Up Mode 6" 7 "Unavailable";
VAL_ 1143 V_WakeUpSleepCommand 0 "Go to Sleep" 1 "reserved" 2 "reserved" 3 "WakeUp";
VAL_ 1143 RearFogLightStateDisplay 0 "rear fog light OFF" 1 "rear fog light ON";
VAL_ 1143 DriverDoorState 0 "Unavailable Value" 1 "Driver door closed" 2 "Driver door open" 3 "Not Used";
VAL_ 1143 DriverSeatSensor 0 "Unavailable" 1 "Driver on seat detected" 2 "Driver on seat not detected" 3 "Not used";
VAL_ 1143 PassengerDoorState 0 "Unavailable Value" 1 "Passenger door closed" 2 "Passenger door open" 3 "Not used";
VAL_ 1143 RearLeftDoorState 0 "Unavailable Value" 1 "Rear left door closed" 2 "Rear left door open" 3 "Not Used";
VAL_ 1144 FrontFogLightsRequest 0 "front fog lights not requested" 1 "front fog lights requested";
VAL_ 1144 DriverDoorLockedStatus 0 "Driver Door Unlocked" 1 "Driver Door Locked";
VAL_ 1144 WarningLightsStatus 0 "Warning Lights OFF" 1 "Warning Lights ON";
VAL_ 1144 VehicleOutsideLockedState 0 "Vehicle not locked from the outside by the customer" 1 "Vehicle Locked from the outside by the customer";
VAL_ 1144 FrontFogLightsDisplay 0 "front fog lights display not requested" 1 "front fog lights display requested";
VAL_ 1144 RearFogLightsRequest 0 "rear fog lights not requested" 1 "rear fog lights requested";
VAL_ 1144 BrakeLampStatus 0 "Brake Lamp Off" 1 "Brake Lamp On";
VAL_ 1145 SingleDoorOpeningActivationState 0 "Single door opening activated" 1 "Single door opening deactivated";
VAL_ 1145 BCM_PresoakRequest 0 "Immediat Presoak Request" 1 "Programmed Presoak Request" 2 "Presoak Stop" 3 "Unavailable";
VAL_ 1145 DriverModeUpSwitchState 0 "Not Pushed" 1 "Pushed";
VAL_ 1145 SRU_Position 0 "Window position invalid" 1 "Window position 0 (closed)" 2 "Window sector 01" 3 "Window position 1" 4 "Window sector 12" 5 "Window position 2" 6 "Window sector 23" 7 "Window position 3" 8 "Window sector 34" 9 "Window position 4" 10 "Window sector 45" 11 "Window position 5" 12 "Window sector 56" 13 "Window position 6" 14 "Window sector 67" 15 "Window position 7";
VAL_ 1145 WindowPosition_FR 0 "Window position invalid" 1 "Window fully closed (HW or SW block position)" 2 "Window Short Drop position" 3 "Window in intermediate position (upper than RCU position)" 4 "Window RCU Drop position" 5 "Window in intermediate position (default or lower than RCU position)" 6 "Window fully open (SW block position)" 7 "Window fully open (HW block position)";
VAL_ 1145 WindowPosition_FL 0 "Window position invalid" 1 "Window fully closed (HW or SW block position)" 2 "Window Short Drop position" 3 "Window in intermediate position (upper than RCU position)" 4 "Window RCU Drop position" 5 "Window in intermediate position (default or lower than RCU position)" 6 "Window fully open (SW block position)" 7 "Window fully open (HW block position)";
VAL_ 1145 ProbableCustomerFeedBackNeed 0 "Customer feedback probably not needed" 1 "Customer feedback needed";
VAL_ 1145 WindowPosition_RR 0 "Window position invalid" 1 "Window fully closed (HW or SW block position)" 2 "Window Short Drop position" 3 "Window in intermediate position (upper than RCU position)" 4 "Window RCU Drop position" 5 "Window in intermediate position (default or lower than RCU position)" 6 "Window fully open (SW block position)" 7 "Window fully open (HW block position)";
VAL_ 1145 WindowPosition_RL 0 "Window position invalid" 1 "Window fully closed (HW or SW block position)" 2 "Window Short Drop position" 3 "Window in intermediate position (upper than RCU position)" 4 "Window RCU Drop position" 5 "Window in intermediate position (default or lower than RCU position)" 6 "Window fully open (SW block position)" 7 "Window fully open (HW block position)";
VAL_ 1145 DayNightSynthesis 0 "Day" 1 "Twilight" 2 "Night" 3 "Not used";
VAL_ 1145 BackDoorLockedStatus 0 "Back Door is Unlocked" 1 "Back Door is Locked";
VAL_ 1145 AutoFoldingActivationState 0 "Unavailable" 1 "Disable" 2 "IGN Unfold" 3 "Unlock + IGN Unfold";
VAL_ 1145 AutoACC2Status_MM 0 "Multimedia is done" 1 "Multimedia can receive / send messages" 2 "Multimedia can detect manual operation" 3 "Multimedia can work for all functions";
VAL_ 1145 RearRightDoorLockedStatus 0 "Rear Right Door is Unlocked" 1 "Rear Right Door is Locked";
VAL_ 1145 RearLeftDoorLockedStatus 0 "Rear Left Door is Unlocked" 1 "Rear Left Door is Locked";
VAL_ 1145 PassengerDoorLockedStatus 0 "Passenger Door is Unlocked" 1 "Passenger Door is Locked";
VAL_ 1145 MexSwitchState 0 "Not Pushed" 1 "Pushed";
VAL_ 1146 DriverSafetyBeltBuckleState 0 "SB Not monitored" 1 "SB unfastened" 2 "SB fastened" 3 "Unavailable";
VAL_ 1146 ClutchSwitchMinimumTravel 0 "Not used" 1 "Clutch pedal not pressed" 2 "Clutch pedal pressed at minimum" 3 "Unavailable";
VAL_ 1146 TailGateStatus 0 "Unvailable Value" 1 "TailGate is closed" 2 "TailGate is open" 3 "Not Used";
VAL_ 1146 VehicleStates 0 "Sleeping" 1 "Not used" 2 "CutoffPending" 3 "AutoACC  - BatTempoLevel" 4 "Not used" 5 "IgnitionLevel" 6 "StartingInProgress" 7 "PowertrainRunning" 8 "AutoStart" 9 "EngineSystemStop" 10 "Not used" 11 "Not used" 12 "Not used" 13 "Not used" 14 "Not used" 15 "Unavailable";
VAL_ 1146 BrakeInfoStatus 0 "Not used" 1 "Brake pedal not pressed" 2 "Brake pedal pressed" 3 "Not used" 4 "Brake pedal confirmed pressed" 5 "Not used" 6 "Not used" 7 "unavailable";
VAL_ 1146 DeliveryModeInformation_v2 0 "customer mode" 1 "delivery mode level 1" 2 "delivery mode level 2" 3 "Not used";
VAL_ 1146 FlashingIndicatorCommandPosition 0 "No direction indicator request" 1 "Left Flashing Indicators command ON" 2 "Right Flashing Indicators command ON" 3 "Not used";
VAL_ 1146 FlashingIndicatorStatus 0 "left and right flashing indicators OFF" 1 "left flashing indicator ON and right flashing indicator OFF" 2 "left flashing indicator OFF and right flashing indicator ON" 3 "left flashing indicator ON and right flashing indicator ON" 4 "Not used" 5 "Not used" 6 "Not used" 7 "Unavailable";
VAL_ 1146 GADE_v2 0 "Sleep or Crank fault, Disable DiagMuxDTC" 1 "AutoACC fault, Disable DiagMuxDTC" 2 "ALL fault, Disable DiagMuxDTC" 3 "ALL fault, Enable DiagMuxDTC" 4 "FOTA switch fault, Disable DiagMuxDTC" 5 "Not used" 6 "Not used" 7 "Unavailable";
VAL_ 1146 FrontWiperStatus_BCM 0 "front wiper stopped" 1 "low speed active" 2 "high speed active" 3 "Unavailable";
VAL_ 1146 TrailerPresence 0 "no trailer detected" 1 "trailer detected";
VAL_ 1146 FrontWipingRequest 0 "front wiper in stop position" 1 "front wiper forced to stop" 2 "Not used" 3 "Not used" 4 "unavailable" 5 "Not used" 6 "low speed wiping requested" 7 "high speed wiping requested";
VAL_ 1146 LightSensorStatus 0 "Day time according light level sensor " 1 "Night time according to light level sensor";
VAL_ 1146 HighBeamRequest 0 "high beam not requested" 1 "high beam requested";
VAL_ 1146 RainStatus 0 "no rain" 1 "rain" 2 "not used" 3 "unavailable";
VAL_ 1146 ClutchSwitchMaximumTravel 0 "Not used" 1 "Clutch pedal not pressed at maximum" 2 "Clutch pedal pressed at maximum" 3 "Unavailable";
VAL_ 1147 OilPressureWarning_ECM 0 "No Oil Pressure Warning" 1 "Oil Pressure Warning";
VAL_ 1147 WarningWaterTemp 0 "no water temperature warning" 1 "water temperature warning";
VAL_ 1150 SET_PositionInLane_State 0 "Invalid" 1 "To_hard_shoulder" 2 "Centre" 3 "To_overtake_lane";
VAL_ 1150 SET_VoiceGuidance_State 0 "Invalid" 1 "OFF" 2 "ON" 3 "Not Used";
VAL_ 1150 SET_LaneChangeSwiftness_State 0 "Invalid" 1 "Swift" 2 "Standard" 3 "Comfort";
VAL_ 1150 SET_NavigatDriveAssist_State 0 "Invalid" 1 "OFF" 2 "ON" 3 "Not Used";
VAL_ 1150 SET_OvertakeRelatSpeed_State 0 "Invalid" 1 "Low" 2 "Middle" 3 "High";
VAL_ 1150 SET_OvertakingAssist_State 0 "Invalid" 1 "OFF" 2 "ON" 3 "Not Used";
VAL_ 1150 SET_Acceleration_State 0 "Invalid" 1 "Quick" 2 "Standard" 3 "Gentle";
VAL_ 1150 SET_ALCActivationByTSIG_State 0 "Invalid" 1 "OFF" 2 "ON" 3 "Not Used";
VAL_ 1150 SET_CornerSpeedLevel_State 0 "Invalid" 1 "Quick" 2 "Standard" 3 "Gentle";
VAL_ 1150 SET_Deceleration_State 0 "Invalid" 1 "Quick" 2 "Standard" 3 "Gentle";
VAL_ 1150 ADL3_DisclaimerRepetitionRequest 0 "No repetition request" 1 "Repetition request";
VAL_ 1150 CASP_ActivationState 0 "Activated" 1 "Deactivated";
VAL_ 1150 SET_ADL3Activation_State 0 "Invalid" 1 "Activated" 2 "Deactivated" 3 "Not Used";
VAL_ 1150 SET_AD_HandsOff_State 0 "Invalid" 1 "Activated" 2 "Deactivated" 3 "Not Used";
VAL_ 1150 SET_ALC_AssistMode_State 0 "Invalid" 1 "Successive" 2 "Individual" 3 "Not Used";
VAL_ 1150 AES_ActivationState 0 "Unavailable" 1 "Activated" 2 "De-activated" 3 "Not used";
VAL_ 1172 EcoNavRechargeDuringTrip 0 "No Status" 1 "Recharge while driving" 2 "No recharge while driving" 3 "Recharge at Station" 4 "No Recharge at Station" 5 "Not used" 6 "Not used" 7 "Not used";
VAL_ 1172 SC_SmartchargingActivationStatus 0 "No value" 1 "Smart Charging Not activated" 2 "Smart Charging activated" 3 "Unavailable";
VAL_ 1172 SC_PresoakActivationStatus 0 "No value" 1 "Presoak Not activated" 2 "Presoak activated" 3 "Unavailable";
VAL_ 1179 eHBox_USB_MapInstall_LoadTime 0 "Table Value420480";
VAL_ 1179 eHBox_USBInstall_InsertedState 0 "Unavailable" 1 "Not inserted" 2 "Inserted" 3 "Not used";
VAL_ 1179 eHBox_USB_Save_MapStatus 0 "Unavailable" 1 "Success" 2 "Vehicle information save error" 3 "No space in USB" 4 "USB Device removed" 5 "Not used" 6 "Not used" 7 "Not used";
VAL_ 1179 eHBox_USBSave_InsertedState 0 "Unavailable" 1 "Not inserted" 2 "Inserted" 3 "Not used";
VAL_ 1179 eHBox_USBMapData_Status 0 "No status" 1 "Map of USB is same or older" 2 "Map of USB is incompatible with vehicle" 3 "Map of USB is incompatible with software version" 4 "Map information read error" 5 "Detect newer Map version" 6 "Not Used" 7 "Not Used";
VAL_ 1179 eHBox_USBMapInstall_DispRequest 0 "No Request" 1 "Request";
VAL_ 1179 eHBox_USB_MapdataContainState 0 "Unavailable" 1 "Not contain" 2 "Contain" 3 "Not used";
VAL_ 1179 eHBox_USB_MapInstallState 0 "No status" 1 "Map update is removed USB" 2 "Map update error" 3 "Map update is completed";
VAL_ 1181 eHBoxFailureStatus 0 "Unavailable Value" 1 "No Failure" 2 "System Failure" 3 "MapUpdateFail" 4 "NoMapAvailable" 5 "LicenseExpired" 6 "Reserved" 7 "Reserved";
VAL_ 1181 eHBox_USB_ReadMap_DispRequest 0 "No Request" 1 "Request";
VAL_ 1181 eHBox_LicenseState 0 "Inactive" 1 "Active";
VAL_ 1181 eHBox_MapUpdate_State 0 "No request" 1 "No State" 2 "Start to Save Map" 3 "Not inserted USB_save" 4 "Result of Save Map" 5 "Not inserted USB_install" 6 "Not contain" 7 "Read Map Version" 8 "Select Map Update" 9 "Result of Map Version" 10 "Map Updating" 11 "Result of Map Updating" 12 "Not used" 13 "Not used" 14 "Not used" 15 "Not used";
VAL_ 1181 eHBox_Current_Map_version 0 "Table Value420478";
VAL_ 1182 BatterytoOtherAccessories_flow 0 "No display" 1 "Battery to Other Accessories";
VAL_ 1182 BatterytoCabin_flow 0 "No display" 1 "Battery to Cabin";
VAL_ 1182 StateofBatteryTemperature_flow 0 "Battery state1" 1 "Battery state2" 2 "Battery state3" 3 "Not used";
VAL_ 1183 EstimatedVehicleMassValidity 0 "Valid" 1 "Not valid" 2 "Not Used" 3 "Unavailable";
VAL_ 1189 UserIdentification_IKeyLink_v2 0 "No request" 1 "Key No. 1" 2 "Key No. 2" 3 "Key No. 3" 4 "Key No. 4" 5 "Owner Key" 6 "Friend Key ID 1" 7 "Friend Key ID 2" 8 "Friend Key ID 3" 9 "Friend Key ID 4" 10 "Friend Key ID 5" 11 "Not used" 12 "Not used" 13 "Not used" 14 "Not used" 15 "Unavailable";
VAL_ 1196 FDC_CONFIG 0 "Table Value420481";
VAL_ 1202 MemoParkStatusDisplayRequest 0 "No display" 1 "Pattern1" 2 "Pattern2" 3 "Pattern3" 4 "Pattern4" 5 "Pattern5" 6 "Pattern6" 7 "Pattern7" 8 "Pattern8" 9 "Pattern9" 10 "Pattern10" 11 "Pattern11" 12 "Pattern12" 13 "Pattern13" 14 "Pattern14" 15 "Pattern15";
VAL_ 1202 TrailerGuidelineActivationState 0 "Activated" 1 "Deactivated";
VAL_ 1202 FAPK_ManeuverType_ParkOut 0 "Not selected" 1 "Selected" 2 "Not Used" 3 "Unavailable";
VAL_ 1202 FAPK_ManeuverType_Parallel 0 "Not selected" 1 "Selected" 2 "Not Used" 3 "Unavailable";
VAL_ 1202 FAPK_ManeuverType_AutoMode 0 "Not selected" 1 "Selected" 2 "Not Used" 3 "Unavailable";
VAL_ 1202 FAPK_ManeuverType_Angular 0 "Not selected" 1 "Selected" 2 "Not Used" 3 "Unavailable";
VAL_ 1202 FAPK_ManeuverType_Perpendicular 0 "Not selected" 1 "Selected" 2 "Not Used" 3 "Unavailable";
VAL_ 1210 Combo_EVchargeHLCRequest_v2 0 "No HLC Request" 1 "Hand Shake request" 2 "Charge parameter Discovery request" 3 "Cable Check request" 4 "Precharge request" 5 "Power delivery request" 6 "Current demand request" 7 "Metering receipt request" 8 "Welding detection request" 9 "Session stop request" 10 "Matching reset" 11 "Charging Status request" 12 "AC BPT" 13 "DC BPT" 14 "Handshake request_20" 15 "ACchargeLoopReq" 16 "ScheduleExchange request" 17 "Not used" 18 "Not used" 19 "Not used" 20 "Not used" 21 "Not used" 22 "Not used" 23 "Not used" 24 "Not used" 25 "Not used" 26 "Not used" 27 "Not used" 28 "Not used" 29 "Not used" 30 "Not used" 31 "Not used";
VAL_ 1227 AmbiLightADLINKTypeStatus 0 "Unavailable" 1 "Type1" 2 "Type2" 3 "Type3";
VAL_ 1227 AmbiLightADColorStatus 0 "Color 1" 1 "Color 2" 2 "Color 3" 3 "Color 4" 4 "Color 5" 5 "Color 6" 6 "Color 7" 7 "Color 8" 8 "Color 9" 9 "Color 10" 10 "Color 11" 11 "Color 12" 12 "Color 13" 13 "Color 14" 14 "Color 15" 15 "Color 16" 16 "Color 17" 17 "Color 18" 18 "Color 19" 19 "Color 20" 20 "Color 21" 21 "Color 22" 22 "Color 23" 23 "Color 24" 24 "Color 25" 25 "Color 26" 26 "Color 27" 27 "Color 28" 28 "Color 29" 29 "Color 30" 30 "Color 31" 31 "Color 32" 32 "Color 33" 33 "Color 34" 34 "Color 35" 35 "Color 36" 36 "Color 37" 37 "Color 38" 38 "Color 39" 39 "Color 40" 40 "Color 41" 41 "Color 42" 42 "Color 43" 43 "Color 44" 44 "Color 45" 45 "Color 46" 46 "Color 47" 47 "Color 48" 48 "Color 49" 49 "Color 50" 50 "Color 51" 51 "Color 52" 52 "Color 53" 53 "Color 54" 54 "Color 55" 55 "Color 56" 56 "Color 57" 57 "Color 58" 58 "Color 59" 59 "Color 60" 60 "Color 61" 61 "Color 62" 62 "Color 63" 63 "Color 64" 64 "Color 65" 65 "Color 66" 66 "Color 67" 67 "Color 68" 68 "Color 69" 69 "Color 70" 70 "Color 71" 71 "Color 72" 72 "Color 73" 73 "Color 74" 74 "Color 75" 75 "Color 76" 76 "Color 77" 77 "Color 78" 78 "Color 79" 79 "Color 80" 80 "Color 81" 81 "Color 82" 82 "Color 83" 83 "Color 84" 84 "Color 85" 85 "Color 86" 86 "Color 87" 87 "Color 88" 88 "Color 89" 89 "Color 90" 90 "Color 91" 91 "Color 92" 92 "Color 93" 93 "Color 94" 94 "Color 95" 95 "Color 96" 96 "Color 97" 97 "Color 98" 98 "Color 99" 99 "Color 100" 100 "Color 101" 101 "Color 102" 102 "Color 103" 103 "Color 104" 104 "Color 105" 105 "Color 106" 106 "Color 107" 107 "Color 108" 108 "Color 109" 109 "Color 110" 110 "Color 111" 111 "Color 112" 112 "Color 113" 113 "Color 114" 114 "Color 115" 115 "Color 116" 116 "Color 117" 117 "Color 118" 118 "Color 119" 119 "Color 120" 120 "Color 121" 121 "Color 122" 122 "Color 123" 123 "Color 124" 124 "Color 125" 125 "Color 126" 126 "Color 127" 127 "Color 128";
VAL_ 1227 ESSU_StateDisplay 0 "No display" 1 "Roof Transparent" 2 "Roof Opaque" 3 "Front Roof Transparent" 4 "Front Roof Opaque" 5 "Rear Roof Transparent" 6 "Rear Roof Opaque" 7 "Wait Before Roof Use" 8 "Reserved" 9 "Not used" 10 "Not used" 11 "Not used" 12 "Not used" 13 "Not used" 14 "Not used" 15 "Not used";
VAL_ 1232 ManualBatteryWarmingSWRestart 0 "Manual battery warming switch disabled" 1 "Manual battery warming switch restart";
VAL_ 1232 HVbatQCPreheatingOffState 0 "Battery Preheating OFF" 1 "Battery Preheating ON";
VAL_ 1233 FrontWasherPumpActivationReq 0 "front washer pump not requested" 1 "front washer pump requested";
VAL_ 1234 SWSHighlight_AutoHide 0 "False" 1 "True";
VAL_ 1234 AVM_selection_status 0 "False" 1 "False TEMP" 2 "True" 3 "Not Used";
VAL_ 1247 GeneralRecordingStatus_v2 0 "turn on" 1 "turn off" 2 "Not used" 3 "Unavailable";
VAL_ 1247 WiFiStatus_v2 0 "turn on" 1 "turn off" 2 "Not used" 3 "Unavailable";
VAL_ 1247 UpdateStatus_Command_Response 0 "Success implementation" 1 "Execution failure" 2 "Reserved" 3 "Unavailable value";
VAL_ 1247 RecordVideoQuality_HSL 0 "High" 1 "Standard" 2 "Long time" 3 "invalid value";
VAL_ 1247 ComandResp_fileExport 0 "Stop export file" 1 "Export files" 2 "Reserved" 3 "Unavailable value";
VAL_ 1247 DVR_CommandRespList_Passenger 0 "enter general video" 1 "stop recorded" 2 "enter emergency video" 3 "enter general video directory" 4 "enter emergency video directory" 5 "enter picture directory" 6 "format SD" 7 "factory reset" 8 "photograph" 9 "enter inner camera" 10 "deleted file" 11 "turn on video" 12 "play/pause" 13 "enter passenger monitor" 14 "play the previous file" 15 "play the next file" 16 "exit play" 17 "filesselected 1" 18 "filesselected 2" 19 "filesselected 3" 20 "filesselected 4" 21 "filesselected 5" 22 "filesselected 6" 23 "filesselected 7" 24 "filesselected 8" 25 "passenger monitor mute" 26 "select all" 27 "cancel" 28 "previous" 29 "next" 30 "Enable Updata" 31 "invalid value";
VAL_ 1247 INcamWrongModeWarning 0 "INCAM shall change to RGB mode" 1 "INCAM shall change to IR mode" 2 "Not Used" 3 "Invalid value";
VAL_ 1247 INcamModeStatus 0 "Auto Mode and work in IR" 1 "Auto Mode and work in RGB" 2 "Always Color Mode" 3 "Always IR Mode" 4 "Not Used" 5 "Not Used" 6 "Not Used" 7 "Invalid value";
VAL_ 1247 DVR_EthernetStatus 0 "Network connected" 1 "Network connecting" 2 "Network connection failure" 3 "Network abnormal disconnected" 4 "EthernetPHY Initialization failure" 5 "Not Used" 6 "Not Used" 7 "Invalid value";
VAL_ 1247 SuperpositionOSDShow 0 "turn off overlay display" 1 "turn on overlay display" 2 "Not used" 3 "Unavailable value";
VAL_ 1247 RRCameraStatus 0 "RR CAM general recording" 1 "RR CAM emergency recording" 2 "RR CAM User taking video" 3 "RR CAM stop recording" 4 "RR CAM ERROR" 5 "RR CAM not installed" 6 "Invalid value" 7 "Unavailable value";
VAL_ 1247 INCameraStatus 0 "IN CAM User taking video" 1 "IN CAM normal" 2 "IN CAM ERROR" 3 "IN CAM not installed" 4 "Not Used" 5 "Not Used" 6 "Not Used" 7 "Invalid value";
VAL_ 1247 UsageCounterOfDVRRemote 0 "1" 1 "2" 2 "3" 3 "4" 4 "5" 5 "6" 6 "Not Used" 7 "Unavailable value";
VAL_ 1247 eMMCStatus 0 "Normal" 1 "Write protection" 2 "Failure" 3 "Unavailable value";
VAL_ 1247 FRCameraStatus 0 "FR CAM general recording" 1 "FR CAM emergency recording" 2 "FR CAM User taking video" 3 "FR CAM stop recording" 4 "FR CAM ERROR" 5 "Power down" 6 "System failure" 7 "Unavailable value";
VAL_ 1247 FilesExportingStatus 0 "Unavailable value" 1 "Some files under exporting";
VAL_ 1247 UpgradeProgress 0 "Table Value430667";
VAL_ 1247 Diary_mode_status 0 "OFF" 1 "ON" 2 "Invalid value" 3 "Not used";
VAL_ 1251 Rear3RightSeatFoldUnfoldState 0 "fixed position" 1 "on going" 2 "not used" 3 "unavailable";
VAL_ 1251 Rear3LeftSeatFoldUnfoldState 0 "fixed position" 1 "on going" 2 "not used" 3 "unavailable";
VAL_ 1251 Rear3RightSeatMovingState 0 "Not moving" 1 "During folding" 2 "During unfolding" 3 "Not used";
VAL_ 1251 Rear3LeftSeatMovingState 0 "Not moving" 1 "During folding" 2 "During unfolding" 3 "Not used";
VAL_ 1255 DVR_CamView_Change 0 "No change view from current status" 1 "Change view" 2 "Not used" 3 "Not used";
VAL_ 1255 MMI_CommandList_Passenger 0 "enter general video" 1 "stop recorded" 2 "enter emergency video" 3 "enter general video directory" 4 "enter emergency video directory" 5 "enter picture directory" 6 "format SD" 7 "factory reset" 8 "photograph" 9 "enter inner camera" 10 "deleted file" 11 "turn on video" 12 "play/pause" 13 "enter passenger monitor" 14 "play the previous file" 15 "play the next file" 16 "exit play" 17 "filesselected 1" 18 "filesselected 2" 19 "filesselected 3" 20 "filesselected 4" 21 "filesselected 5" 22 "filesselected 6" 23 "filesselected 7" 24 "filesselected 8" 25 "passenger monitor mute" 26 "select all" 27 "cancel" 28 "previous" 29 "next" 30 "Enable Updata" 31 "invalid value";
VAL_ 1255 SetINcamMode 0 "Auto Mode" 1 "Always Color Mode" 2 "Always IR Mode" 3 "invalid value";
VAL_ 1255 EN_SuperpositionOSDShow 0 "turn off overlay display" 1 "turn on overlay display" 2 "Not used" 3 "Unavailable value";
VAL_ 1255 WiFiInfoDisplayRequest 0 "Request to send SSID and Password" 1 "No request" 2 "Invalid value" 3 "Unavailable value";
VAL_ 1255 CommandfileExport 0 "Stop export file" 1 "Export files" 2 "Reserved" 3 "Unavailable value";
VAL_ 1255 IVI_VK_Menu_operation 0 "No operation" 1 "Menu operation" 2 "Operation cancel" 3 "Owner key registration start condition check" 4 "Owner key registration start" 5 "Owner key change start condition check" 6 "Owner key change start" 7 "Owner key termination start" 8 "Friend key ID1 termination start" 9 "Friend key ID2 termination start" 10 "Friend key ID3 termination start" 11 "Friend key ID4 termination start" 12 "Friend key ID5 termination start" 13 "Friend key all termination start" 14 "Friend key list" 15 "reserved" 16 "reserved" 17 "reserved" 18 "reserved" 19 "reserved" 20 "reserved" 21 "reserved" 22 "reserved" 23 "reserved" 24 "reserved" 25 "reserved" 26 "reserved" 27 "reserved" 28 "reserved" 29 "reserved" 30 "reserved" 31 "Unavailable value";
VAL_ 1255 ISA_IVIFailureStatus 0 "Unavailable Value" 1 "No Failure" 2 "System Failure" 3 "MapUpdateFail" 4 "NoMapAvailable" 5 "LicenseExpired" 6 "Reserved" 7 "Reserved";
VAL_ 1255 CRS_PresenceState 0 "Absent" 1 "Present" 2 "Bluetooth Disconnected" 3 "Unavailable";
VAL_ 1255 IVI_RPKMode 0 "RPK Mode OFF" 1 "RPK Mode ON";
VAL_ 1255 Diary_mode_request 0 "OFF" 1 "ON" 2 "Invalid value" 3 "Not used";
VAL_ 1255 IVI_AVMSettingRequest 0 "Not Requested" 1 "AVM Setting";
VAL_ 1255 BatteryCool_eACLimitStatus_IVI 0 "No request" 1 "Uncap request" 2 "No uncap request" 3 "Not used";
VAL_ 1276 BCI_ActivationState 0 "Activated" 1 "Deactivated";
VAL_ 1276 ACC_Status_Slow 0 "ACC OFF" 1 "ACC in take off" 2 "ACC in stop" 3 "ACC waiting" 4 "ACC suspended" 5 "ACC in brake only mode" 6 "ACC regulation" 7 "ACC driver override" 8 "ACC in failure State" 9 "Not used" 10 "Not used" 11 "Not used" 12 "Not used" 13 "Not used" 14 "Not used" 15 "Unavailable";
VAL_ 1277 CAV_Position_FeedBack_EVA 0 "unavailable" 1 "Position 1 - Closed" 2 "Position 2" 3 "Position 3" 4 "Position 4" 5 "Position 5" 6 "Position 6 - Open" 7 "Unknown position";
VAL_ 1278 ELKA_ChoiceState 0 "Selected" 1 "Not selected";
VAL_ 1278 CustomShieldMenuShortCut 0 "No request" 1 "Shortcut request";
VAL_ 1278 BSWson_ChoiceState 0 "Selected" 1 "Not selected";
VAL_ 1278 BSWrad_ChoiceState 0 "Selected" 1 "Not selected";
VAL_ 1278 ADAS_Shield_Status 0 "FullShield" 1 "Not Full Shield";
VAL_ 1278 OverspeedAlertChoiceState 0 "Selected" 1 "Not selected";
VAL_ 1278 LDWLKA_ChoiceState 0 "Selected" 1 "Not selected";
VAL_ 1278 Distraction_ChoiceState 0 "Selected" 1 "Not selected";
VAL_ 1278 Fatigue_ChoiceState 0 "Selected" 1 "Not selected";
VAL_ 1278 WDA_ChoiceState 0 "Selected" 1 "Not selected";
VAL_ 1279 DriverTiltMovingReq 0 "no request" 1 "upward moving request" 2 "downward moving request" 3 "not used";
VAL_ 1279 DriverLifterMovingReq 0 "no request" 1 "upward moving request" 2 "downward moving request" 3 "not used";
VAL_ 1279 DriverReclinerMovingReq 0 "no request" 1 "forward moving request" 2 "backward moving request" 3 "not used";
VAL_ 1279 DriverSlideMovingReq 0 "no request" 1 "forward moving request" 2 "backward moving request" 3 "not used";
VAL_ 1279 PsSlideMovingReq 0 "no request" 1 "forward moving request" 2 "backward moving request" 3 "not used";
VAL_ 1279 DriverBacksidebolsterMovingReq 0 "no request" 1 "inflate request" 2 "deflate request" 3 "not used";
VAL_ 1279 DriverLumbarMovingReq_Z_Axis 0 "no request" 1 "upward moving request" 2 "downward moving request" 3 "not used";
VAL_ 1279 DriverLumbarMovingReq_X_Axis 0 "no request" 1 "forward moving request" 2 "backward moving request" 3 "not used";
VAL_ 1279 PsLumbarMovingReq_X_Axis 0 "no request" 1 "forward moving request" 2 "backward moving request" 3 "not used";
VAL_ 1279 PsTiltMovingReq 0 "no request" 1 "upward moving request" 2 "downward moving request" 3 "not used";
VAL_ 1279 PsLifterMovingReq 0 "no request" 1 "upward moving request" 2 "downward moving request" 3 "not used";
VAL_ 1279 PsReclinerMovingReq 0 "no request" 1 "forward moving request" 2 "backward moving request" 3 "not used";
VAL_ 1279 Rear2RightSeatFoldUnfoldReq 0 "No request" 1 "Fold request" 2 "Unfold request" 3 "Stop request";
VAL_ 1279 Rear2LeftSeatFoldUnfoldReq 0 "No request" 1 "Fold request" 2 "Unfold request" 3 "Stop request";
VAL_ 1279 PsBacksidebolsterMovingReq 0 "no request" 1 "inflate request" 2 "deflate request" 3 "not used";
VAL_ 1279 PsLumbarMovingReq_Z_Axis 0 "no request" 1 "upward moving request" 2 "downward moving request" 3 "not used";
VAL_ 1279 Rear2RightSeatWalkinReq 0 "No request" 1 "Walkin request" 2 "Return request" 3 "Stop request";
VAL_ 1279 Rear2LeftSeatWalkinReq 0 "No request" 1 "Walkin request" 2 "Return request" 3 "Stop request";
VAL_ 1279 Rear3RightSeatFoldUnfoldReq 0 "No request" 1 "Fold request" 2 "Unfold request" 3 "Stop request";
VAL_ 1279 Rear3LeftSeatFoldUnfoldReq 0 "No request" 1 "Fold request" 2 "Unfold request" 3 "Stop request";
VAL_ 1279 ThirdRowLeftSeatAutoRequest 0 "No request" 1 "Auto mode activation" 2 "Auto mode deactivation" 3 "reset request";
VAL_ 1279 ThirdRowRightSeatAutoRequest 0 "No request" 1 "Auto mode activation" 2 "Auto mode deactivation" 3 "reset request";
VAL_ 1282 BSWson_ActivationState 0 "BSW not activated" 1 "BSW activated";
VAL_ 1282 SonarSystemPauseStatus 0 "System Pause Off" 1 "System Pause On";
VAL_ 1282 ParkAssistSensitivityStatus 0 "Unavailable" 1 "Far Range Detection" 2 "Middle Range Detection " 3 "Near Range Detection";
VAL_ 1282 FrontParkAssistState 0 "Front park assistance de-activated" 1 "Front park assistance activated";
VAL_ 1282 RearParkAssistState 0 "Rear park assistance de-activated" 1 "Rear park assistance activated";
VAL_ 1282 SonarAutoDisplayState 0 "Unavailable" 1 "Auto Display Activation" 2 "Auto Display Deactivation" 3 "Not used";
VAL_ 1284 HVbatQCPreheatingState 0 "No message" 1 "Message01" 2 "Message02" 3 "Message03";
VAL_ 1284 HVBatChargeIncreaseCancel 0 "Not cancelled" 1 "Cancelled";
VAL_ 1284 HVBatCoolingSaveCancel 0 "Not cancelled" 1 "Cancelled";
VAL_ 1284 HVBatChargeIncreaseState 0 "No message" 1 "Message01" 2 "Message02" 3 "Message03";
VAL_ 1284 HVBatCoolingSaveState 0 "No message" 1 "Message01" 2 "Message02" 3 "Message03";
VAL_ 1292 MultimediaSWupdateDisplay 0 "No display" 1 "Update on going 0%" 2 "Update on going 25%" 3 "Update on going 50%" 4 "Update on going 75%" 5 "Update on going 100%" 6 "Not Used" 7 "Not Used";
VAL_ 1292 SportUsageRequest2 0 "No request" 1 "Auto request" 2 "Forced request" 3 "Reset request";
VAL_ 1292 ScreenDriverSaveModeRequest 0 "No Request" 1 "E save not actived" 2 "E save actived" 3 "reset";
VAL_ 1292 SafeScore_AdviceMessage 0 "No Message" 1 "Message 1" 2 "Message 2" 3 "Message 3" 4 "Message 4" 5 "Message 5" 6 "Message 6" 7 "Message 7" 8 "Message 8" 9 "Message 9" 10 "Message 10" 11 "Not used" 12 "Not used" 13 "Not used" 14 "Not used" 15 "Unavailable";
VAL_ 1294 VirtualKeyMenuState 0 "Not used" 1 "Activate Menu" 2 "Deactivate Menu" 3 "Not used";
VAL_ 1295 DriverMassageProgramReq_v2 0 "No request" 1 "Program 1 requested" 2 "Program 2 requested" 3 "Program 3 requested" 4 "Program 4 requested" 5 "Program 5 requested" 6 "Program 6 requested" 7 "Program 7 requested" 8 "Program 8 requested" 9 "Program 9 requested" 10 "Program 10 requested" 11 "Program 11 requested" 12 "Program 12 requested" 13 "Program 13 requested" 14 "Program 14 requested" 15 "Reset request";
VAL_ 1295 SET_ALCP2P_AlertLevel_Request2 0 "No request" 1 "Lv1" 2 "Lv2" 3 "Lv3" 4 "Reset request" 5 "Not used" 6 "Not used" 7 "Not used";
VAL_ 1295 OtherLampActivateRequest 0 "Deactivation" 1 "Activation" 2 "Reset request" 3 "Unavailable";
VAL_ 1295 PassengerMassageProgramReq_v2 0 "No request" 1 "Program 1 requested" 2 "Program 2 requested" 3 "Program 3 requested" 4 "Program 4 requested" 5 "Program 5 requested" 6 "Program 6 requested" 7 "Program 7 requested" 8 "Program 8 requested" 9 "Program 9 requested" 10 "Program 10 requested" 11 "Program 11 requested" 12 "Program 12 requested" 13 "Program 13 requested" 14 "Program 14 requested" 15 "Reset request";
VAL_ 1295 AmbientADLinkRequest 0 "No Request" 1 "AD LINK activation requested" 2 "AD LINK deactivation requested" 3 "Reset";
VAL_ 1295 HVbatteryCoolingActivationReq2 0 "No request" 1 "Battery cooling activation Request" 2 "Battery cooling desactivation Request" 3 "Reset to factory value";
VAL_ 1295 SET_AD_HandsOff_Request2 0 "No request" 1 "Activation" 2 "Deactivation" 3 "Reset request";
VAL_ 1295 SET_ALC_AssistMode_Request2 0 "No request" 1 "Successive" 2 "Individual" 3 "Reset request";
VAL_ 1295 AmbientLightingArea5Req 0 "No Request" 1 "AmbientLighting Area 5 requested" 2 "AmbientLighting Area 5 not requested" 3 "Reset Request";
VAL_ 1295 SET_ADL3Activation_Request2 0 "No request" 1 "Activation" 2 "Deactivation" 3 "Reset Request";
VAL_ 1295 RearRightMassageActivationReq 0 "No request" 1 "Activation request" 2 "Deactivation request" 3 "Reset Request";
VAL_ 1295 RearRightAutoReturnReq 0 "No request" 1 "Activation request" 2 "Deactivation request" 3 "Not Used";
VAL_ 1295 RearLeftMassageActivationReq 0 "No request" 1 "Activation request" 2 "Deactivation request" 3 "Reset Request";
VAL_ 1295 RearLeftAutoReturnReq 0 "No request" 1 "Activation request" 2 "Deactivation request" 3 "Not Used";
VAL_ 1295 FrWiper_ServPos_Request 0 "No request" 1 "Set Front Service Position Requested" 2 "Unset Front Service Position Requested" 3 "Not used";
VAL_ 1295 AES_ActivationRequest2 0 "No request" 1 "Activation request" 2 "De-activation request" 3 "Reset Request";
VAL_ 1295 VR_RrWipingRequest 0 "No Request" 1 "Mist Request" 2 "INT Request" 3 "Not used" 4 "On Continuous Request" 5 "Not used" 6 "Wash Request" 7 "OFF Request";
VAL_ 1295 VR_FrWipingRequest 0 "No Request" 1 "Mist Request" 2 "INT Request" 3 "Auto Request" 4 "LowSpeed Request" 5 "HighSpeed Request" 6 "Wash Request" 7 "OFF Request";
VAL_ 1295 RrWiper_ServPos_Request 0 "No request" 1 "Activation requested" 2 "De-activation requested" 3 "Not used";
VAL_ 1296 TCU_DVR_Photo_Request 0 "no request" 1 "request";
VAL_ 1296 IVI_SafeMode 0 "Not activated" 1 "Activated";
VAL_ 1296 IVI_SafeModePersistentON 0 "Persistent mode disabled" 1 "Persistent mode enabled";
VAL_ 1296 IVI_SafeModeRebootReason 0 "No message to user" 1 "Display message 1" 2 "Display message 2" 3 "Display message 3" 4 "Display message 4" 5 "Display message 5" 6 "Display message 6" 7 "Display message 7";
VAL_ 1296 Heavy_crash_activate 0 "Unavailable" 1 "Heavy crash activate";
VAL_ 1298 AVM_ClosingAuthorization_2 0 "Not authorized" 1 "Authorized";
VAL_ 1298 AVM_LayoutDisplayRequest_2 0 "No message" 1 "Layout 1" 2 "Layout 2" 3 "Layout 3" 4 "Layout 4" 5 "Layout 5" 6 "Layout 6" 7 "Layout 7" 8 "Layout 8" 9 "Layout 9" 10 "Layout 10" 11 "Layout 11" 12 "Layout 12" 13 "Layout 13" 14 "Layout 14" 15 "Layout 15" 16 "Layout 16" 17 "Layout 17" 18 "Layout 18" 19 "Layout 19" 20 "Layout 20" 21 "Layout 21" 22 "Layout 22" 23 "Layout 23" 24 "Layout 24" 25 "Layout 25" 26 "Layout 26" 27 "Layout 27" 28 "Layout 28" 29 "Layout 29" 30 "Layout 30" 31 "Layout 31";
VAL_ 1298 AVM_LayoutVideoStatus_2 0 "No display" 1 "Layout 1" 2 "Layout 2" 3 "Layout 3" 4 "Layout 4" 5 "Layout 5" 6 "Layout 6" 7 "Layout 7" 8 "Layout 8" 9 "Layout 9" 10 "Layout 10" 11 "Layout 11" 12 "Layout 12" 13 "Layout 13" 14 "Layout 14" 15 "Layout 15" 16 "Layout 16" 17 "Layout 17" 18 "Layout 18" 19 "Layout 19" 20 "Layout 20" 21 "Layout 21" 22 "Layout 22" 23 "Layout 23" 24 "Layout 24" 25 "Layout 25" 26 "Layout 26" 27 "Layout 27" 28 "Layout 28" 29 "Layout 29" 30 "Layout 30" 31 "Layout 31";
VAL_ 1298 AVM_WarningDisplayRequest_2 0 "No message" 1 "Message 1" 2 "Message 2" 3 "Message 3" 4 "Message 4" 5 "Message 5" 6 "Message 6" 7 "Message 7";
VAL_ 1299 FKP_ObstacleZone_RF 0 "No detection" 1 "Detect level 1" 2 "Detect level 2" 3 "Detect level 3";
VAL_ 1299 FKP_ObstacleZone_LRC 0 "No detection" 1 "Detect level 1" 2 "Detect level 2" 3 "Detect level 3";
VAL_ 1299 FKP_ObstacleZone_LFC 0 "No detection" 1 "Detect level 1" 2 "Detect level 2" 3 "Detect level 3";
VAL_ 1299 FKP_ObstacleZone_LF 0 "No detection" 1 "Detect level 1" 2 "Detect level 2" 3 "Detect level 3";
VAL_ 1299 FKP_ObstacleZone_RRC 0 "No detection" 1 "Detect level 1" 2 "Detect level 2" 3 "Detect level 3";
VAL_ 1299 FKP_ObstacleZone_RR 0 "No detection" 1 "Detect level 1" 2 "Detect level 2" 3 "Detect level 3";
VAL_ 1299 FKP_ObstacleZone_RL 0 "No detection" 1 "Detect level 1" 2 "Detect level 2" 3 "Detect level 3";
VAL_ 1299 FKP_ObstacleZone_RFC 0 "No detection" 1 "Detect level 1" 2 "Detect level 2" 3 "Detect level 3";
VAL_ 1299 FKP_FrontMiddleL_Scan 0 "Area Not Scanned" 1 "Area Scanned";
VAL_ 1299 FKP_FrontMiddleR_Hatch 0 "Area Not Hatched" 1 "Area Hatched";
VAL_ 1299 FKP_FrontMiddleL_Hatch 0 "Area Not Hatched" 1 "Area Hatched";
VAL_ 1299 FKP_FrontFrontR_Scan 0 "Area Not Scanned" 1 "Area Scanned";
VAL_ 1299 FKP_FrontFrontR_Hatch 0 "Area Not Hatched" 1 "Area Hatched";
VAL_ 1299 FKP_FrontFrontL_Scan 0 "Area Not Scanned" 1 "Area Scanned";
VAL_ 1299 FKP_ImageDisplayRequest 0 "Display NOT requested" 1 "Display requested";
VAL_ 1299 FKP_FrontMiddleR_Scan 0 "Area Not Scanned" 1 "Area Scanned";
VAL_ 1299 FKP_RearRearR_Scan 0 "Area Not Scanned" 1 "Area Scanned";
VAL_ 1299 FKP_RearRearR_Hatch 0 "Area Not Hatched" 1 "Area Hatched";
VAL_ 1299 FKP_RearRearL_Scan 0 "Area Not Scanned" 1 "Area Scanned";
VAL_ 1299 FKP_RearRearL_Hatch 0 "Area Not Hatched" 1 "Area Hatched";
VAL_ 1299 FKP_RearMiddleR_Scan 0 "Area Not Scanned" 1 "Area Scanned";
VAL_ 1299 FKP_RearMiddleR_Hatch 0 "Area Not Hatched" 1 "Area Hatched";
VAL_ 1299 FKP_RearMiddleL_Scan 0 "Area Not Scanned" 1 "Area Scanned";
VAL_ 1299 FKP_RearMiddleL_Hatch 0 "Area Not Hatched" 1 "Area Hatched";
VAL_ 1299 FKP_FrontFrontL_Hatch 0 "Area Not Hatched" 1 "Area Hatched";
VAL_ 1299 UPA_RearRight_Hatch 0 "Area Not Hatched" 1 "Area Hatched";
VAL_ 1299 UPA_RearMiddle_Hatch 0 "Area Not Hatched" 1 "Area Hatched";
VAL_ 1299 UPA_RearLeft_Hatch 0 "Area Not Hatched" 1 "Area Hatched";
VAL_ 1299 UPA_FrontRight_Hatch 0 "Area Not Hatched" 1 "Area Hatched";
VAL_ 1299 UPA_FrontMiddle_Hatch 0 "Area Not Hatched" 1 "Area Hatched";
VAL_ 1299 UPA_FrontLeft_Hatch 0 "Area Not Hatched" 1 "Area Hatched";
VAL_ 1299 FKP_ActivationStatus 0 "Flank Protection NOT activated" 1 "Flank Protection activated";
VAL_ 1303 OverSpeedWarningSound 0 "Not requested" 1 "Requested";
VAL_ 1303 RainSymbolDisplayRequest 0 "No Rain Symbol Display Request" 1 "Rain Symbol Display Request";
VAL_ 1303 TSR_OSP_SpeedSignalZone1 254 "Free speed' Symbol" 255 "No Speed available show ---";
VAL_ 1303 TSR_OSP_ActivationStatus 0 "Unavailable" 1 "TSR/OSP Activated" 2 "TSR/OSP Not Activated" 3 "Not used";
VAL_ 1303 OSPOverSpeedDisplayRequest 0 "No Overspeed alert" 1 "OverSpeedAlert";
VAL_ 1310 CartoData 0 "Table Value16337";
VAL_ 1310 OSPDataType 0 "Reserved" 1 "POSITION" 2 "SEGMENT" 3 "STUB" 4 "PROFILE SHORT" 5 "PROFILE LONG" 6 "META-DATA" 7 "Reserved";
VAL_ 1313 MOIS_ActivationState 0 "Activated" 1 "Deactivated";
VAL_ 1313 MOIS_MuteActivationState 0 "Mute" 1 "Unmute";
VAL_ 1318 TripComputer_ResetRequest 0 "Reset OnBoardComputer not requested" 1 "Reset OnBoardComputer requested";
VAL_ 1318 LDW_SoundLevelState_v2 0 "Level 0" 1 "Level 1" 2 "Level 2" 3 "Level 3" 4 "Level 4" 5 "Level 5" 6 "Not Used" 7 "Not Used";
VAL_ 1318 RESPreSoak_ProgReq_MMI 0 "No Timer" 1 "Start Timer Request - one time (RES or Presoak)" 2 "Start Timer Request - every two hours (5 times max)" 3 "Not used";
VAL_ 1318 ESE_Soundvolume_Request 0 "No request" 1 "0" 2 "Low" 3 "High" 4 "1" 5 "2" 6 "3" 7 "4" 8 "5" 9 "6" 10 "7" 11 "8" 12 "9" 13 "10" 14 "11" 15 "12" 16 "13" 17 "14" 18 "Not used" 19 "Not used" 20 "Not used" 21 "Not used" 22 "Not used" 23 "Not used" 24 "Not used" 25 "Not used" 26 "Not used" 27 "Not used" 28 "Not used" 29 "Not used" 30 "Not used" 31 "Reset request";
VAL_ 1318 HFP_SelectedManeuverTypeRequest 0 "no request" 1 "park in / parallel" 2 "park in / perpendicular" 3 "park in / angled" 4 "park out" 5 "Not used" 6 "Not used" 7 "Not used";
VAL_ 1318 ESE_Soundtype_Request 0 "No Request" 1 "Neutral" 2 "Sound 1" 3 "Sound2" 4 "RSound1" 5 "RSound2" 6 "RSound3" 7 "RSound4" 8 "RSound5" 9 "RSound6" 10 "Not used" 11 "Not used" 12 "Not used" 13 "Not used" 14 "Not used" 15 "Reset Request";
VAL_ 1319 ADTutorial_GuideDisplay 0 "No display" 1 "Recommend using AD (2steps)" 2 "Recommend using AD (1step)" 3 "Not Used";
VAL_ 1320 NAVI_Matching_RoutePlan 0 "Not Matching" 1 "Matching";
VAL_ 1321 SetParkingMonitor 0 "turn off parking monitoring" 1 "turn on parking monitoring" 2 "reserved" 3 "invalid value";
VAL_ 1321 SetRecordQuality 0 "1080P-30fps" 1 "720P-30fps" 2 "reserved" 3 "invalid value";
VAL_ 1321 MuteRecordSet 0 "turn off recording" 1 "turn on recording" 2 "reserved" 3 "invalid value";
VAL_ 1321 RecordTimeSet 0 "1min" 1 "3min" 2 "5min" 3 "invalid value";
VAL_ 1321 SetCollideSensitivity 0 "low sensibility" 1 "medium sensibility" 2 "high sensibility" 3 "invalid value";
VAL_ 1321 SetCollideCheck 0 "turn off collision detection" 1 "turn on collision detection" 2 "reserved" 3 "invalid value";
VAL_ 1321 FilePlayNum 0 "Reserved" 1 "Play file 1" 2 "Play file 2" 3 "Play file 3" 4 "Play file 4" 5 "Play file 5" 6 "Play file 6" 7 "Play file 7" 8 "Play file 8" 9 "Play file 9" 10 "Reserved" 11 "Reserved" 12 "Reserved" 13 "Reserved" 14 "Reserved" 15 "Invalid value";
VAL_ 1321 EN_SuperpositionOthersShow 0 "turn off overlay display" 1 "turn on overlay display" 2 "reserved" 3 "invalid value";
VAL_ 1321 EN_SuperpositionSpeedShow 0 "turn off overlay display" 1 "turn on overlay display" 2 "reserved" 3 "invalid value";
VAL_ 1321 GPSClockStatus 0 "DA Clock" 1 "GPS Clock";
VAL_ 1321 GatherPhoto 0 "screenshot completed, save to disk" 1 "screenshot completed, without saving" 2 "reserved" 3 "invalid value";
VAL_ 1321 MMI_CommandList 0 "enter general video" 1 "stop recorded" 2 "enter emergency video" 3 "enter general video directory" 4 "enter emergency video directory" 5 "enter picture directory" 6 "format SD" 7 "factory reset" 8 "photograph" 9 "move file" 10 "deleted file" 11 "turn on video" 12 "play/pause" 13 "format eMMC (reserved)" 14 "play the previous file" 15 "play the next file" 16 "exit play" 17 "filesselected 1" 18 "filesselected 2" 19 "filesselected 3" 20 "filesselected 4" 21 "filesselected 5" 22 "filesselected 6" 23 "filesselected 7" 24 "filesselected 8" 25 "filesselected 9" 26 "select all" 27 "cancel" 28 "previous" 29 "next" 30 "Enable Update" 31 "invalid value";
VAL_ 1321 TransportContent 0 "SSID" 1 "Password" 2 "reserved" 3 "invalid value";
VAL_ 1325 NAVI_BranchMultipleInfo 0 "No branch or Single branch" 1 "Multiple branch";
VAL_ 1325 NAVI_BranchDirection 0 "No Branch" 1 "Left Branch" 2 "Right Branch" 3 "Not Used";
VAL_ 1325 NaviGPS_PositioningStatus 0 "Normal" 1 "not Normal";
VAL_ 1325 NAVI_Matching_Status 0 "Not matching" 1 "matching";
VAL_ 1325 NAVI_MatchingReset 0 "Not reset" 1 "Reset";
VAL_ 1325 NAVI_LinkFailure 0 "Not existing Link failure" 1 "Existing Link failure";
VAL_ 1325 NAVI_TurningStatus 0 "Not Turning" 1 "Turning";
VAL_ 1325 NAVI_CurvatureError 0 "No error" 1 "Error";
VAL_ 1325 NAVI_PrivacyModeStatus 0 "Probe Upload OFF (=Privacy ON)" 1 "Probe Upload ON (=Privacy OFF)" 2 "Probe Clear and Probe Upload OFF (=Privacy ON)" 3 "Probe Clear and Probe Upload ON (=Privacy ON)";
VAL_ 1325 InGuidingRoute 0 "not in the guiding route" 1 "in the guiding route";
VAL_ 1325 Current_Roadtype 0 "intercity expressway" 1 "urban expressway" 2 "toll road" 3 "national road" 4 "prefectural road" 5 "principal prefectural road" 6 "general road" 7 "other";
VAL_ 1325 RouteGuiding_flag 0 "OFF" 1 "ON";
VAL_ 1325 Current_Linktype 0 "Up-down inseparable link" 1 "Up-down separable link" 2 "Junction link 1" 3 "Junction link 2" 4 "Side road same line as mainroad" 5 "Lateral line for SA" 6 "Rotary link" 7 "other";
VAL_ 1326 SecondRowCtrRightSafetyBeltState 0 "SB not monitored" 1 "SB unfastened" 2 "SB fastened" 3 "Unavailable";
